VERSION ""

NS_ :

BS_:

BU_: External_Tool ADAS RDR05 RDR_Fusion_Partner RDR_Gateway

BO_ 267 RDR_FUSION_DET_045_048: 64 RDR_Fusion_Partner
 SG_ DET_RANGE_045_Rx : 24|15@1+ (0.015625,0) [0|500] "m"  RDR05
 SG_ DET_RANGE_ERR_045_Rx : 40|7@1+ (0.0075,0) [0|0.9525] "m"  RDR05
 SG_ DET_RANGE_VELOCITY_045_Rx : 48|15@1+ (0.0078125,-128) [-128|127.9921875] "m/s"  RDR05
 SG_ DET_RANGE_VELOCITY_ERR_045_Rx : 64|8@1+ (0.003,0) [0|0.765] "m/s"  RDR05
 SG_ DET_AZIMUTH_045_Rx : 88|13@1+ (0.0004,-1.5708) [-1.5708|1.5708] "rad"  RDR05
 SG_ DET_AZIMUTH_ERR_045_Rx : 105|7@1+ (0.00087267,0) [0|0.11082909] "rad"  RDR05
 SG_ DET_ELEVATION_045_Rx : 72|8@1+ (0.00275,-0.34925) [-0.34925|0.34925] "rad"  RDR05
 SG_ DET_ELEVATION_ERR_045_Rx : 80|6@1+ (0.00174533,0) [0|0.10995579] "rad"  RDR05
 SG_ DET_RCS_045_Rx : 128|8@1+ (0.5,-64) [-64|63.5] "dBsm"  RDR05
 SG_ DET_BI_STATIC_FLAG_045_Rx : 104|1@1+ (1,0) [0|1] ""  RDR05
 SG_ DET_SUPER_RES_TARGET_045_Rx : 87|1@1+ (1,0) [0|1] ""  RDR05
 SG_ DET_SNR_045_Rx : 120|8@1+ (0.35156,0) [0|89.6478] "dB"  RDR05
 SG_ DET_EXISTENCE_PROB_045_Rx : 112|6@1+ (1.588,0) [0|100] "%"  RDR05
 SG_ DET_HVC_FLAG_045_Rx : 86|1@1+ (1,0) [0|1] ""  RDR05
 SG_ DET_CONFD_AZIMUTH_045_Rx : 118|2@1+ (1,0) [0|3] ""  RDR05
 SG_ DET_CONFD_ELEVATION_045_Rx : 101|2@1+ (1,0) [0|3] ""  RDR05
 SG_ DET_PROB_1STAZHYPO_045_Rx : 103|1@1+ (1,0) [0|1] ""  RDR05
 SG_ DET_IDM_045_Rx : 63|1@1+ (1,0) [0|1] ""  RDR05
 SG_ DET_MTD_045_Rx : 47|1@1+ (1,0) [0|1] ""  RDR05
 SG_ DET_BELOW_RAIN_THOLD_045_Rx : 39|1@1+ (1,0) [0|1] ""  RDR05
 SG_ DET_RANGE_046_Rx : 136|15@1+ (0.015625,0) [0|500] "m"  RDR05
 SG_ DET_RANGE_ERR_046_Rx : 152|7@1+ (0.0075,0) [0|0.9525] "m"  RDR05
 SG_ DET_RANGE_VELOCITY_046_Rx : 160|15@1+ (0.0078125,-128) [-128|127.9921875] "m/s"  RDR05
 SG_ DET_RANGE_VELOCITY_ERR_046_Rx : 176|8@1+ (0.003,0) [0|0.765] "m/s"  RDR05
 SG_ DET_AZIMUTH_046_Rx : 200|13@1+ (0.0004,-1.5708) [-1.5708|1.5708] "rad"  RDR05
 SG_ DET_AZIMUTH_ERR_046_Rx : 217|7@1+ (0.00087267,0) [0|0.11082909] "rad"  RDR05
 SG_ DET_ELEVATION_046_Rx : 184|8@1+ (0.00275,-0.34925) [-0.34925|0.34925] "rad"  RDR05
 SG_ DET_ELEVATION_ERR_046_Rx : 192|6@1+ (0.00174533,0) [0|0.10995579] "rad"  RDR05
 SG_ DET_RCS_046_Rx : 240|8@1+ (0.5,-64) [-64|63.5] "dBsm"  RDR05
 SG_ DET_BI_STATIC_FLAG_046_Rx : 216|1@1+ (1,0) [0|1] ""  RDR05
 SG_ DET_SUPER_RES_TARGET_046_Rx : 199|1@1+ (1,0) [0|1] ""  RDR05
 SG_ DET_SNR_046_Rx : 232|8@1+ (0.35156,0) [0|89.6478] "dB"  RDR05
 SG_ DET_EXISTENCE_PROB_046_Rx : 224|6@1+ (1.588,0) [0|100] "%"  RDR05
 SG_ DET_HVC_FLAG_046_Rx : 198|1@1+ (1,0) [0|1] ""  RDR05
 SG_ DET_CONFD_AZIMUTH_046_Rx : 230|2@1+ (1,0) [0|3] ""  RDR05
 SG_ DET_CONFD_ELEVATION_046_Rx : 213|2@1+ (1,0) [0|3] ""  RDR05
 SG_ DET_PROB_1STAZHYPO_046_Rx : 215|1@1+ (1,0) [0|1] ""  RDR05
 SG_ DET_IDM_046_Rx : 175|1@1+ (1,0) [0|1] ""  RDR05
 SG_ DET_MTD_046_Rx : 159|1@1+ (1,0) [0|1] ""  RDR05
 SG_ DET_BELOW_RAIN_THOLD_046_Rx : 151|1@1+ (1,0) [0|1] ""  RDR05
 SG_ DET_RANGE_047_Rx : 248|15@1+ (0.015625,0) [0|500] "m"  RDR05
 SG_ DET_RANGE_ERR_047_Rx : 264|7@1+ (0.0075,0) [0|0.9525] "m"  RDR05
 SG_ DET_RANGE_VELOCITY_047_Rx : 272|15@1+ (0.0078125,-128) [-128|127.9921875] "m/s"  RDR05
 SG_ DET_RANGE_VELOCITY_ERR_047_Rx : 288|8@1+ (0.003,0) [0|0.765] "m/s"  RDR05
 SG_ DET_AZIMUTH_047_Rx : 312|13@1+ (0.0004,-1.5708) [-1.5708|1.5708] "rad"  RDR05
 SG_ DET_AZIMUTH_ERR_047_Rx : 329|7@1+ (0.00087267,0) [0|0.11082909] "rad"  RDR05
 SG_ DET_ELEVATION_047_Rx : 296|8@1+ (0.00275,-0.34925) [-0.34925|0.34925] "rad"  RDR05
 SG_ DET_ELEVATION_ERR_047_Rx : 304|6@1+ (0.00174533,0) [0|0.10995579] "rad"  RDR05
 SG_ DET_RCS_047_Rx : 352|8@1+ (0.5,-64) [-64|63.5] "dBsm"  RDR05
 SG_ DET_BI_STATIC_FLAG_047_Rx : 328|1@1+ (1,0) [0|1] ""  RDR05
 SG_ DET_SUPER_RES_TARGET_047_Rx : 311|1@1+ (1,0) [0|1] ""  RDR05
 SG_ DET_SNR_047_Rx : 344|8@1+ (0.35156,0) [0|89.6478] "dB"  RDR05
 SG_ DET_EXISTENCE_PROB_047_Rx : 336|6@1+ (1.588,0) [0|100] "%"  RDR05
 SG_ DET_HVC_FLAG_047_Rx : 310|1@1+ (1,0) [0|1] ""  RDR05
 SG_ DET_CONFD_AZIMUTH_047_Rx : 342|2@1+ (1,0) [0|3] ""  RDR05
 SG_ DET_CONFD_ELEVATION_047_Rx : 325|2@1+ (1,0) [0|3] ""  RDR05
 SG_ DET_PROB_1STAZHYPO_047_Rx : 327|1@1+ (1,0) [0|1] ""  RDR05
 SG_ DET_IDM_047_Rx : 287|1@1+ (1,0) [0|1] ""  RDR05
 SG_ DET_MTD_047_Rx : 271|1@1+ (1,0) [0|1] ""  RDR05
 SG_ DET_BELOW_RAIN_THOLD_047_Rx : 263|1@1+ (1,0) [0|1] ""  RDR05
 SG_ DET_RANGE_048_Rx : 360|15@1+ (0.015625,0) [0|500] "m"  RDR05
 SG_ DET_RANGE_ERR_048_Rx : 376|7@1+ (0.0075,0) [0|0.9525] "m"  RDR05
 SG_ DET_RANGE_VELOCITY_048_Rx : 384|15@1+ (0.0078125,-128) [-128|127.9921875] "m/s"  RDR05
 SG_ DET_RANGE_VELOCITY_ERR_048_Rx : 400|8@1+ (0.003,0) [0|0.765] "m/s"  RDR05
 SG_ DET_AZIMUTH_048_Rx : 424|13@1+ (0.0004,-1.5708) [-1.5708|1.5708] "rad"  RDR05
 SG_ DET_AZIMUTH_ERR_048_Rx : 441|7@1+ (0.00087267,0) [0|0.11082909] "rad"  RDR05
 SG_ DET_ELEVATION_048_Rx : 408|8@1+ (0.00275,-0.34925) [-0.34925|0.34925] "rad"  RDR05
 SG_ DET_ELEVATION_ERR_048_Rx : 416|6@1+ (0.00174533,0) [0|0.10995579] "rad"  RDR05
 SG_ DET_RCS_048_Rx : 464|8@1+ (0.5,-64) [-64|63.5] "dBsm"  RDR05
 SG_ DET_BI_STATIC_FLAG_048_Rx : 440|1@1+ (1,0) [0|1] ""  RDR05
 SG_ DET_SUPER_RES_TARGET_048_Rx : 423|1@1+ (1,0) [0|1] ""  RDR05
 SG_ DET_SNR_048_Rx : 456|8@1+ (0.35156,0) [0|89.6478] "dB"  RDR05
 SG_ DET_EXISTENCE_PROB_048_Rx : 448|6@1+ (1.588,0) [0|100] "%"  RDR05
 SG_ DET_HVC_FLAG_048_Rx : 422|1@1+ (1,0) [0|1] ""  RDR05
 SG_ DET_CONFD_AZIMUTH_048_Rx : 454|2@1+ (1,0) [0|3] ""  RDR05
 SG_ DET_CONFD_ELEVATION_048_Rx : 437|2@1+ (1,0) [0|3] ""  RDR05
 SG_ DET_MH_SCAN_INDEX_4LSB_045_048_R : 476|4@1+ (1,0) [0|15] ""  RDR05
 SG_ DET_MH_CYCLE_COUNTER_045_048_Rx : 16|8@1+ (1,0) [0|255] ""  RDR05
 SG_ DET_MH_CRC16_045_048_Rx : 0|16@1+ (1,0) [0|65535] ""  RDR05
 SG_ DET_PROB_1STAZHYPO_048_Rx : 439|1@1+ (1,0) [0|1] ""  RDR05
 SG_ DET_IDM_048_Rx : 399|1@1+ (1,0) [0|1] ""  RDR05
 SG_ DET_MTD_048_Rx : 383|1@1+ (1,0) [0|1] ""  RDR05
 SG_ DET_BELOW_RAIN_THOLD_048_Rx : 375|1@1+ (1,0) [0|1] ""  RDR05

BO_ 268 RDR_FUSION_DET_049_052: 64 RDR_Fusion_Partner
 SG_ DET_RANGE_049_Rx : 24|15@1+ (0.015625,0) [0|500] "m"  RDR05
 SG_ DET_RANGE_ERR_049_Rx : 40|7@1+ (0.0075,0) [0|0.9525] "m"  RDR05
 SG_ DET_RANGE_VELOCITY_049_Rx : 48|15@1+ (0.0078125,-128) [-128|127.9921875] "m/s"  RDR05
 SG_ DET_RANGE_VELOCITY_ERR_049_Rx : 64|8@1+ (0.003,0) [0|0.765] "m/s"  RDR05
 SG_ DET_AZIMUTH_049_Rx : 88|13@1+ (0.0004,-1.5708) [-1.5708|1.5708] "rad"  RDR05
 SG_ DET_AZIMUTH_ERR_049_Rx : 105|7@1+ (0.00087267,0) [0|0.11082909] "rad"  RDR05
 SG_ DET_ELEVATION_049_Rx : 72|8@1+ (0.00275,-0.34925) [-0.34925|0.34925] "rad"  RDR05
 SG_ DET_ELEVATION_ERR_049_Rx : 80|6@1+ (0.00174533,0) [0|0.10995579] "rad"  RDR05
 SG_ DET_RCS_049_Rx : 128|8@1+ (0.5,-64) [-64|63.5] "dBsm"  RDR05
 SG_ DET_BI_STATIC_FLAG_049_Rx : 104|1@1+ (1,0) [0|1] ""  RDR05
 SG_ DET_SUPER_RES_TARGET_049_Rx : 87|1@1+ (1,0) [0|1] ""  RDR05
 SG_ DET_SNR_049_Rx : 120|8@1+ (0.35156,0) [0|89.6478] "dB"  RDR05
 SG_ DET_EXISTENCE_PROB_049_Rx : 112|6@1+ (1.588,0) [0|100] "%"  RDR05
 SG_ DET_HVC_FLAG_049_Rx : 86|1@1+ (1,0) [0|1] ""  RDR05
 SG_ DET_CONFD_AZIMUTH_049_Rx : 118|2@1+ (1,0) [0|3] ""  RDR05
 SG_ DET_CONFD_ELEVATION_049_Rx : 101|2@1+ (1,0) [0|3] ""  RDR05
 SG_ DET_PROB_1STAZHYPO_049_Rx : 103|1@1+ (1,0) [0|1] ""  RDR05
 SG_ DET_IDM_049_Rx : 63|1@1+ (1,0) [0|1] ""  RDR05
 SG_ DET_MTD_049_Rx : 47|1@1+ (1,0) [0|1] ""  RDR05
 SG_ DET_BELOW_RAIN_THOLD_049_Rx : 39|1@1+ (1,0) [0|1] ""  RDR05
 SG_ DET_RANGE_050_Rx : 136|15@1+ (0.015625,0) [0|500] "m"  RDR05
 SG_ DET_RANGE_ERR_050_Rx : 152|7@1+ (0.0075,0) [0|0.9525] "m"  RDR05
 SG_ DET_RANGE_VELOCITY_050_Rx : 160|15@1+ (0.0078125,-128) [-128|127.9921875] "m/s"  RDR05
 SG_ DET_RANGE_VELOCITY_ERR_050_Rx : 176|8@1+ (0.003,0) [0|0.765] "m/s"  RDR05
 SG_ DET_AZIMUTH_050_Rx : 200|13@1+ (0.0004,-1.5708) [-1.5708|1.5708] "rad"  RDR05
 SG_ DET_AZIMUTH_ERR_050_Rx : 217|7@1+ (0.00087267,0) [0|0.11082909] "rad"  RDR05
 SG_ DET_ELEVATION_050_Rx : 184|8@1+ (0.00275,-0.34925) [-0.34925|0.34925] "rad"  RDR05
 SG_ DET_ELEVATION_ERR_050_Rx : 192|6@1+ (0.00174533,0) [0|0.10995579] "rad"  RDR05
 SG_ DET_RCS_050_Rx : 240|8@1+ (0.5,-64) [-64|63.5] "dBsm"  RDR05
 SG_ DET_BI_STATIC_FLAG_050_Rx : 216|1@1+ (1,0) [0|1] ""  RDR05
 SG_ DET_SUPER_RES_TARGET_050_Rx : 199|1@1+ (1,0) [0|1] ""  RDR05
 SG_ DET_SNR_050_Rx : 232|8@1+ (0.35156,0) [0|89.6478] "dB"  RDR05
 SG_ DET_EXISTENCE_PROB_050_Rx : 224|6@1+ (1.588,0) [0|100] "%"  RDR05
 SG_ DET_HVC_FLAG_050_Rx : 198|1@1+ (1,0) [0|1] ""  RDR05
 SG_ DET_CONFD_AZIMUTH_050_Rx : 230|2@1+ (1,0) [0|3] ""  RDR05
 SG_ DET_CONFD_ELEVATION_050_Rx : 213|2@1+ (1,0) [0|3] ""  RDR05
 SG_ DET_PROB_1STAZHYPO_050_Rx : 215|1@1+ (1,0) [0|1] ""  RDR05
 SG_ DET_IDM_050_Rx : 175|1@1+ (1,0) [0|1] ""  RDR05
 SG_ DET_MTD_050_Rx : 159|1@1+ (1,0) [0|1] ""  RDR05
 SG_ DET_BELOW_RAIN_THOLD_050_Rx : 151|1@1+ (1,0) [0|1] ""  RDR05
 SG_ DET_RANGE_051_Rx : 248|15@1+ (0.015625,0) [0|500] "m"  RDR05
 SG_ DET_RANGE_ERR_051_Rx : 264|7@1+ (0.0075,0) [0|0.9525] "m"  RDR05
 SG_ DET_RANGE_VELOCITY_051_Rx : 272|15@1+ (0.0078125,-128) [-128|127.9921875] "m/s"  RDR05
 SG_ DET_RANGE_VELOCITY_ERR_051_Rx : 288|8@1+ (0.003,0) [0|0.765] "m/s"  RDR05
 SG_ DET_AZIMUTH_051_Rx : 312|13@1+ (0.0004,-1.5708) [-1.5708|1.5708] "rad"  RDR05
 SG_ DET_AZIMUTH_ERR_051_Rx : 329|7@1+ (0.00087267,0) [0|0.11082909] "rad"  RDR05
 SG_ DET_ELEVATION_051_Rx : 296|8@1+ (0.00275,-0.34925) [-0.34925|0.34925] "rad"  RDR05
 SG_ DET_ELEVATION_ERR_051_Rx : 304|6@1+ (0.00174533,0) [0|0.10995579] "rad"  RDR05
 SG_ DET_RCS_051_Rx : 352|8@1+ (0.5,-64) [-64|63.5] "dBsm"  RDR05
 SG_ DET_BI_STATIC_FLAG_051_Rx : 328|1@1+ (1,0) [0|1] ""  RDR05
 SG_ DET_SUPER_RES_TARGET_051_Rx : 311|1@1+ (1,0) [0|1] ""  RDR05
 SG_ DET_SNR_051_Rx : 344|8@1+ (0.35156,0) [0|89.6478] "dB"  RDR05
 SG_ DET_EXISTENCE_PROB_051_Rx : 336|6@1+ (1.588,0) [0|100] "%"  RDR05
 SG_ DET_HVC_FLAG_051_Rx : 310|1@1+ (1,0) [0|1] ""  RDR05
 SG_ DET_CONFD_AZIMUTH_051_Rx : 342|2@1+ (1,0) [0|3] ""  RDR05
 SG_ DET_CONFD_ELEVATION_051_Rx : 325|2@1+ (1,0) [0|3] ""  RDR05
 SG_ DET_PROB_1STAZHYPO_051_Rx : 327|1@1+ (1,0) [0|1] ""  RDR05
 SG_ DET_IDM_051_Rx : 287|1@1+ (1,0) [0|1] ""  RDR05
 SG_ DET_MTD_051_Rx : 271|1@1+ (1,0) [0|1] ""  RDR05
 SG_ DET_BELOW_RAIN_THOLD_051_Rx : 263|1@1+ (1,0) [0|1] ""  RDR05
 SG_ DET_RANGE_052_Rx : 360|15@1+ (0.015625,0) [0|500] "m"  RDR05
 SG_ DET_RANGE_ERR_052_Rx : 376|7@1+ (0.0075,0) [0|0.9525] "m"  RDR05
 SG_ DET_RANGE_VELOCITY_052_Rx : 384|15@1+ (0.0078125,-128) [-128|127.9921875] "m/s"  RDR05
 SG_ DET_RANGE_VELOCITY_ERR_052_Rx : 400|8@1+ (0.003,0) [0|0.765] "m/s"  RDR05
 SG_ DET_AZIMUTH_052_Rx : 424|13@1+ (0.0004,-1.5708) [-1.5708|1.5708] "rad"  RDR05
 SG_ DET_AZIMUTH_ERR_052_Rx : 441|7@1+ (0.00087267,0) [0|0.11082909] "rad"  RDR05
 SG_ DET_ELEVATION_052_Rx : 408|8@1+ (0.00275,-0.34925) [-0.34925|0.34925] "rad"  RDR05
 SG_ DET_ELEVATION_ERR_052_Rx : 416|6@1+ (0.00174533,0) [0|0.10995579] "rad"  RDR05
 SG_ DET_RCS_052_Rx : 464|8@1+ (0.5,-64) [-64|63.5] "dBsm"  RDR05
 SG_ DET_BI_STATIC_FLAG_052_Rx : 440|1@1+ (1,0) [0|1] ""  RDR05
 SG_ DET_SUPER_RES_TARGET_052_Rx : 423|1@1+ (1,0) [0|1] ""  RDR05
 SG_ DET_SNR_052_Rx : 456|8@1+ (0.35156,0) [0|89.6478] "dB"  RDR05
 SG_ DET_EXISTENCE_PROB_052_Rx : 448|6@1+ (1.588,0) [0|100] "%"  RDR05
 SG_ DET_HVC_FLAG_052_Rx : 422|1@1+ (1,0) [0|1] ""  RDR05
 SG_ DET_CONFD_AZIMUTH_052_Rx : 454|2@1+ (1,0) [0|3] ""  RDR05
 SG_ DET_CONFD_ELEVATION_052_Rx : 437|2@1+ (1,0) [0|3] ""  RDR05
 SG_ DET_MH_SCAN_INDEX_4LSB_049_052_R : 476|4@1+ (1,0) [0|15] ""  RDR05
 SG_ DET_MH_CYCLE_COUNTER_049_052_Rx : 16|8@1+ (1,0) [0|255] ""  RDR05
 SG_ DET_MH_CRC16_049_052_Rx : 0|16@1+ (1,0) [0|65535] ""  RDR05
 SG_ DET_PROB_1STAZHYPO_052_Rx : 439|1@1+ (1,0) [0|1] ""  RDR05
 SG_ DET_IDM_052_Rx : 399|1@1+ (1,0) [0|1] ""  RDR05
 SG_ DET_MTD_052_Rx : 383|1@1+ (1,0) [0|1] ""  RDR05
 SG_ DET_BELOW_RAIN_THOLD_052_Rx : 375|1@1+ (1,0) [0|1] ""  RDR05

BO_ 269 RDR_FUSION_DET_053_056: 64 RDR_Fusion_Partner
 SG_ DET_RANGE_053_Rx : 24|15@1+ (0.015625,0) [0|500] "m"  RDR05
 SG_ DET_RANGE_ERR_053_Rx : 40|7@1+ (0.0075,0) [0|0.9525] "m"  RDR05
 SG_ DET_RANGE_VELOCITY_053_Rx : 48|15@1+ (0.0078125,-128) [-128|127.9921875] "m/s"  RDR05
 SG_ DET_RANGE_VELOCITY_ERR_053_Rx : 64|8@1+ (0.003,0) [0|0.765] "m/s"  RDR05
 SG_ DET_AZIMUTH_053_Rx : 88|13@1+ (0.0004,-1.5708) [-1.5708|1.5708] "rad"  RDR05
 SG_ DET_AZIMUTH_ERR_053_Rx : 105|7@1+ (0.00087267,0) [0|0.11082909] "rad"  RDR05
 SG_ DET_ELEVATION_053_Rx : 72|8@1+ (0.00275,-0.34925) [-0.34925|0.34925] "rad"  RDR05
 SG_ DET_ELEVATION_ERR_053_Rx : 80|6@1+ (0.00174533,0) [0|0.10995579] "rad"  RDR05
 SG_ DET_RCS_053_Rx : 128|8@1+ (0.5,-64) [-64|63.5] "dBsm"  RDR05
 SG_ DET_BI_STATIC_FLAG_053_Rx : 104|1@1+ (1,0) [0|1] ""  RDR05
 SG_ DET_SUPER_RES_TARGET_053_Rx : 87|1@1+ (1,0) [0|1] ""  RDR05
 SG_ DET_SNR_053_Rx : 120|8@1+ (0.35156,0) [0|89.6478] "dB"  RDR05
 SG_ DET_EXISTENCE_PROB_053_Rx : 112|6@1+ (1.588,0) [0|100] "%"  RDR05
 SG_ DET_HVC_FLAG_053_Rx : 86|1@1+ (1,0) [0|1] ""  RDR05
 SG_ DET_CONFD_AZIMUTH_053_Rx : 118|2@1+ (1,0) [0|3] ""  RDR05
 SG_ DET_CONFD_ELEVATION_053_Rx : 101|2@1+ (1,0) [0|3] ""  RDR05
 SG_ DET_PROB_1STAZHYPO_053_Rx : 103|1@1+ (1,0) [0|1] ""  RDR05
 SG_ DET_IDM_053_Rx : 63|1@1+ (1,0) [0|1] ""  RDR05
 SG_ DET_MTD_053_Rx : 47|1@1+ (1,0) [0|1] ""  RDR05
 SG_ DET_BELOW_RAIN_THOLD_053_Rx : 39|1@1+ (1,0) [0|1] ""  RDR05
 SG_ DET_RANGE_054_Rx : 136|15@1+ (0.015625,0) [0|500] "m"  RDR05
 SG_ DET_RANGE_ERR_054_Rx : 152|7@1+ (0.0075,0) [0|0.9525] "m"  RDR05
 SG_ DET_RANGE_VELOCITY_054_Rx : 160|15@1+ (0.0078125,-128) [-128|127.9921875] "m/s"  RDR05
 SG_ DET_RANGE_VELOCITY_ERR_054_Rx : 176|8@1+ (0.003,0) [0|0.765] "m/s"  RDR05
 SG_ DET_AZIMUTH_054_Rx : 200|13@1+ (0.0004,-1.5708) [-1.5708|1.5708] "rad"  RDR05
 SG_ DET_AZIMUTH_ERR_054_Rx : 217|7@1+ (0.00087267,0) [0|0.11082909] "rad"  RDR05
 SG_ DET_ELEVATION_054_Rx : 184|8@1+ (0.00275,-0.34925) [-0.34925|0.34925] "rad"  RDR05
 SG_ DET_ELEVATION_ERR_054_Rx : 192|6@1+ (0.00174533,0) [0|0.10995579] "rad"  RDR05
 SG_ DET_RCS_054_Rx : 240|8@1+ (0.5,-64) [-64|63.5] "dBsm"  RDR05
 SG_ DET_BI_STATIC_FLAG_054_Rx : 216|1@1+ (1,0) [0|1] ""  RDR05
 SG_ DET_SUPER_RES_TARGET_054_Rx : 199|1@1+ (1,0) [0|1] ""  RDR05
 SG_ DET_SNR_054_Rx : 232|8@1+ (0.35156,0) [0|89.6478] "dB"  RDR05
 SG_ DET_EXISTENCE_PROB_054_Rx : 224|6@1+ (1.588,0) [0|100] "%"  RDR05
 SG_ DET_HVC_FLAG_054_Rx : 198|1@1+ (1,0) [0|1] ""  RDR05
 SG_ DET_CONFD_AZIMUTH_054_Rx : 230|2@1+ (1,0) [0|3] ""  RDR05
 SG_ DET_CONFD_ELEVATION_054_Rx : 213|2@1+ (1,0) [0|3] ""  RDR05
 SG_ DET_PROB_1STAZHYPO_054_Rx : 215|1@1+ (1,0) [0|1] ""  RDR05
 SG_ DET_IDM_054_Rx : 175|1@1+ (1,0) [0|1] ""  RDR05
 SG_ DET_MTD_054_Rx : 159|1@1+ (1,0) [0|1] ""  RDR05
 SG_ DET_BELOW_RAIN_THOLD_054_Rx : 151|1@1+ (1,0) [0|1] ""  RDR05
 SG_ DET_RANGE_055_Rx : 248|15@1+ (0.015625,0) [0|500] "m"  RDR05
 SG_ DET_RANGE_ERR_055_Rx : 264|7@1+ (0.0075,0) [0|0.9525] "m"  RDR05
 SG_ DET_RANGE_VELOCITY_055_Rx : 272|15@1+ (0.0078125,-128) [-128|127.9921875] "m/s"  RDR05
 SG_ DET_RANGE_VELOCITY_ERR_055_Rx : 288|8@1+ (0.003,0) [0|0.765] "m/s"  RDR05
 SG_ DET_AZIMUTH_055_Rx : 312|13@1+ (0.0004,-1.5708) [-1.5708|1.5708] "rad"  RDR05
 SG_ DET_AZIMUTH_ERR_055_Rx : 329|7@1+ (0.00087267,0) [0|0.11082909] "rad"  RDR05
 SG_ DET_ELEVATION_055_Rx : 296|8@1+ (0.00275,-0.34925) [-0.34925|0.34925] "rad"  RDR05
 SG_ DET_ELEVATION_ERR_055_Rx : 304|6@1+ (0.00174533,0) [0|0.10995579] "rad"  RDR05
 SG_ DET_RCS_055_Rx : 352|8@1+ (0.5,-64) [-64|63.5] "dBsm"  RDR05
 SG_ DET_BI_STATIC_FLAG_055_Rx : 328|1@1+ (1,0) [0|1] ""  RDR05
 SG_ DET_SUPER_RES_TARGET_055_Rx : 311|1@1+ (1,0) [0|1] ""  RDR05
 SG_ DET_SNR_055_Rx : 344|8@1+ (0.35156,0) [0|89.6478] "dB"  RDR05
 SG_ DET_EXISTENCE_PROB_055_Rx : 336|6@1+ (1.588,0) [0|100] "%"  RDR05
 SG_ DET_HVC_FLAG_055_Rx : 310|1@1+ (1,0) [0|1] ""  RDR05
 SG_ DET_CONFD_AZIMUTH_055_Rx : 342|2@1+ (1,0) [0|3] ""  RDR05
 SG_ DET_CONFD_ELEVATION_055_Rx : 325|2@1+ (1,0) [0|3] ""  RDR05
 SG_ DET_PROB_1STAZHYPO_055_Rx : 327|1@1+ (1,0) [0|1] ""  RDR05
 SG_ DET_IDM_055_Rx : 287|1@1+ (1,0) [0|1] ""  RDR05
 SG_ DET_MTD_055_Rx : 271|1@1+ (1,0) [0|1] ""  RDR05
 SG_ DET_BELOW_RAIN_THOLD_055_Rx : 263|1@1+ (1,0) [0|1] ""  RDR05
 SG_ DET_RANGE_056_Rx : 360|15@1+ (0.015625,0) [0|500] "m"  RDR05
 SG_ DET_RANGE_ERR_056_Rx : 376|7@1+ (0.0075,0) [0|0.9525] "m"  RDR05
 SG_ DET_RANGE_VELOCITY_056_Rx : 384|15@1+ (0.0078125,-128) [-128|127.9921875] "m/s"  RDR05
 SG_ DET_RANGE_VELOCITY_ERR_056_Rx : 400|8@1+ (0.003,0) [0|0.765] "m/s"  RDR05
 SG_ DET_AZIMUTH_056_Rx : 424|13@1+ (0.0004,-1.5708) [-1.5708|1.5708] "rad"  RDR05
 SG_ DET_AZIMUTH_ERR_056_Rx : 441|7@1+ (0.00087267,0) [0|0.11082909] "rad"  RDR05
 SG_ DET_ELEVATION_056_Rx : 408|8@1+ (0.00275,-0.34925) [-0.34925|0.34925] "rad"  RDR05
 SG_ DET_ELEVATION_ERR_056_Rx : 416|6@1+ (0.00174533,0) [0|0.10995579] "rad"  RDR05
 SG_ DET_RCS_056_Rx : 464|8@1+ (0.5,-64) [-64|63.5] "dBsm"  RDR05
 SG_ DET_BI_STATIC_FLAG_056_Rx : 440|1@1+ (1,0) [0|1] ""  RDR05
 SG_ DET_SUPER_RES_TARGET_056_Rx : 423|1@1+ (1,0) [0|1] ""  RDR05
 SG_ DET_SNR_056_Rx : 456|8@1+ (0.35156,0) [0|89.6478] "dB"  RDR05
 SG_ DET_EXISTENCE_PROB_056_Rx : 448|6@1+ (1.588,0) [0|100] "%"  RDR05
 SG_ DET_HVC_FLAG_056_Rx : 422|1@1+ (1,0) [0|1] ""  RDR05
 SG_ DET_CONFD_AZIMUTH_056_Rx : 454|2@1+ (1,0) [0|3] ""  RDR05
 SG_ DET_CONFD_ELEVATION_056_Rx : 437|2@1+ (1,0) [0|3] ""  RDR05
 SG_ DET_MH_SCAN_INDEX_4LSB_053_056_R : 476|4@1+ (1,0) [0|15] ""  RDR05
 SG_ DET_MH_CYCLE_COUNTER_053_056_Rx : 16|8@1+ (1,0) [0|255] ""  RDR05
 SG_ DET_MH_CRC16_053_056_Rx : 0|16@1+ (1,0) [0|65535] ""  RDR05
 SG_ DET_PROB_1STAZHYPO_056_Rx : 439|1@1+ (1,0) [0|1] ""  RDR05
 SG_ DET_IDM_056_Rx : 399|1@1+ (1,0) [0|1] ""  RDR05
 SG_ DET_MTD_056_Rx : 383|1@1+ (1,0) [0|1] ""  RDR05
 SG_ DET_BELOW_RAIN_THOLD_056_Rx : 375|1@1+ (1,0) [0|1] ""  RDR05

BO_ 270 RDR_FUSION_DET_057_060: 64 RDR_Fusion_Partner
 SG_ DET_RANGE_057_Rx : 24|15@1+ (0.015625,0) [0|500] "m"  RDR05
 SG_ DET_RANGE_ERR_057_Rx : 40|7@1+ (0.0075,0) [0|0.9525] "m"  RDR05
 SG_ DET_RANGE_VELOCITY_057_Rx : 48|15@1+ (0.0078125,-128) [-128|127.9921875] "m/s"  RDR05
 SG_ DET_RANGE_VELOCITY_ERR_057_Rx : 64|8@1+ (0.003,0) [0|0.765] "m/s"  RDR05
 SG_ DET_AZIMUTH_057_Rx : 88|13@1+ (0.0004,-1.5708) [-1.5708|1.5708] "rad"  RDR05
 SG_ DET_AZIMUTH_ERR_057_Rx : 105|7@1+ (0.00087267,0) [0|0.11082909] "rad"  RDR05
 SG_ DET_ELEVATION_057_Rx : 72|8@1+ (0.00275,-0.34925) [-0.34925|0.34925] "rad"  RDR05
 SG_ DET_ELEVATION_ERR_057_Rx : 80|6@1+ (0.00174533,0) [0|0.10995579] "rad"  RDR05
 SG_ DET_RCS_057_Rx : 128|8@1+ (0.5,-64) [-64|63.5] "dBsm"  RDR05
 SG_ DET_BI_STATIC_FLAG_057_Rx : 104|1@1+ (1,0) [0|1] ""  RDR05
 SG_ DET_SUPER_RES_TARGET_057_Rx : 87|1@1+ (1,0) [0|1] ""  RDR05
 SG_ DET_SNR_057_Rx : 120|8@1+ (0.35156,0) [0|89.6478] "dB"  RDR05
 SG_ DET_EXISTENCE_PROB_057_Rx : 112|6@1+ (1.588,0) [0|100] "%"  RDR05
 SG_ DET_HVC_FLAG_057_Rx : 86|1@1+ (1,0) [0|1] ""  RDR05
 SG_ DET_CONFD_AZIMUTH_057_Rx : 118|2@1+ (1,0) [0|3] ""  RDR05
 SG_ DET_CONFD_ELEVATION_057_Rx : 101|2@1+ (1,0) [0|3] ""  RDR05
 SG_ DET_PROB_1STAZHYPO_057_Rx : 103|1@1+ (1,0) [0|1] ""  RDR05
 SG_ DET_IDM_057_Rx : 63|1@1+ (1,0) [0|1] ""  RDR05
 SG_ DET_MTD_057_Rx : 47|1@1+ (1,0) [0|1] ""  RDR05
 SG_ DET_BELOW_RAIN_THOLD_057_Rx : 39|1@1+ (1,0) [0|1] ""  RDR05
 SG_ DET_RANGE_058_Rx : 136|15@1+ (0.015625,0) [0|500] "m"  RDR05
 SG_ DET_RANGE_ERR_058_Rx : 152|7@1+ (0.0075,0) [0|0.9525] "m"  RDR05
 SG_ DET_RANGE_VELOCITY_058_Rx : 160|15@1+ (0.0078125,-128) [-128|127.9921875] "m/s"  RDR05
 SG_ DET_RANGE_VELOCITY_ERR_058_Rx : 176|8@1+ (0.003,0) [0|0.765] "m/s"  RDR05
 SG_ DET_AZIMUTH_058_Rx : 200|13@1+ (0.0004,-1.5708) [-1.5708|1.5708] "rad"  RDR05
 SG_ DET_AZIMUTH_ERR_058_Rx : 217|7@1+ (0.00087267,0) [0|0.11082909] "rad"  RDR05
 SG_ DET_ELEVATION_058_Rx : 184|8@1+ (0.00275,-0.34925) [-0.34925|0.34925] "rad"  RDR05
 SG_ DET_ELEVATION_ERR_058_Rx : 192|6@1+ (0.00174533,0) [0|0.10995579] "rad"  RDR05
 SG_ DET_RCS_058_Rx : 240|8@1+ (0.5,-64) [-64|63.5] "dBsm"  RDR05
 SG_ DET_BI_STATIC_FLAG_058_Rx : 216|1@1+ (1,0) [0|1] ""  RDR05
 SG_ DET_SUPER_RES_TARGET_058_Rx : 199|1@1+ (1,0) [0|1] ""  RDR05
 SG_ DET_SNR_058_Rx : 232|8@1+ (0.35156,0) [0|89.6478] "dB"  RDR05
 SG_ DET_EXISTENCE_PROB_058_Rx : 224|6@1+ (1.588,0) [0|100] "%"  RDR05
 SG_ DET_HVC_FLAG_058_Rx : 198|1@1+ (1,0) [0|1] ""  RDR05
 SG_ DET_CONFD_AZIMUTH_058_Rx : 230|2@1+ (1,0) [0|3] ""  RDR05
 SG_ DET_CONFD_ELEVATION_058_Rx : 213|2@1+ (1,0) [0|3] ""  RDR05
 SG_ DET_PROB_1STAZHYPO_058_Rx : 215|1@1+ (1,0) [0|1] ""  RDR05
 SG_ DET_IDM_058_Rx : 175|1@1+ (1,0) [0|1] ""  RDR05
 SG_ DET_MTD_058_Rx : 159|1@1+ (1,0) [0|1] ""  RDR05
 SG_ DET_BELOW_RAIN_THOLD_058_Rx : 151|1@1+ (1,0) [0|1] ""  RDR05
 SG_ DET_RANGE_059_Rx : 248|15@1+ (0.015625,0) [0|500] "m"  RDR05
 SG_ DET_RANGE_ERR_059_Rx : 264|7@1+ (0.0075,0) [0|0.9525] "m"  RDR05
 SG_ DET_RANGE_VELOCITY_059_Rx : 272|15@1+ (0.0078125,-128) [-128|127.9921875] "m/s"  RDR05
 SG_ DET_RANGE_VELOCITY_ERR_059_Rx : 288|8@1+ (0.003,0) [0|0.765] "m/s"  RDR05
 SG_ DET_AZIMUTH_059_Rx : 312|13@1+ (0.0004,-1.5708) [-1.5708|1.5708] "rad"  RDR05
 SG_ DET_AZIMUTH_ERR_059_Rx : 329|7@1+ (0.00087267,0) [0|0.11082909] "rad"  RDR05
 SG_ DET_ELEVATION_059_Rx : 296|8@1+ (0.00275,-0.34925) [-0.34925|0.34925] "rad"  RDR05
 SG_ DET_ELEVATION_ERR_059_Rx : 304|6@1+ (0.00174533,0) [0|0.10995579] "rad"  RDR05
 SG_ DET_RCS_059_Rx : 352|8@1+ (0.5,-64) [-64|63.5] "dBsm"  RDR05
 SG_ DET_BI_STATIC_FLAG_059_Rx : 328|1@1+ (1,0) [0|1] ""  RDR05
 SG_ DET_SUPER_RES_TARGET_059_Rx : 311|1@1+ (1,0) [0|1] ""  RDR05
 SG_ DET_SNR_059_Rx : 344|8@1+ (0.35156,0) [0|89.6478] "dB"  RDR05
 SG_ DET_EXISTENCE_PROB_059_Rx : 336|6@1+ (1.588,0) [0|100] "%"  RDR05
 SG_ DET_HVC_FLAG_059_Rx : 310|1@1+ (1,0) [0|1] ""  RDR05
 SG_ DET_CONFD_AZIMUTH_059_Rx : 342|2@1+ (1,0) [0|3] ""  RDR05
 SG_ DET_CONFD_ELEVATION_059_Rx : 325|2@1+ (1,0) [0|3] ""  RDR05
 SG_ DET_PROB_1STAZHYPO_059_Rx : 327|1@1+ (1,0) [0|1] ""  RDR05
 SG_ DET_IDM_059_Rx : 287|1@1+ (1,0) [0|1] ""  RDR05
 SG_ DET_MTD_059_Rx : 271|1@1+ (1,0) [0|1] ""  RDR05
 SG_ DET_BELOW_RAIN_THOLD_059_Rx : 263|1@1+ (1,0) [0|1] ""  RDR05
 SG_ DET_RANGE_060_Rx : 360|15@1+ (0.015625,0) [0|500] "m"  RDR05
 SG_ DET_RANGE_ERR_060_Rx : 376|7@1+ (0.0075,0) [0|0.9525] "m"  RDR05
 SG_ DET_RANGE_VELOCITY_060_Rx : 384|15@1+ (0.0078125,-128) [-128|127.9921875] "m/s"  RDR05
 SG_ DET_RANGE_VELOCITY_ERR_060_Rx : 400|8@1+ (0.003,0) [0|0.765] "m/s"  RDR05
 SG_ DET_AZIMUTH_060_Rx : 424|13@1+ (0.0004,-1.5708) [-1.5708|1.5708] "rad"  RDR05
 SG_ DET_AZIMUTH_ERR_060_Rx : 441|7@1+ (0.00087267,0) [0|0.11082909] "rad"  RDR05
 SG_ DET_ELEVATION_060_Rx : 408|8@1+ (0.00275,-0.34925) [-0.34925|0.34925] "rad"  RDR05
 SG_ DET_ELEVATION_ERR_060_Rx : 416|6@1+ (0.00174533,0) [0|0.10995579] "rad"  RDR05
 SG_ DET_RCS_060_Rx : 464|8@1+ (0.5,-64) [-64|63.5] "dBsm"  RDR05
 SG_ DET_BI_STATIC_FLAG_060_Rx : 440|1@1+ (1,0) [0|1] ""  RDR05
 SG_ DET_SUPER_RES_TARGET_060_Rx : 423|1@1+ (1,0) [0|1] ""  RDR05
 SG_ DET_SNR_060_Rx : 456|8@1+ (0.35156,0) [0|89.6478] "dB"  RDR05
 SG_ DET_EXISTENCE_PROB_060_Rx : 448|6@1+ (1.588,0) [0|100] "%"  RDR05
 SG_ DET_HVC_FLAG_060_Rx : 422|1@1+ (1,0) [0|1] ""  RDR05
 SG_ DET_CONFD_AZIMUTH_060_Rx : 454|2@1+ (1,0) [0|3] ""  RDR05
 SG_ DET_CONFD_ELEVATION_060_Rx : 437|2@1+ (1,0) [0|3] ""  RDR05
 SG_ DET_MH_SCAN_INDEX_4LSB_057_060_R : 476|4@1+ (1,0) [0|15] ""  RDR05
 SG_ DET_MH_CYCLE_COUNTER_057_060_Rx : 16|8@1+ (1,0) [0|255] ""  RDR05
 SG_ DET_MH_CRC16_057_060_Rx : 0|16@1+ (1,0) [0|65535] ""  RDR05
 SG_ DET_PROB_1STAZHYPO_060_Rx : 439|1@1+ (1,0) [0|1] ""  RDR05
 SG_ DET_IDM_060_Rx : 399|1@1+ (1,0) [0|1] ""  RDR05
 SG_ DET_MTD_060_Rx : 383|1@1+ (1,0) [0|1] ""  RDR05
 SG_ DET_BELOW_RAIN_THOLD_060_Rx : 375|1@1+ (1,0) [0|1] ""  RDR05

BO_ 271 RDR_FUSION_DET_061_064: 64 RDR_Fusion_Partner
 SG_ DET_RANGE_061_Rx : 24|15@1+ (0.015625,0) [0|500] "m"  RDR05
 SG_ DET_RANGE_ERR_061_Rx : 40|7@1+ (0.0075,0) [0|0.9525] "m"  RDR05
 SG_ DET_RANGE_VELOCITY_061_Rx : 48|15@1+ (0.0078125,-128) [-128|127.9921875] "m/s"  RDR05
 SG_ DET_RANGE_VELOCITY_ERR_061_Rx : 64|8@1+ (0.003,0) [0|0.765] "m/s"  RDR05
 SG_ DET_AZIMUTH_061_Rx : 88|13@1+ (0.0004,-1.5708) [-1.5708|1.5708] "rad"  RDR05
 SG_ DET_AZIMUTH_ERR_061_Rx : 105|7@1+ (0.00087267,0) [0|0.11082909] "rad"  RDR05
 SG_ DET_ELEVATION_061_Rx : 72|8@1+ (0.00275,-0.34925) [-0.34925|0.34925] "rad"  RDR05
 SG_ DET_ELEVATION_ERR_061_Rx : 80|6@1+ (0.00174533,0) [0|0.10995579] "rad"  RDR05
 SG_ DET_RCS_061_Rx : 128|8@1+ (0.5,-64) [-64|63.5] "dBsm"  RDR05
 SG_ DET_BI_STATIC_FLAG_061_Rx : 104|1@1+ (1,0) [0|1] ""  RDR05
 SG_ DET_SUPER_RES_TARGET_061_Rx : 87|1@1+ (1,0) [0|1] ""  RDR05
 SG_ DET_SNR_061_Rx : 120|8@1+ (0.35156,0) [0|89.6478] "dB"  RDR05
 SG_ DET_EXISTENCE_PROB_061_Rx : 112|6@1+ (1.588,0) [0|100] "%"  RDR05
 SG_ DET_HVC_FLAG_061_Rx : 86|1@1+ (1,0) [0|1] ""  RDR05
 SG_ DET_CONFD_AZIMUTH_061_Rx : 118|2@1+ (1,0) [0|3] ""  RDR05
 SG_ DET_CONFD_ELEVATION_061_Rx : 101|2@1+ (1,0) [0|3] ""  RDR05
 SG_ DET_PROB_1STAZHYPO_061_Rx : 103|1@1+ (1,0) [0|1] ""  RDR05
 SG_ DET_IDM_061_Rx : 63|1@1+ (1,0) [0|1] ""  RDR05
 SG_ DET_MTD_061_Rx : 47|1@1+ (1,0) [0|1] ""  RDR05
 SG_ DET_BELOW_RAIN_THOLD_061_Rx : 39|1@1+ (1,0) [0|1] ""  RDR05
 SG_ DET_RANGE_062_Rx : 136|15@1+ (0.015625,0) [0|500] "m"  RDR05
 SG_ DET_RANGE_ERR_062_Rx : 152|7@1+ (0.0075,0) [0|0.9525] "m"  RDR05
 SG_ DET_RANGE_VELOCITY_062_Rx : 160|15@1+ (0.0078125,-128) [-128|127.9921875] "m/s"  RDR05
 SG_ DET_RANGE_VELOCITY_ERR_062_Rx : 176|8@1+ (0.003,0) [0|0.765] "m/s"  RDR05
 SG_ DET_AZIMUTH_062_Rx : 200|13@1+ (0.0004,-1.5708) [-1.5708|1.5708] "rad"  RDR05
 SG_ DET_AZIMUTH_ERR_062_Rx : 217|7@1+ (0.00087267,0) [0|0.11082909] "rad"  RDR05
 SG_ DET_ELEVATION_062_Rx : 184|8@1+ (0.00275,-0.34925) [-0.34925|0.34925] "rad"  RDR05
 SG_ DET_ELEVATION_ERR_062_Rx : 192|6@1+ (0.00174533,0) [0|0.10995579] "rad"  RDR05
 SG_ DET_RCS_062_Rx : 240|8@1+ (0.5,-64) [-64|63.5] "dBsm"  RDR05
 SG_ DET_BI_STATIC_FLAG_062_Rx : 216|1@1+ (1,0) [0|1] ""  RDR05
 SG_ DET_SUPER_RES_TARGET_062_Rx : 199|1@1+ (1,0) [0|1] ""  RDR05
 SG_ DET_SNR_062_Rx : 232|8@1+ (0.35156,0) [0|89.6478] "dB"  RDR05
 SG_ DET_EXISTENCE_PROB_062_Rx : 224|6@1+ (1.588,0) [0|100] "%"  RDR05
 SG_ DET_HVC_FLAG_062_Rx : 198|1@1+ (1,0) [0|1] ""  RDR05
 SG_ DET_CONFD_AZIMUTH_062_Rx : 230|2@1+ (1,0) [0|3] ""  RDR05
 SG_ DET_CONFD_ELEVATION_062_Rx : 213|2@1+ (1,0) [0|3] ""  RDR05
 SG_ DET_PROB_1STAZHYPO_062_Rx : 215|1@1+ (1,0) [0|1] ""  RDR05
 SG_ DET_IDM_062_Rx : 175|1@1+ (1,0) [0|1] ""  RDR05
 SG_ DET_MTD_062_Rx : 159|1@1+ (1,0) [0|1] ""  RDR05
 SG_ DET_BELOW_RAIN_THOLD_062_Rx : 151|1@1+ (1,0) [0|1] ""  RDR05
 SG_ DET_RANGE_063_Rx : 248|15@1+ (0.015625,0) [0|500] "m"  RDR05
 SG_ DET_RANGE_ERR_063_Rx : 264|7@1+ (0.0075,0) [0|0.9525] "m"  RDR05
 SG_ DET_RANGE_VELOCITY_063_Rx : 272|15@1+ (0.0078125,-128) [-128|127.9921875] "m/s"  RDR05
 SG_ DET_RANGE_VELOCITY_ERR_063_Rx : 288|8@1+ (0.003,0) [0|0.765] "m/s"  RDR05
 SG_ DET_AZIMUTH_063_Rx : 312|13@1+ (0.0004,-1.5708) [-1.5708|1.5708] "rad"  RDR05
 SG_ DET_AZIMUTH_ERR_063_Rx : 329|7@1+ (0.00087267,0) [0|0.11082909] "rad"  RDR05
 SG_ DET_ELEVATION_063_Rx : 296|8@1+ (0.00275,-0.34925) [-0.34925|0.34925] "rad"  RDR05
 SG_ DET_ELEVATION_ERR_063_Rx : 304|6@1+ (0.00174533,0) [0|0.10995579] "rad"  RDR05
 SG_ DET_RCS_063_Rx : 352|8@1+ (0.5,-64) [-64|63.5] "dBsm"  RDR05
 SG_ DET_BI_STATIC_FLAG_063_Rx : 328|1@1+ (1,0) [0|1] ""  RDR05
 SG_ DET_SUPER_RES_TARGET_063_Rx : 311|1@1+ (1,0) [0|1] ""  RDR05
 SG_ DET_SNR_063_Rx : 344|8@1+ (0.35156,0) [0|89.6478] "dB"  RDR05
 SG_ DET_EXISTENCE_PROB_063_Rx : 336|6@1+ (1.588,0) [0|100] "%"  RDR05
 SG_ DET_HVC_FLAG_063_Rx : 310|1@1+ (1,0) [0|1] ""  RDR05
 SG_ DET_CONFD_AZIMUTH_063_Rx : 342|2@1+ (1,0) [0|3] ""  RDR05
 SG_ DET_CONFD_ELEVATION_063_Rx : 325|2@1+ (1,0) [0|3] ""  RDR05
 SG_ DET_PROB_1STAZHYPO_063_Rx : 327|1@1+ (1,0) [0|1] ""  RDR05
 SG_ DET_IDM_063_Rx : 287|1@1+ (1,0) [0|1] ""  RDR05
 SG_ DET_MTD_063_Rx : 271|1@1+ (1,0) [0|1] ""  RDR05
 SG_ DET_BELOW_RAIN_THOLD_063_Rx : 263|1@1+ (1,0) [0|1] ""  RDR05
 SG_ DET_RANGE_064_Rx : 360|15@1+ (0.015625,0) [0|500] "m"  RDR05
 SG_ DET_RANGE_ERR_064_Rx : 376|7@1+ (0.0075,0) [0|0.9525] "m"  RDR05
 SG_ DET_RANGE_VELOCITY_064_Rx : 384|15@1+ (0.0078125,-128) [-128|127.9921875] "m/s"  RDR05
 SG_ DET_RANGE_VELOCITY_ERR_064_Rx : 400|8@1+ (0.003,0) [0|0.765] "m/s"  RDR05
 SG_ DET_AZIMUTH_064_Rx : 424|13@1+ (0.0004,-1.5708) [-1.5708|1.5708] "rad"  RDR05
 SG_ DET_AZIMUTH_ERR_064_Rx : 441|7@1+ (0.00087267,0) [0|0.11082909] "rad"  RDR05
 SG_ DET_ELEVATION_064_Rx : 408|8@1+ (0.00275,-0.34925) [-0.34925|0.34925] "rad"  RDR05
 SG_ DET_ELEVATION_ERR_064_Rx : 416|6@1+ (0.00174533,0) [0|0.10995579] "rad"  RDR05
 SG_ DET_RCS_064_Rx : 464|8@1+ (0.5,-64) [-64|63.5] "dBsm"  RDR05
 SG_ DET_BI_STATIC_FLAG_064_Rx : 440|1@1+ (1,0) [0|1] ""  RDR05
 SG_ DET_SUPER_RES_TARGET_064_Rx : 423|1@1+ (1,0) [0|1] ""  RDR05
 SG_ DET_SNR_064_Rx : 456|8@1+ (0.35156,0) [0|89.6478] "dB"  RDR05
 SG_ DET_EXISTENCE_PROB_064_Rx : 448|6@1+ (1.588,0) [0|100] "%"  RDR05
 SG_ DET_HVC_FLAG_064_Rx : 422|1@1+ (1,0) [0|1] ""  RDR05
 SG_ DET_CONFD_AZIMUTH_064_Rx : 454|2@1+ (1,0) [0|3] ""  RDR05
 SG_ DET_CONFD_ELEVATION_064_Rx : 437|2@1+ (1,0) [0|3] ""  RDR05
 SG_ DET_MH_SCAN_INDEX_4LSB_061_064_R : 476|4@1+ (1,0) [0|15] ""  RDR05
 SG_ DET_MH_CYCLE_COUNTER_061_064_Rx : 16|8@1+ (1,0) [0|255] ""  RDR05
 SG_ DET_MH_CRC16_061_064_Rx : 0|16@1+ (1,0) [0|65535] ""  RDR05
 SG_ DET_PROB_1STAZHYPO_064_Rx : 439|1@1+ (1,0) [0|1] ""  RDR05
 SG_ DET_IDM_064_Rx : 399|1@1+ (1,0) [0|1] ""  RDR05
 SG_ DET_MTD_064_Rx : 383|1@1+ (1,0) [0|1] ""  RDR05
 SG_ DET_BELOW_RAIN_THOLD_064_Rx : 375|1@1+ (1,0) [0|1] ""  RDR05

BO_ 272 RDR_FUSION_DET_065_068: 64 RDR_Fusion_Partner
 SG_ DET_RANGE_065_Rx : 24|15@1+ (0.015625,0) [0|500] "m"  RDR05
 SG_ DET_RANGE_ERR_065_Rx : 40|7@1+ (0.0075,0) [0|0.9525] "m"  RDR05
 SG_ DET_RANGE_VELOCITY_065_Rx : 48|15@1+ (0.0078125,-128) [-128|127.9921875] "m/s"  RDR05
 SG_ DET_RANGE_VELOCITY_ERR_065_Rx : 64|8@1+ (0.003,0) [0|0.765] "m/s"  RDR05
 SG_ DET_AZIMUTH_065_Rx : 88|13@1+ (0.0004,-1.5708) [-1.5708|1.5708] "rad"  RDR05
 SG_ DET_AZIMUTH_ERR_065_Rx : 105|7@1+ (0.00087267,0) [0|0.11082909] "rad"  RDR05
 SG_ DET_ELEVATION_065_Rx : 72|8@1+ (0.00275,-0.34925) [-0.34925|0.34925] "rad"  RDR05
 SG_ DET_ELEVATION_ERR_065_Rx : 80|6@1+ (0.00174533,0) [0|0.10995579] "rad"  RDR05
 SG_ DET_RCS_065_Rx : 128|8@1+ (0.5,-64) [-64|63.5] "dBsm"  RDR05
 SG_ DET_BI_STATIC_FLAG_065_Rx : 104|1@1+ (1,0) [0|1] ""  RDR05
 SG_ DET_SUPER_RES_TARGET_065_Rx : 87|1@1+ (1,0) [0|1] ""  RDR05
 SG_ DET_SNR_065_Rx : 120|8@1+ (0.35156,0) [0|89.6478] "dB"  RDR05
 SG_ DET_EXISTENCE_PROB_065_Rx : 112|6@1+ (1.588,0) [0|100] "%"  RDR05
 SG_ DET_HVC_FLAG_065_Rx : 86|1@1+ (1,0) [0|1] ""  RDR05
 SG_ DET_CONFD_AZIMUTH_065_Rx : 118|2@1+ (1,0) [0|3] ""  RDR05
 SG_ DET_CONFD_ELEVATION_065_Rx : 101|2@1+ (1,0) [0|3] ""  RDR05
 SG_ DET_PROB_1STAZHYPO_065_Rx : 103|1@1+ (1,0) [0|1] ""  RDR05
 SG_ DET_IDM_065_Rx : 63|1@1+ (1,0) [0|1] ""  RDR05
 SG_ DET_MTD_065_Rx : 47|1@1+ (1,0) [0|1] ""  RDR05
 SG_ DET_BELOW_RAIN_THOLD_065_Rx : 39|1@1+ (1,0) [0|1] ""  RDR05
 SG_ DET_RANGE_066_Rx : 136|15@1+ (0.015625,0) [0|500] "m"  RDR05
 SG_ DET_RANGE_ERR_066_Rx : 152|7@1+ (0.0075,0) [0|0.9525] "m"  RDR05
 SG_ DET_RANGE_VELOCITY_066_Rx : 160|15@1+ (0.0078125,-128) [-128|127.9921875] "m/s"  RDR05
 SG_ DET_RANGE_VELOCITY_ERR_066_Rx : 176|8@1+ (0.003,0) [0|0.765] "m/s"  RDR05
 SG_ DET_AZIMUTH_066_Rx : 200|13@1+ (0.0004,-1.5708) [-1.5708|1.5708] "rad"  RDR05
 SG_ DET_AZIMUTH_ERR_066_Rx : 217|7@1+ (0.00087267,0) [0|0.11082909] "rad"  RDR05
 SG_ DET_ELEVATION_066_Rx : 184|8@1+ (0.00275,-0.34925) [-0.34925|0.34925] "rad"  RDR05
 SG_ DET_ELEVATION_ERR_066_Rx : 192|6@1+ (0.00174533,0) [0|0.10995579] "rad"  RDR05
 SG_ DET_RCS_066_Rx : 240|8@1+ (0.5,-64) [-64|63.5] "dBsm"  RDR05
 SG_ DET_BI_STATIC_FLAG_066_Rx : 216|1@1+ (1,0) [0|1] ""  RDR05
 SG_ DET_SUPER_RES_TARGET_066_Rx : 199|1@1+ (1,0) [0|1] ""  RDR05
 SG_ DET_SNR_066_Rx : 232|8@1+ (0.35156,0) [0|89.6478] "dB"  RDR05
 SG_ DET_EXISTENCE_PROB_066_Rx : 224|6@1+ (1.588,0) [0|100] "%"  RDR05
 SG_ DET_HVC_FLAG_066_Rx : 198|1@1+ (1,0) [0|1] ""  RDR05
 SG_ DET_CONFD_AZIMUTH_066_Rx : 230|2@1+ (1,0) [0|3] ""  RDR05
 SG_ DET_CONFD_ELEVATION_066_Rx : 213|2@1+ (1,0) [0|3] ""  RDR05
 SG_ DET_PROB_1STAZHYPO_066_Rx : 215|1@1+ (1,0) [0|1] ""  RDR05
 SG_ DET_IDM_066_Rx : 175|1@1+ (1,0) [0|1] ""  RDR05
 SG_ DET_MTD_066_Rx : 159|1@1+ (1,0) [0|1] ""  RDR05
 SG_ DET_BELOW_RAIN_THOLD_066_Rx : 151|1@1+ (1,0) [0|1] ""  RDR05
 SG_ DET_RANGE_067_Rx : 248|15@1+ (0.015625,0) [0|500] "m"  RDR05
 SG_ DET_RANGE_ERR_067_Rx : 264|7@1+ (0.0075,0) [0|0.9525] "m"  RDR05
 SG_ DET_RANGE_VELOCITY_067_Rx : 272|15@1+ (0.0078125,-128) [-128|127.9921875] "m/s"  RDR05
 SG_ DET_RANGE_VELOCITY_ERR_067_Rx : 288|8@1+ (0.003,0) [0|0.765] "m/s"  RDR05
 SG_ DET_AZIMUTH_067_Rx : 312|13@1+ (0.0004,-1.5708) [-1.5708|1.5708] "rad"  RDR05
 SG_ DET_AZIMUTH_ERR_067_Rx : 329|7@1+ (0.00087267,0) [0|0.11082909] "rad"  RDR05
 SG_ DET_ELEVATION_067_Rx : 296|8@1+ (0.00275,-0.34925) [-0.34925|0.34925] "rad"  RDR05
 SG_ DET_ELEVATION_ERR_067_Rx : 304|6@1+ (0.00174533,0) [0|0.10995579] "rad"  RDR05
 SG_ DET_RCS_067_Rx : 352|8@1+ (0.5,-64) [-64|63.5] "dBsm"  RDR05
 SG_ DET_BI_STATIC_FLAG_067_Rx : 328|1@1+ (1,0) [0|1] ""  RDR05
 SG_ DET_SUPER_RES_TARGET_067_Rx : 311|1@1+ (1,0) [0|1] ""  RDR05
 SG_ DET_SNR_067_Rx : 344|8@1+ (0.35156,0) [0|89.6478] "dB"  RDR05
 SG_ DET_EXISTENCE_PROB_067_Rx : 336|6@1+ (1.588,0) [0|100] "%"  RDR05
 SG_ DET_HVC_FLAG_067_Rx : 310|1@1+ (1,0) [0|1] ""  RDR05
 SG_ DET_CONFD_AZIMUTH_067_Rx : 342|2@1+ (1,0) [0|3] ""  RDR05
 SG_ DET_CONFD_ELEVATION_067_Rx : 325|2@1+ (1,0) [0|3] ""  RDR05
 SG_ DET_PROB_1STAZHYPO_067_Rx : 327|1@1+ (1,0) [0|1] ""  RDR05
 SG_ DET_IDM_067_Rx : 287|1@1+ (1,0) [0|1] ""  RDR05
 SG_ DET_MTD_067_Rx : 271|1@1+ (1,0) [0|1] ""  RDR05
 SG_ DET_BELOW_RAIN_THOLD_067_Rx : 263|1@1+ (1,0) [0|1] ""  RDR05
 SG_ DET_RANGE_068_Rx : 360|15@1+ (0.015625,0) [0|500] "m"  RDR05
 SG_ DET_RANGE_ERR_068_Rx : 376|7@1+ (0.0075,0) [0|0.9525] "m"  RDR05
 SG_ DET_RANGE_VELOCITY_068_Rx : 384|15@1+ (0.0078125,-128) [-128|127.9921875] "m/s"  RDR05
 SG_ DET_RANGE_VELOCITY_ERR_068_Rx : 400|8@1+ (0.003,0) [0|0.765] "m/s"  RDR05
 SG_ DET_AZIMUTH_068_Rx : 424|13@1+ (0.0004,-1.5708) [-1.5708|1.5708] "rad"  RDR05
 SG_ DET_AZIMUTH_ERR_068_Rx : 441|7@1+ (0.00087267,0) [0|0.11082909] "rad"  RDR05
 SG_ DET_ELEVATION_068_Rx : 408|8@1+ (0.00275,-0.34925) [-0.34925|0.34925] "rad"  RDR05
 SG_ DET_ELEVATION_ERR_068_Rx : 416|6@1+ (0.00174533,0) [0|0.10995579] "rad"  RDR05
 SG_ DET_RCS_068_Rx : 464|8@1+ (0.5,-64) [-64|63.5] "dBsm"  RDR05
 SG_ DET_BI_STATIC_FLAG_068_Rx : 440|1@1+ (1,0) [0|1] ""  RDR05
 SG_ DET_SUPER_RES_TARGET_068_Rx : 423|1@1+ (1,0) [0|1] ""  RDR05
 SG_ DET_SNR_068_Rx : 456|8@1+ (0.35156,0) [0|89.6478] "dB"  RDR05
 SG_ DET_EXISTENCE_PROB_068_Rx : 448|6@1+ (1.588,0) [0|100] "%"  RDR05
 SG_ DET_HVC_FLAG_068_Rx : 422|1@1+ (1,0) [0|1] ""  RDR05
 SG_ DET_CONFD_AZIMUTH_068_Rx : 454|2@1+ (1,0) [0|3] ""  RDR05
 SG_ DET_CONFD_ELEVATION_068_Rx : 437|2@1+ (1,0) [0|3] ""  RDR05
 SG_ DET_MH_SCAN_INDEX_4LSB_065_068_R : 476|4@1+ (1,0) [0|15] ""  RDR05
 SG_ DET_MH_CYCLE_COUNTER_065_068_Rx : 16|8@1+ (1,0) [0|255] ""  RDR05
 SG_ DET_MH_CRC16_065_068_Rx : 0|16@1+ (1,0) [0|65535] ""  RDR05
 SG_ DET_PROB_1STAZHYPO_068_Rx : 439|1@1+ (1,0) [0|1] ""  RDR05
 SG_ DET_IDM_068_Rx : 399|1@1+ (1,0) [0|1] ""  RDR05
 SG_ DET_MTD_068_Rx : 383|1@1+ (1,0) [0|1] ""  RDR05
 SG_ DET_BELOW_RAIN_THOLD_068_Rx : 375|1@1+ (1,0) [0|1] ""  RDR05

BO_ 273 RDR_FUSION_DET_069_072: 64 RDR_Fusion_Partner
 SG_ DET_RANGE_069_Rx : 24|15@1+ (0.015625,0) [0|500] "m"  RDR05
 SG_ DET_RANGE_ERR_069_Rx : 40|7@1+ (0.0075,0) [0|0.9525] "m"  RDR05
 SG_ DET_RANGE_VELOCITY_069_Rx : 48|15@1+ (0.0078125,-128) [-128|127.9921875] "m/s"  RDR05
 SG_ DET_RANGE_VELOCITY_ERR_069_Rx : 64|8@1+ (0.003,0) [0|0.765] "m/s"  RDR05
 SG_ DET_AZIMUTH_069_Rx : 88|13@1+ (0.0004,-1.5708) [-1.5708|1.5708] "rad"  RDR05
 SG_ DET_AZIMUTH_ERR_069_Rx : 105|7@1+ (0.00087267,0) [0|0.11082909] "rad"  RDR05
 SG_ DET_ELEVATION_069_Rx : 72|8@1+ (0.00275,-0.34925) [-0.34925|0.34925] "rad"  RDR05
 SG_ DET_ELEVATION_ERR_069_Rx : 80|6@1+ (0.00174533,0) [0|0.10995579] "rad"  RDR05
 SG_ DET_RCS_069_Rx : 128|8@1+ (0.5,-64) [-64|63.5] "dBsm"  RDR05
 SG_ DET_BI_STATIC_FLAG_069_Rx : 104|1@1+ (1,0) [0|1] ""  RDR05
 SG_ DET_SUPER_RES_TARGET_069_Rx : 87|1@1+ (1,0) [0|1] ""  RDR05
 SG_ DET_SNR_069_Rx : 120|8@1+ (0.35156,0) [0|89.6478] "dB"  RDR05
 SG_ DET_EXISTENCE_PROB_069_Rx : 112|6@1+ (1.588,0) [0|100] "%"  RDR05
 SG_ DET_HVC_FLAG_069_Rx : 86|1@1+ (1,0) [0|1] ""  RDR05
 SG_ DET_CONFD_AZIMUTH_069_Rx : 118|2@1+ (1,0) [0|3] ""  RDR05
 SG_ DET_CONFD_ELEVATION_069_Rx : 101|2@1+ (1,0) [0|3] ""  RDR05
 SG_ DET_PROB_1STAZHYPO_069_Rx : 103|1@1+ (1,0) [0|1] ""  RDR05
 SG_ DET_IDM_069_Rx : 63|1@1+ (1,0) [0|1] ""  RDR05
 SG_ DET_MTD_069_Rx : 47|1@1+ (1,0) [0|1] ""  RDR05
 SG_ DET_BELOW_RAIN_THOLD_069_Rx : 39|1@1+ (1,0) [0|1] ""  RDR05
 SG_ DET_RANGE_070_Rx : 136|15@1+ (0.015625,0) [0|500] "m"  RDR05
 SG_ DET_RANGE_ERR_070_Rx : 152|7@1+ (0.0075,0) [0|0.9525] "m"  RDR05
 SG_ DET_RANGE_VELOCITY_070_Rx : 160|15@1+ (0.0078125,-128) [-128|127.9921875] "m/s"  RDR05
 SG_ DET_RANGE_VELOCITY_ERR_070_Rx : 176|8@1+ (0.003,0) [0|0.765] "m/s"  RDR05
 SG_ DET_AZIMUTH_070_Rx : 200|13@1+ (0.0004,-1.5708) [-1.5708|1.5708] "rad"  RDR05
 SG_ DET_AZIMUTH_ERR_070_Rx : 217|7@1+ (0.00087267,0) [0|0.11082909] "rad"  RDR05
 SG_ DET_ELEVATION_070_Rx : 184|8@1+ (0.00275,-0.34925) [-0.34925|0.34925] "rad"  RDR05
 SG_ DET_ELEVATION_ERR_070_Rx : 192|6@1+ (0.00174533,0) [0|0.10995579] "rad"  RDR05
 SG_ DET_RCS_070_Rx : 240|8@1+ (0.5,-64) [-64|63.5] "dBsm"  RDR05
 SG_ DET_BI_STATIC_FLAG_070_Rx : 216|1@1+ (1,0) [0|1] ""  RDR05
 SG_ DET_SUPER_RES_TARGET_070_Rx : 199|1@1+ (1,0) [0|1] ""  RDR05
 SG_ DET_SNR_070_Rx : 232|8@1+ (0.35156,0) [0|89.6478] "dB"  RDR05
 SG_ DET_EXISTENCE_PROB_070_Rx : 224|6@1+ (1.588,0) [0|100] "%"  RDR05
 SG_ DET_HVC_FLAG_070_Rx : 198|1@1+ (1,0) [0|1] ""  RDR05
 SG_ DET_CONFD_AZIMUTH_070_Rx : 230|2@1+ (1,0) [0|3] ""  RDR05
 SG_ DET_CONFD_ELEVATION_070_Rx : 213|2@1+ (1,0) [0|3] ""  RDR05
 SG_ DET_PROB_1STAZHYPO_070_Rx : 215|1@1+ (1,0) [0|1] ""  RDR05
 SG_ DET_IDM_070_Rx : 175|1@1+ (1,0) [0|1] ""  RDR05
 SG_ DET_MTD_070_Rx : 159|1@1+ (1,0) [0|1] ""  RDR05
 SG_ DET_BELOW_RAIN_THOLD_070_Rx : 151|1@1+ (1,0) [0|1] ""  RDR05
 SG_ DET_RANGE_071_Rx : 248|15@1+ (0.015625,0) [0|500] "m"  RDR05
 SG_ DET_RANGE_ERR_071_Rx : 264|7@1+ (0.0075,0) [0|0.9525] "m"  RDR05
 SG_ DET_RANGE_VELOCITY_071_Rx : 272|15@1+ (0.0078125,-128) [-128|127.9921875] "m/s"  RDR05
 SG_ DET_RANGE_VELOCITY_ERR_071_Rx : 288|8@1+ (0.003,0) [0|0.765] "m/s"  RDR05
 SG_ DET_AZIMUTH_071_Rx : 312|13@1+ (0.0004,-1.5708) [-1.5708|1.5708] "rad"  RDR05
 SG_ DET_AZIMUTH_ERR_071_Rx : 329|7@1+ (0.00087267,0) [0|0.11082909] "rad"  RDR05
 SG_ DET_ELEVATION_071_Rx : 296|8@1+ (0.00275,-0.34925) [-0.34925|0.34925] "rad"  RDR05
 SG_ DET_ELEVATION_ERR_071_Rx : 304|6@1+ (0.00174533,0) [0|0.10995579] "rad"  RDR05
 SG_ DET_RCS_071_Rx : 352|8@1+ (0.5,-64) [-64|63.5] "dBsm"  RDR05
 SG_ DET_BI_STATIC_FLAG_071_Rx : 328|1@1+ (1,0) [0|1] ""  RDR05
 SG_ DET_SUPER_RES_TARGET_071_Rx : 311|1@1+ (1,0) [0|1] ""  RDR05
 SG_ DET_SNR_071_Rx : 344|8@1+ (0.35156,0) [0|89.6478] "dB"  RDR05
 SG_ DET_EXISTENCE_PROB_071_Rx : 336|6@1+ (1.588,0) [0|100] "%"  RDR05
 SG_ DET_HVC_FLAG_071_Rx : 310|1@1+ (1,0) [0|1] ""  RDR05
 SG_ DET_CONFD_AZIMUTH_071_Rx : 342|2@1+ (1,0) [0|3] ""  RDR05
 SG_ DET_CONFD_ELEVATION_071_Rx : 325|2@1+ (1,0) [0|3] ""  RDR05
 SG_ DET_PROB_1STAZHYPO_071_Rx : 327|1@1+ (1,0) [0|1] ""  RDR05
 SG_ DET_IDM_071_Rx : 287|1@1+ (1,0) [0|1] ""  RDR05
 SG_ DET_MTD_071_Rx : 271|1@1+ (1,0) [0|1] ""  RDR05
 SG_ DET_BELOW_RAIN_THOLD_071_Rx : 263|1@1+ (1,0) [0|1] ""  RDR05
 SG_ DET_RANGE_072_Rx : 360|15@1+ (0.015625,0) [0|500] "m"  RDR05
 SG_ DET_RANGE_ERR_072_Rx : 376|7@1+ (0.0075,0) [0|0.9525] "m"  RDR05
 SG_ DET_RANGE_VELOCITY_072_Rx : 384|15@1+ (0.0078125,-128) [-128|127.9921875] "m/s"  RDR05
 SG_ DET_RANGE_VELOCITY_ERR_072_Rx : 400|8@1+ (0.003,0) [0|0.765] "m/s"  RDR05
 SG_ DET_AZIMUTH_072_Rx : 424|13@1+ (0.0004,-1.5708) [-1.5708|1.5708] "rad"  RDR05
 SG_ DET_AZIMUTH_ERR_072_Rx : 441|7@1+ (0.00087267,0) [0|0.11082909] "rad"  RDR05
 SG_ DET_ELEVATION_072_Rx : 408|8@1+ (0.00275,-0.34925) [-0.34925|0.34925] "rad"  RDR05
 SG_ DET_ELEVATION_ERR_072_Rx : 416|6@1+ (0.00174533,0) [0|0.10995579] "rad"  RDR05
 SG_ DET_RCS_072_Rx : 464|8@1+ (0.5,-64) [-64|63.5] "dBsm"  RDR05
 SG_ DET_BI_STATIC_FLAG_072_Rx : 440|1@1+ (1,0) [0|1] ""  RDR05
 SG_ DET_SUPER_RES_TARGET_072_Rx : 423|1@1+ (1,0) [0|1] ""  RDR05
 SG_ DET_SNR_072_Rx : 456|8@1+ (0.35156,0) [0|89.6478] "dB"  RDR05
 SG_ DET_EXISTENCE_PROB_072_Rx : 448|6@1+ (1.588,0) [0|100] "%"  RDR05
 SG_ DET_HVC_FLAG_072_Rx : 422|1@1+ (1,0) [0|1] ""  RDR05
 SG_ DET_CONFD_AZIMUTH_072_Rx : 454|2@1+ (1,0) [0|3] ""  RDR05
 SG_ DET_CONFD_ELEVATION_072_Rx : 437|2@1+ (1,0) [0|3] ""  RDR05
 SG_ DET_MH_SCAN_INDEX_4LSB_069_072_R : 476|4@1+ (1,0) [0|15] ""  RDR05
 SG_ DET_MH_CYCLE_COUNTER_069_072_Rx : 16|8@1+ (1,0) [0|255] ""  RDR05
 SG_ DET_MH_CRC16_069_072_Rx : 0|16@1+ (1,0) [0|65535] ""  RDR05
 SG_ DET_PROB_1STAZHYPO_072_Rx : 439|1@1+ (1,0) [0|1] ""  RDR05
 SG_ DET_IDM_072_Rx : 399|1@1+ (1,0) [0|1] ""  RDR05
 SG_ DET_MTD_072_Rx : 383|1@1+ (1,0) [0|1] ""  RDR05
 SG_ DET_BELOW_RAIN_THOLD_072_Rx : 375|1@1+ (1,0) [0|1] ""  RDR05

BO_ 274 RDR_FUSION_DET_073_076: 64 RDR_Fusion_Partner
 SG_ DET_RANGE_073_Rx : 24|15@1+ (0.015625,0) [0|500] "m"  RDR05
 SG_ DET_RANGE_ERR_073_Rx : 40|7@1+ (0.0075,0) [0|0.9525] "m"  RDR05
 SG_ DET_RANGE_VELOCITY_073_Rx : 48|15@1+ (0.0078125,-128) [-128|127.9921875] "m/s"  RDR05
 SG_ DET_RANGE_VELOCITY_ERR_073_Rx : 64|8@1+ (0.003,0) [0|0.765] "m/s"  RDR05
 SG_ DET_AZIMUTH_073_Rx : 88|13@1+ (0.0004,-1.5708) [-1.5708|1.5708] "rad"  RDR05
 SG_ DET_AZIMUTH_ERR_073_Rx : 105|7@1+ (0.00087267,0) [0|0.11082909] "rad"  RDR05
 SG_ DET_ELEVATION_073_Rx : 72|8@1+ (0.00275,-0.34925) [-0.34925|0.34925] "rad"  RDR05
 SG_ DET_ELEVATION_ERR_073_Rx : 80|6@1+ (0.00174533,0) [0|0.10995579] "rad"  RDR05
 SG_ DET_RCS_073_Rx : 128|8@1+ (0.5,-64) [-64|63.5] "dBsm"  RDR05
 SG_ DET_BI_STATIC_FLAG_073_Rx : 104|1@1+ (1,0) [0|1] ""  RDR05
 SG_ DET_SUPER_RES_TARGET_073_Rx : 87|1@1+ (1,0) [0|1] ""  RDR05
 SG_ DET_SNR_073_Rx : 120|8@1+ (0.35156,0) [0|89.6478] "dB"  RDR05
 SG_ DET_EXISTENCE_PROB_073_Rx : 112|6@1+ (1.588,0) [0|100] "%"  RDR05
 SG_ DET_HVC_FLAG_073_Rx : 86|1@1+ (1,0) [0|1] ""  RDR05
 SG_ DET_CONFD_AZIMUTH_073_Rx : 118|2@1+ (1,0) [0|3] ""  RDR05
 SG_ DET_CONFD_ELEVATION_073_Rx : 101|2@1+ (1,0) [0|3] ""  RDR05
 SG_ DET_PROB_1STAZHYPO_073_Rx : 103|1@1+ (1,0) [0|1] ""  RDR05
 SG_ DET_IDM_073_Rx : 63|1@1+ (1,0) [0|1] ""  RDR05
 SG_ DET_MTD_073_Rx : 47|1@1+ (1,0) [0|1] ""  RDR05
 SG_ DET_BELOW_RAIN_THOLD_073_Rx : 39|1@1+ (1,0) [0|1] ""  RDR05
 SG_ DET_RANGE_074_Rx : 136|15@1+ (0.015625,0) [0|500] "m"  RDR05
 SG_ DET_RANGE_ERR_074_Rx : 152|7@1+ (0.0075,0) [0|0.9525] "m"  RDR05
 SG_ DET_RANGE_VELOCITY_074_Rx : 160|15@1+ (0.0078125,-128) [-128|127.9921875] "m/s"  RDR05
 SG_ DET_RANGE_VELOCITY_ERR_074_Rx : 176|8@1+ (0.003,0) [0|0.765] "m/s"  RDR05
 SG_ DET_AZIMUTH_074_Rx : 200|13@1+ (0.0004,-1.5708) [-1.5708|1.5708] "rad"  RDR05
 SG_ DET_AZIMUTH_ERR_074_Rx : 217|7@1+ (0.00087267,0) [0|0.11082909] "rad"  RDR05
 SG_ DET_ELEVATION_074_Rx : 184|8@1+ (0.00275,-0.34925) [-0.34925|0.34925] "rad"  RDR05
 SG_ DET_ELEVATION_ERR_074_Rx : 192|6@1+ (0.00174533,0) [0|0.10995579] "rad"  RDR05
 SG_ DET_RCS_074_Rx : 240|8@1+ (0.5,-64) [-64|63.5] "dBsm"  RDR05
 SG_ DET_BI_STATIC_FLAG_074_Rx : 216|1@1+ (1,0) [0|1] ""  RDR05
 SG_ DET_SUPER_RES_TARGET_074_Rx : 199|1@1+ (1,0) [0|1] ""  RDR05
 SG_ DET_SNR_074_Rx : 232|8@1+ (0.35156,0) [0|89.6478] "dB"  RDR05
 SG_ DET_EXISTENCE_PROB_074_Rx : 224|6@1+ (1.588,0) [0|100] "%"  RDR05
 SG_ DET_HVC_FLAG_074_Rx : 198|1@1+ (1,0) [0|1] ""  RDR05
 SG_ DET_CONFD_AZIMUTH_074_Rx : 230|2@1+ (1,0) [0|3] ""  RDR05
 SG_ DET_CONFD_ELEVATION_074_Rx : 213|2@1+ (1,0) [0|3] ""  RDR05
 SG_ DET_PROB_1STAZHYPO_074_Rx : 215|1@1+ (1,0) [0|1] ""  RDR05
 SG_ DET_IDM_074_Rx : 175|1@1+ (1,0) [0|1] ""  RDR05
 SG_ DET_MTD_074_Rx : 159|1@1+ (1,0) [0|1] ""  RDR05
 SG_ DET_BELOW_RAIN_THOLD_074_Rx : 151|1@1+ (1,0) [0|1] ""  RDR05
 SG_ DET_RANGE_075_Rx : 248|15@1+ (0.015625,0) [0|500] "m"  RDR05
 SG_ DET_RANGE_ERR_075_Rx : 264|7@1+ (0.0075,0) [0|0.9525] "m"  RDR05
 SG_ DET_RANGE_VELOCITY_075_Rx : 272|15@1+ (0.0078125,-128) [-128|127.9921875] "m/s"  RDR05
 SG_ DET_RANGE_VELOCITY_ERR_075_Rx : 288|8@1+ (0.003,0) [0|0.765] "m/s"  RDR05
 SG_ DET_AZIMUTH_075_Rx : 312|13@1+ (0.0004,-1.5708) [-1.5708|1.5708] "rad"  RDR05
 SG_ DET_AZIMUTH_ERR_075_Rx : 329|7@1+ (0.00087267,0) [0|0.11082909] "rad"  RDR05
 SG_ DET_ELEVATION_075_Rx : 296|8@1+ (0.00275,-0.34925) [-0.34925|0.34925] "rad"  RDR05
 SG_ DET_ELEVATION_ERR_075_Rx : 304|6@1+ (0.00174533,0) [0|0.10995579] "rad"  RDR05
 SG_ DET_RCS_075_Rx : 352|8@1+ (0.5,-64) [-64|63.5] "dBsm"  RDR05
 SG_ DET_BI_STATIC_FLAG_075_Rx : 328|1@1+ (1,0) [0|1] ""  RDR05
 SG_ DET_SUPER_RES_TARGET_075_Rx : 311|1@1+ (1,0) [0|1] ""  RDR05
 SG_ DET_SNR_075_Rx : 344|8@1+ (0.35156,0) [0|89.6478] "dB"  RDR05
 SG_ DET_EXISTENCE_PROB_075_Rx : 336|6@1+ (1.588,0) [0|100] "%"  RDR05
 SG_ DET_HVC_FLAG_075_Rx : 310|1@1+ (1,0) [0|1] ""  RDR05
 SG_ DET_CONFD_AZIMUTH_075_Rx : 342|2@1+ (1,0) [0|3] ""  RDR05
 SG_ DET_CONFD_ELEVATION_075_Rx : 325|2@1+ (1,0) [0|3] ""  RDR05
 SG_ DET_PROB_1STAZHYPO_075_Rx : 327|1@1+ (1,0) [0|1] ""  RDR05
 SG_ DET_IDM_075_Rx : 287|1@1+ (1,0) [0|1] ""  RDR05
 SG_ DET_MTD_075_Rx : 271|1@1+ (1,0) [0|1] ""  RDR05
 SG_ DET_BELOW_RAIN_THOLD_075_Rx : 263|1@1+ (1,0) [0|1] ""  RDR05
 SG_ DET_RANGE_076_Rx : 360|15@1+ (0.015625,0) [0|500] "m"  RDR05
 SG_ DET_RANGE_ERR_076_Rx : 376|7@1+ (0.0075,0) [0|0.9525] "m"  RDR05
 SG_ DET_RANGE_VELOCITY_076_Rx : 384|15@1+ (0.0078125,-128) [-128|127.9921875] "m/s"  RDR05
 SG_ DET_RANGE_VELOCITY_ERR_076_Rx : 400|8@1+ (0.003,0) [0|0.765] "m/s"  RDR05
 SG_ DET_AZIMUTH_076_Rx : 424|13@1+ (0.0004,-1.5708) [-1.5708|1.5708] "rad"  RDR05
 SG_ DET_AZIMUTH_ERR_076_Rx : 441|7@1+ (0.00087267,0) [0|0.11082909] "rad"  RDR05
 SG_ DET_ELEVATION_076_Rx : 408|8@1+ (0.00275,-0.34925) [-0.34925|0.34925] "rad"  RDR05
 SG_ DET_ELEVATION_ERR_076_Rx : 416|6@1+ (0.00174533,0) [0|0.10995579] "rad"  RDR05
 SG_ DET_RCS_076_Rx : 464|8@1+ (0.5,-64) [-64|63.5] "dBsm"  RDR05
 SG_ DET_BI_STATIC_FLAG_076_Rx : 440|1@1+ (1,0) [0|1] ""  RDR05
 SG_ DET_SUPER_RES_TARGET_076_Rx : 423|1@1+ (1,0) [0|1] ""  RDR05
 SG_ DET_SNR_076_Rx : 456|8@1+ (0.35156,0) [0|89.6478] "dB"  RDR05
 SG_ DET_EXISTENCE_PROB_076_Rx : 448|6@1+ (1.588,0) [0|100] "%"  RDR05
 SG_ DET_HVC_FLAG_076_Rx : 422|1@1+ (1,0) [0|1] ""  RDR05
 SG_ DET_CONFD_AZIMUTH_076_Rx : 454|2@1+ (1,0) [0|3] ""  RDR05
 SG_ DET_CONFD_ELEVATION_076_Rx : 437|2@1+ (1,0) [0|3] ""  RDR05
 SG_ DET_MH_SCAN_INDEX_4LSB_073_076_R : 476|4@1+ (1,0) [0|15] ""  RDR05
 SG_ DET_MH_CYCLE_COUNTER_073_076_Rx : 16|8@1+ (1,0) [0|255] ""  RDR05
 SG_ DET_MH_CRC16_073_076_Rx : 0|16@1+ (1,0) [0|65535] ""  RDR05
 SG_ DET_PROB_1STAZHYPO_076_Rx : 439|1@1+ (1,0) [0|1] ""  RDR05
 SG_ DET_IDM_076_Rx : 399|1@1+ (1,0) [0|1] ""  RDR05
 SG_ DET_MTD_076_Rx : 383|1@1+ (1,0) [0|1] ""  RDR05
 SG_ DET_BELOW_RAIN_THOLD_076_Rx : 375|1@1+ (1,0) [0|1] ""  RDR05

BO_ 275 RDR_FUSION_DET_077_080: 64 RDR_Fusion_Partner
 SG_ DET_RANGE_077_Rx : 24|15@1+ (0.015625,0) [0|500] "m"  RDR05
 SG_ DET_RANGE_ERR_077_Rx : 40|7@1+ (0.0075,0) [0|0.9525] "m"  RDR05
 SG_ DET_RANGE_VELOCITY_077_Rx : 48|15@1+ (0.0078125,-128) [-128|127.9921875] "m/s"  RDR05
 SG_ DET_RANGE_VELOCITY_ERR_077_Rx : 64|8@1+ (0.003,0) [0|0.765] "m/s"  RDR05
 SG_ DET_AZIMUTH_077_Rx : 88|13@1+ (0.0004,-1.5708) [-1.5708|1.5708] "rad"  RDR05
 SG_ DET_AZIMUTH_ERR_077_Rx : 105|7@1+ (0.00087267,0) [0|0.11082909] "rad"  RDR05
 SG_ DET_ELEVATION_077_Rx : 72|8@1+ (0.00275,-0.34925) [-0.34925|0.34925] "rad"  RDR05
 SG_ DET_ELEVATION_ERR_077_Rx : 80|6@1+ (0.00174533,0) [0|0.10995579] "rad"  RDR05
 SG_ DET_RCS_077_Rx : 128|8@1+ (0.5,-64) [-64|63.5] "dBsm"  RDR05
 SG_ DET_BI_STATIC_FLAG_077_Rx : 104|1@1+ (1,0) [0|1] ""  RDR05
 SG_ DET_SUPER_RES_TARGET_077_Rx : 87|1@1+ (1,0) [0|1] ""  RDR05
 SG_ DET_SNR_077_Rx : 120|8@1+ (0.35156,0) [0|89.6478] "dB"  RDR05
 SG_ DET_EXISTENCE_PROB_077_Rx : 112|6@1+ (1.588,0) [0|100] "%"  RDR05
 SG_ DET_HVC_FLAG_077_Rx : 86|1@1+ (1,0) [0|1] ""  RDR05
 SG_ DET_CONFD_AZIMUTH_077_Rx : 118|2@1+ (1,0) [0|3] ""  RDR05
 SG_ DET_CONFD_ELEVATION_077_Rx : 101|2@1+ (1,0) [0|3] ""  RDR05
 SG_ DET_PROB_1STAZHYPO_077_Rx : 103|1@1+ (1,0) [0|1] ""  RDR05
 SG_ DET_IDM_077_Rx : 63|1@1+ (1,0) [0|1] ""  RDR05
 SG_ DET_MTD_077_Rx : 47|1@1+ (1,0) [0|1] ""  RDR05
 SG_ DET_BELOW_RAIN_THOLD_077_Rx : 39|1@1+ (1,0) [0|1] ""  RDR05
 SG_ DET_RANGE_078_Rx : 136|15@1+ (0.015625,0) [0|500] "m"  RDR05
 SG_ DET_RANGE_ERR_078_Rx : 152|7@1+ (0.0075,0) [0|0.9525] "m"  RDR05
 SG_ DET_RANGE_VELOCITY_078_Rx : 160|15@1+ (0.0078125,-128) [-128|127.9921875] "m/s"  RDR05
 SG_ DET_RANGE_VELOCITY_ERR_078_Rx : 176|8@1+ (0.003,0) [0|0.765] "m/s"  RDR05
 SG_ DET_AZIMUTH_078_Rx : 200|13@1+ (0.0004,-1.5708) [-1.5708|1.5708] "rad"  RDR05
 SG_ DET_AZIMUTH_ERR_078_Rx : 217|7@1+ (0.00087267,0) [0|0.11082909] "rad"  RDR05
 SG_ DET_ELEVATION_078_Rx : 184|8@1+ (0.00275,-0.34925) [-0.34925|0.34925] "rad"  RDR05
 SG_ DET_ELEVATION_ERR_078_Rx : 192|6@1+ (0.00174533,0) [0|0.10995579] "rad"  RDR05
 SG_ DET_RCS_078_Rx : 240|8@1+ (0.5,-64) [-64|63.5] "dBsm"  RDR05
 SG_ DET_BI_STATIC_FLAG_078_Rx : 216|1@1+ (1,0) [0|1] ""  RDR05
 SG_ DET_SUPER_RES_TARGET_078_Rx : 199|1@1+ (1,0) [0|1] ""  RDR05
 SG_ DET_SNR_078_Rx : 232|8@1+ (0.35156,0) [0|89.6478] "dB"  RDR05
 SG_ DET_EXISTENCE_PROB_078_Rx : 224|6@1+ (1.588,0) [0|100] "%"  RDR05
 SG_ DET_HVC_FLAG_078_Rx : 198|1@1+ (1,0) [0|1] ""  RDR05
 SG_ DET_CONFD_AZIMUTH_078_Rx : 230|2@1+ (1,0) [0|3] ""  RDR05
 SG_ DET_CONFD_ELEVATION_078_Rx : 213|2@1+ (1,0) [0|3] ""  RDR05
 SG_ DET_PROB_1STAZHYPO_078_Rx : 215|1@1+ (1,0) [0|1] ""  RDR05
 SG_ DET_IDM_078_Rx : 175|1@1+ (1,0) [0|1] ""  RDR05
 SG_ DET_MTD_078_Rx : 159|1@1+ (1,0) [0|1] ""  RDR05
 SG_ DET_BELOW_RAIN_THOLD_078_Rx : 151|1@1+ (1,0) [0|1] ""  RDR05
 SG_ DET_RANGE_079_Rx : 248|15@1+ (0.015625,0) [0|500] "m"  RDR05
 SG_ DET_RANGE_ERR_079_Rx : 264|7@1+ (0.0075,0) [0|0.9525] "m"  RDR05
 SG_ DET_RANGE_VELOCITY_079_Rx : 272|15@1+ (0.0078125,-128) [-128|127.9921875] "m/s"  RDR05
 SG_ DET_RANGE_VELOCITY_ERR_079_Rx : 288|8@1+ (0.003,0) [0|0.765] "m/s"  RDR05
 SG_ DET_AZIMUTH_079_Rx : 312|13@1+ (0.0004,-1.5708) [-1.5708|1.5708] "rad"  RDR05
 SG_ DET_AZIMUTH_ERR_079_Rx : 329|7@1+ (0.00087267,0) [0|0.11082909] "rad"  RDR05
 SG_ DET_ELEVATION_079_Rx : 296|8@1+ (0.00275,-0.34925) [-0.34925|0.34925] "rad"  RDR05
 SG_ DET_ELEVATION_ERR_079_Rx : 304|6@1+ (0.00174533,0) [0|0.10995579] "rad"  RDR05
 SG_ DET_RCS_079_Rx : 352|8@1+ (0.5,-64) [-64|63.5] "dBsm"  RDR05
 SG_ DET_BI_STATIC_FLAG_079_Rx : 328|1@1+ (1,0) [0|1] ""  RDR05
 SG_ DET_SUPER_RES_TARGET_079_Rx : 311|1@1+ (1,0) [0|1] ""  RDR05
 SG_ DET_SNR_079_Rx : 344|8@1+ (0.35156,0) [0|89.6478] "dB"  RDR05
 SG_ DET_EXISTENCE_PROB_079_Rx : 336|6@1+ (1.588,0) [0|100] "%"  RDR05
 SG_ DET_HVC_FLAG_079_Rx : 310|1@1+ (1,0) [0|1] ""  RDR05
 SG_ DET_CONFD_AZIMUTH_079_Rx : 342|2@1+ (1,0) [0|3] ""  RDR05
 SG_ DET_CONFD_ELEVATION_079_Rx : 325|2@1+ (1,0) [0|3] ""  RDR05
 SG_ DET_PROB_1STAZHYPO_079_Rx : 327|1@1+ (1,0) [0|1] ""  RDR05
 SG_ DET_IDM_079_Rx : 287|1@1+ (1,0) [0|1] ""  RDR05
 SG_ DET_MTD_079_Rx : 271|1@1+ (1,0) [0|1] ""  RDR05
 SG_ DET_BELOW_RAIN_THOLD_079_Rx : 263|1@1+ (1,0) [0|1] ""  RDR05
 SG_ DET_RANGE_080_Rx : 360|15@1+ (0.015625,0) [0|500] "m"  RDR05
 SG_ DET_RANGE_ERR_080_Rx : 376|7@1+ (0.0075,0) [0|0.9525] "m"  RDR05
 SG_ DET_RANGE_VELOCITY_080_Rx : 384|15@1+ (0.0078125,-128) [-128|127.9921875] "m/s"  RDR05
 SG_ DET_RANGE_VELOCITY_ERR_080_Rx : 400|8@1+ (0.003,0) [0|0.765] "m/s"  RDR05
 SG_ DET_AZIMUTH_080_Rx : 424|13@1+ (0.0004,-1.5708) [-1.5708|1.5708] "rad"  RDR05
 SG_ DET_AZIMUTH_ERR_080_Rx : 441|7@1+ (0.00087267,0) [0|0.11082909] "rad"  RDR05
 SG_ DET_ELEVATION_080_Rx : 408|8@1+ (0.00275,-0.34925) [-0.34925|0.34925] "rad"  RDR05
 SG_ DET_ELEVATION_ERR_080_Rx : 416|6@1+ (0.00174533,0) [0|0.10995579] "rad"  RDR05
 SG_ DET_RCS_080_Rx : 464|8@1+ (0.5,-64) [-64|63.5] "dBsm"  RDR05
 SG_ DET_BI_STATIC_FLAG_080_Rx : 440|1@1+ (1,0) [0|1] ""  RDR05
 SG_ DET_SUPER_RES_TARGET_080_Rx : 423|1@1+ (1,0) [0|1] ""  RDR05
 SG_ DET_SNR_080_Rx : 456|8@1+ (0.35156,0) [0|89.6478] "dB"  RDR05
 SG_ DET_EXISTENCE_PROB_080_Rx : 448|6@1+ (1.588,0) [0|100] "%"  RDR05
 SG_ DET_HVC_FLAG_080_Rx : 422|1@1+ (1,0) [0|1] ""  RDR05
 SG_ DET_CONFD_AZIMUTH_080_Rx : 454|2@1+ (1,0) [0|3] ""  RDR05
 SG_ DET_CONFD_ELEVATION_080_Rx : 437|2@1+ (1,0) [0|3] ""  RDR05
 SG_ DET_MH_SCAN_INDEX_4LSB_077_080_R : 476|4@1+ (1,0) [0|15] ""  RDR05
 SG_ DET_MH_CYCLE_COUNTER_077_080_Rx : 16|8@1+ (1,0) [0|255] ""  RDR05
 SG_ DET_MH_CRC16_077_080_Rx : 0|16@1+ (1,0) [0|65535] ""  RDR05
 SG_ DET_PROB_1STAZHYPO_080_Rx : 439|1@1+ (1,0) [0|1] ""  RDR05
 SG_ DET_IDM_080_Rx : 399|1@1+ (1,0) [0|1] ""  RDR05
 SG_ DET_MTD_080_Rx : 383|1@1+ (1,0) [0|1] ""  RDR05
 SG_ DET_BELOW_RAIN_THOLD_080_Rx : 375|1@1+ (1,0) [0|1] ""  RDR05

BO_ 276 RDR_FUSION_DET_081_084: 64 RDR_Fusion_Partner
 SG_ DET_RANGE_081_Rx : 24|15@1+ (0.015625,0) [0|500] "m"  RDR05
 SG_ DET_RANGE_ERR_081_Rx : 40|7@1+ (0.0075,0) [0|0.9525] "m"  RDR05
 SG_ DET_RANGE_VELOCITY_081_Rx : 48|15@1+ (0.0078125,-128) [-128|127.9921875] "m/s"  RDR05
 SG_ DET_RANGE_VELOCITY_ERR_081_Rx : 64|8@1+ (0.003,0) [0|0.765] "m/s"  RDR05
 SG_ DET_AZIMUTH_081_Rx : 88|13@1+ (0.0004,-1.5708) [-1.5708|1.5708] "rad"  RDR05
 SG_ DET_AZIMUTH_ERR_081_Rx : 105|7@1+ (0.00087267,0) [0|0.11082909] "rad"  RDR05
 SG_ DET_ELEVATION_081_Rx : 72|8@1+ (0.00275,-0.34925) [-0.34925|0.34925] "rad"  RDR05
 SG_ DET_ELEVATION_ERR_081_Rx : 80|6@1+ (0.00174533,0) [0|0.10995579] "rad"  RDR05
 SG_ DET_RCS_081_Rx : 128|8@1+ (0.5,-64) [-64|63.5] "dBsm"  RDR05
 SG_ DET_BI_STATIC_FLAG_081_Rx : 104|1@1+ (1,0) [0|1] ""  RDR05
 SG_ DET_SUPER_RES_TARGET_081_Rx : 87|1@1+ (1,0) [0|1] ""  RDR05
 SG_ DET_SNR_081_Rx : 120|8@1+ (0.35156,0) [0|89.6478] "dB"  RDR05
 SG_ DET_EXISTENCE_PROB_081_Rx : 112|6@1+ (1.588,0) [0|100] "%"  RDR05
 SG_ DET_HVC_FLAG_081_Rx : 86|1@1+ (1,0) [0|1] ""  RDR05
 SG_ DET_CONFD_AZIMUTH_081_Rx : 118|2@1+ (1,0) [0|3] ""  RDR05
 SG_ DET_CONFD_ELEVATION_081_Rx : 101|2@1+ (1,0) [0|3] ""  RDR05
 SG_ DET_PROB_1STAZHYPO_081_Rx : 103|1@1+ (1,0) [0|1] ""  RDR05
 SG_ DET_IDM_081_Rx : 63|1@1+ (1,0) [0|1] ""  RDR05
 SG_ DET_MTD_081_Rx : 47|1@1+ (1,0) [0|1] ""  RDR05
 SG_ DET_BELOW_RAIN_THOLD_081_Rx : 39|1@1+ (1,0) [0|1] ""  RDR05
 SG_ DET_RANGE_082_Rx : 136|15@1+ (0.015625,0) [0|500] "m"  RDR05
 SG_ DET_RANGE_ERR_082_Rx : 152|7@1+ (0.0075,0) [0|0.9525] "m"  RDR05
 SG_ DET_RANGE_VELOCITY_082_Rx : 160|15@1+ (0.0078125,-128) [-128|127.9921875] "m/s"  RDR05
 SG_ DET_RANGE_VELOCITY_ERR_082_Rx : 176|8@1+ (0.003,0) [0|0.765] "m/s"  RDR05
 SG_ DET_AZIMUTH_082_Rx : 200|13@1+ (0.0004,-1.5708) [-1.5708|1.5708] "rad"  RDR05
 SG_ DET_AZIMUTH_ERR_082_Rx : 217|7@1+ (0.00087267,0) [0|0.11082909] "rad"  RDR05
 SG_ DET_ELEVATION_082_Rx : 184|8@1+ (0.00275,-0.34925) [-0.34925|0.34925] "rad"  RDR05
 SG_ DET_ELEVATION_ERR_082_Rx : 192|6@1+ (0.00174533,0) [0|0.10995579] "rad"  RDR05
 SG_ DET_RCS_082_Rx : 240|8@1+ (0.5,-64) [-64|63.5] "dBsm"  RDR05
 SG_ DET_BI_STATIC_FLAG_082_Rx : 216|1@1+ (1,0) [0|1] ""  RDR05
 SG_ DET_SUPER_RES_TARGET_082_Rx : 199|1@1+ (1,0) [0|1] ""  RDR05
 SG_ DET_SNR_082_Rx : 232|8@1+ (0.35156,0) [0|89.6478] "dB"  RDR05
 SG_ DET_EXISTENCE_PROB_082_Rx : 224|6@1+ (1.588,0) [0|100] "%"  RDR05
 SG_ DET_HVC_FLAG_082_Rx : 198|1@1+ (1,0) [0|1] ""  RDR05
 SG_ DET_CONFD_AZIMUTH_082_Rx : 230|2@1+ (1,0) [0|3] ""  RDR05
 SG_ DET_CONFD_ELEVATION_082_Rx : 213|2@1+ (1,0) [0|3] ""  RDR05
 SG_ DET_PROB_1STAZHYPO_082_Rx : 215|1@1+ (1,0) [0|1] ""  RDR05
 SG_ DET_IDM_082_Rx : 175|1@1+ (1,0) [0|1] ""  RDR05
 SG_ DET_MTD_082_Rx : 159|1@1+ (1,0) [0|1] ""  RDR05
 SG_ DET_BELOW_RAIN_THOLD_082_Rx : 151|1@1+ (1,0) [0|1] ""  RDR05
 SG_ DET_RANGE_083_Rx : 248|15@1+ (0.015625,0) [0|500] "m"  RDR05
 SG_ DET_RANGE_ERR_083_Rx : 264|7@1+ (0.0075,0) [0|0.9525] "m"  RDR05
 SG_ DET_RANGE_VELOCITY_083_Rx : 272|15@1+ (0.0078125,-128) [-128|127.9921875] "m/s"  RDR05
 SG_ DET_RANGE_VELOCITY_ERR_083_Rx : 288|8@1+ (0.003,0) [0|0.765] "m/s"  RDR05
 SG_ DET_AZIMUTH_083_Rx : 312|13@1+ (0.0004,-1.5708) [-1.5708|1.5708] "rad"  RDR05
 SG_ DET_AZIMUTH_ERR_083_Rx : 329|7@1+ (0.00087267,0) [0|0.11082909] "rad"  RDR05
 SG_ DET_ELEVATION_083_Rx : 296|8@1+ (0.00275,-0.34925) [-0.34925|0.34925] "rad"  RDR05
 SG_ DET_ELEVATION_ERR_083_Rx : 304|6@1+ (0.00174533,0) [0|0.10995579] "rad"  RDR05
 SG_ DET_RCS_083_Rx : 352|8@1+ (0.5,-64) [-64|63.5] "dBsm"  RDR05
 SG_ DET_BI_STATIC_FLAG_083_Rx : 328|1@1+ (1,0) [0|1] ""  RDR05
 SG_ DET_SUPER_RES_TARGET_083_Rx : 311|1@1+ (1,0) [0|1] ""  RDR05
 SG_ DET_SNR_083_Rx : 344|8@1+ (0.35156,0) [0|89.6478] "dB"  RDR05
 SG_ DET_EXISTENCE_PROB_083_Rx : 336|6@1+ (1.588,0) [0|100] "%"  RDR05
 SG_ DET_HVC_FLAG_083_Rx : 310|1@1+ (1,0) [0|1] ""  RDR05
 SG_ DET_CONFD_AZIMUTH_083_Rx : 342|2@1+ (1,0) [0|3] ""  RDR05
 SG_ DET_CONFD_ELEVATION_083_Rx : 325|2@1+ (1,0) [0|3] ""  RDR05
 SG_ DET_PROB_1STAZHYPO_083_Rx : 327|1@1+ (1,0) [0|1] ""  RDR05
 SG_ DET_IDM_083_Rx : 287|1@1+ (1,0) [0|1] ""  RDR05
 SG_ DET_MTD_083_Rx : 271|1@1+ (1,0) [0|1] ""  RDR05
 SG_ DET_BELOW_RAIN_THOLD_083_Rx : 263|1@1+ (1,0) [0|1] ""  RDR05
 SG_ DET_RANGE_084_Rx : 360|15@1+ (0.015625,0) [0|500] "m"  RDR05
 SG_ DET_RANGE_ERR_084_Rx : 376|7@1+ (0.0075,0) [0|0.9525] "m"  RDR05
 SG_ DET_RANGE_VELOCITY_084_Rx : 384|15@1+ (0.0078125,-128) [-128|127.9921875] "m/s"  RDR05
 SG_ DET_RANGE_VELOCITY_ERR_084_Rx : 400|8@1+ (0.003,0) [0|0.765] "m/s"  RDR05
 SG_ DET_AZIMUTH_084_Rx : 424|13@1+ (0.0004,-1.5708) [-1.5708|1.5708] "rad"  RDR05
 SG_ DET_AZIMUTH_ERR_084_Rx : 441|7@1+ (0.00087267,0) [0|0.11082909] "rad"  RDR05
 SG_ DET_ELEVATION_084_Rx : 408|8@1+ (0.00275,-0.34925) [-0.34925|0.34925] "rad"  RDR05
 SG_ DET_ELEVATION_ERR_084_Rx : 416|6@1+ (0.00174533,0) [0|0.10995579] "rad"  RDR05
 SG_ DET_RCS_084_Rx : 464|8@1+ (0.5,-64) [-64|63.5] "dBsm"  RDR05
 SG_ DET_BI_STATIC_FLAG_084_Rx : 440|1@1+ (1,0) [0|1] ""  RDR05
 SG_ DET_SUPER_RES_TARGET_084_Rx : 423|1@1+ (1,0) [0|1] ""  RDR05
 SG_ DET_SNR_084_Rx : 456|8@1+ (0.35156,0) [0|89.6478] "dB"  RDR05
 SG_ DET_EXISTENCE_PROB_084_Rx : 448|6@1+ (1.588,0) [0|100] "%"  RDR05
 SG_ DET_HVC_FLAG_084_Rx : 422|1@1+ (1,0) [0|1] ""  RDR05
 SG_ DET_CONFD_AZIMUTH_084_Rx : 454|2@1+ (1,0) [0|3] ""  RDR05
 SG_ DET_CONFD_ELEVATION_084_Rx : 437|2@1+ (1,0) [0|3] ""  RDR05
 SG_ DET_MH_SCAN_INDEX_4LSB_081_084_R : 476|4@1+ (1,0) [0|15] ""  RDR05
 SG_ DET_MH_CYCLE_COUNTER_081_084_Rx : 16|8@1+ (1,0) [0|255] ""  RDR05
 SG_ DET_MH_CRC16_081_084_Rx : 0|16@1+ (1,0) [0|65535] ""  RDR05
 SG_ DET_PROB_1STAZHYPO_084_Rx : 439|1@1+ (1,0) [0|1] ""  RDR05
 SG_ DET_IDM_084_Rx : 399|1@1+ (1,0) [0|1] ""  RDR05
 SG_ DET_MTD_084_Rx : 383|1@1+ (1,0) [0|1] ""  RDR05
 SG_ DET_BELOW_RAIN_THOLD_084_Rx : 375|1@1+ (1,0) [0|1] ""  RDR05

BO_ 277 RDR_FUSION_DET_085_088: 64 RDR_Fusion_Partner
 SG_ DET_RANGE_085_Rx : 24|15@1+ (0.015625,0) [0|500] "m"  RDR05
 SG_ DET_RANGE_ERR_085_Rx : 40|7@1+ (0.0075,0) [0|0.9525] "m"  RDR05
 SG_ DET_RANGE_VELOCITY_085_Rx : 48|15@1+ (0.0078125,-128) [-128|127.9921875] "m/s"  RDR05
 SG_ DET_RANGE_VELOCITY_ERR_085_Rx : 64|8@1+ (0.003,0) [0|0.765] "m/s"  RDR05
 SG_ DET_AZIMUTH_085_Rx : 88|13@1+ (0.0004,-1.5708) [-1.5708|1.5708] "rad"  RDR05
 SG_ DET_AZIMUTH_ERR_085_Rx : 105|7@1+ (0.00087267,0) [0|0.11082909] "rad"  RDR05
 SG_ DET_ELEVATION_085_Rx : 72|8@1+ (0.00275,-0.34925) [-0.34925|0.34925] "rad"  RDR05
 SG_ DET_ELEVATION_ERR_085_Rx : 80|6@1+ (0.00174533,0) [0|0.10995579] "rad"  RDR05
 SG_ DET_RCS_085_Rx : 128|8@1+ (0.5,-64) [-64|63.5] "dBsm"  RDR05
 SG_ DET_BI_STATIC_FLAG_085_Rx : 104|1@1+ (1,0) [0|1] ""  RDR05
 SG_ DET_SUPER_RES_TARGET_085_Rx : 87|1@1+ (1,0) [0|1] ""  RDR05
 SG_ DET_SNR_085_Rx : 120|8@1+ (0.35156,0) [0|89.6478] "dB"  RDR05
 SG_ DET_EXISTENCE_PROB_085_Rx : 112|6@1+ (1.588,0) [0|100] "%"  RDR05
 SG_ DET_HVC_FLAG_085_Rx : 86|1@1+ (1,0) [0|1] ""  RDR05
 SG_ DET_CONFD_AZIMUTH_085_Rx : 118|2@1+ (1,0) [0|3] ""  RDR05
 SG_ DET_CONFD_ELEVATION_085_Rx : 101|2@1+ (1,0) [0|3] ""  RDR05
 SG_ DET_PROB_1STAZHYPO_085_Rx : 103|1@1+ (1,0) [0|1] ""  RDR05
 SG_ DET_IDM_085_Rx : 63|1@1+ (1,0) [0|1] ""  RDR05
 SG_ DET_MTD_085_Rx : 47|1@1+ (1,0) [0|1] ""  RDR05
 SG_ DET_BELOW_RAIN_THOLD_085_Rx : 39|1@1+ (1,0) [0|1] ""  RDR05
 SG_ DET_RANGE_086_Rx : 136|15@1+ (0.015625,0) [0|500] "m"  RDR05
 SG_ DET_RANGE_ERR_086_Rx : 152|7@1+ (0.0075,0) [0|0.9525] "m"  RDR05
 SG_ DET_RANGE_VELOCITY_086_Rx : 160|15@1+ (0.0078125,-128) [-128|127.9921875] "m/s"  RDR05
 SG_ DET_RANGE_VELOCITY_ERR_086_Rx : 176|8@1+ (0.003,0) [0|0.765] "m/s"  RDR05
 SG_ DET_AZIMUTH_086_Rx : 200|13@1+ (0.0004,-1.5708) [-1.5708|1.5708] "rad"  RDR05
 SG_ DET_AZIMUTH_ERR_086_Rx : 217|7@1+ (0.00087267,0) [0|0.11082909] "rad"  RDR05
 SG_ DET_ELEVATION_086_Rx : 184|8@1+ (0.00275,-0.34925) [-0.34925|0.34925] "rad"  RDR05
 SG_ DET_ELEVATION_ERR_086_Rx : 192|6@1+ (0.00174533,0) [0|0.10995579] "rad"  RDR05
 SG_ DET_RCS_086_Rx : 240|8@1+ (0.5,-64) [-64|63.5] "dBsm"  RDR05
 SG_ DET_BI_STATIC_FLAG_086_Rx : 216|1@1+ (1,0) [0|1] ""  RDR05
 SG_ DET_SUPER_RES_TARGET_086_Rx : 199|1@1+ (1,0) [0|1] ""  RDR05
 SG_ DET_SNR_086_Rx : 232|8@1+ (0.35156,0) [0|89.6478] "dB"  RDR05
 SG_ DET_EXISTENCE_PROB_086_Rx : 224|6@1+ (1.588,0) [0|100] "%"  RDR05
 SG_ DET_HVC_FLAG_086_Rx : 198|1@1+ (1,0) [0|1] ""  RDR05
 SG_ DET_CONFD_AZIMUTH_086_Rx : 230|2@1+ (1,0) [0|3] ""  RDR05
 SG_ DET_CONFD_ELEVATION_086_Rx : 213|2@1+ (1,0) [0|3] ""  RDR05
 SG_ DET_PROB_1STAZHYPO_086_Rx : 215|1@1+ (1,0) [0|1] ""  RDR05
 SG_ DET_IDM_086_Rx : 175|1@1+ (1,0) [0|1] ""  RDR05
 SG_ DET_MTD_086_Rx : 159|1@1+ (1,0) [0|1] ""  RDR05
 SG_ DET_BELOW_RAIN_THOLD_086_Rx : 151|1@1+ (1,0) [0|1] ""  RDR05
 SG_ DET_RANGE_087_Rx : 248|15@1+ (0.015625,0) [0|500] "m"  RDR05
 SG_ DET_RANGE_ERR_087_Rx : 264|7@1+ (0.0075,0) [0|0.9525] "m"  RDR05
 SG_ DET_RANGE_VELOCITY_087_Rx : 272|15@1+ (0.0078125,-128) [-128|127.9921875] "m/s"  RDR05
 SG_ DET_RANGE_VELOCITY_ERR_087_Rx : 288|8@1+ (0.003,0) [0|0.765] "m/s"  RDR05
 SG_ DET_AZIMUTH_087_Rx : 312|13@1+ (0.0004,-1.5708) [-1.5708|1.5708] "rad"  RDR05
 SG_ DET_AZIMUTH_ERR_087_Rx : 329|7@1+ (0.00087267,0) [0|0.11082909] "rad"  RDR05
 SG_ DET_ELEVATION_087_Rx : 296|8@1+ (0.00275,-0.34925) [-0.34925|0.34925] "rad"  RDR05
 SG_ DET_ELEVATION_ERR_087_Rx : 304|6@1+ (0.00174533,0) [0|0.10995579] "rad"  RDR05
 SG_ DET_RCS_087_Rx : 352|8@1+ (0.5,-64) [-64|63.5] "dBsm"  RDR05
 SG_ DET_BI_STATIC_FLAG_087_Rx : 328|1@1+ (1,0) [0|1] ""  RDR05
 SG_ DET_SUPER_RES_TARGET_087_Rx : 311|1@1+ (1,0) [0|1] ""  RDR05
 SG_ DET_SNR_087_Rx : 344|8@1+ (0.35156,0) [0|89.6478] "dB"  RDR05
 SG_ DET_EXISTENCE_PROB_087_Rx : 336|6@1+ (1.588,0) [0|100] "%"  RDR05
 SG_ DET_HVC_FLAG_087_Rx : 310|1@1+ (1,0) [0|1] ""  RDR05
 SG_ DET_CONFD_AZIMUTH_087_Rx : 342|2@1+ (1,0) [0|3] ""  RDR05
 SG_ DET_CONFD_ELEVATION_087_Rx : 325|2@1+ (1,0) [0|3] ""  RDR05
 SG_ DET_PROB_1STAZHYPO_087_Rx : 327|1@1+ (1,0) [0|1] ""  RDR05
 SG_ DET_IDM_087_Rx : 287|1@1+ (1,0) [0|1] ""  RDR05
 SG_ DET_MTD_087_Rx : 271|1@1+ (1,0) [0|1] ""  RDR05
 SG_ DET_BELOW_RAIN_THOLD_087_Rx : 263|1@1+ (1,0) [0|1] ""  RDR05
 SG_ DET_RANGE_088_Rx : 360|15@1+ (0.015625,0) [0|500] "m"  RDR05
 SG_ DET_RANGE_ERR_088_Rx : 376|7@1+ (0.0075,0) [0|0.9525] "m"  RDR05
 SG_ DET_RANGE_VELOCITY_088_Rx : 384|15@1+ (0.0078125,-128) [-128|127.9921875] "m/s"  RDR05
 SG_ DET_RANGE_VELOCITY_ERR_088_Rx : 400|8@1+ (0.003,0) [0|0.765] "m/s"  RDR05
 SG_ DET_AZIMUTH_088_Rx : 424|13@1+ (0.0004,-1.5708) [-1.5708|1.5708] "rad"  RDR05
 SG_ DET_AZIMUTH_ERR_088_Rx : 441|7@1+ (0.00087267,0) [0|0.11082909] "rad"  RDR05
 SG_ DET_ELEVATION_088_Rx : 408|8@1+ (0.00275,-0.34925) [-0.34925|0.34925] "rad"  RDR05
 SG_ DET_ELEVATION_ERR_088_Rx : 416|6@1+ (0.00174533,0) [0|0.10995579] "rad"  RDR05
 SG_ DET_RCS_088_Rx : 464|8@1+ (0.5,-64) [-64|63.5] "dBsm"  RDR05
 SG_ DET_BI_STATIC_FLAG_088_Rx : 440|1@1+ (1,0) [0|1] ""  RDR05
 SG_ DET_SUPER_RES_TARGET_088_Rx : 423|1@1+ (1,0) [0|1] ""  RDR05
 SG_ DET_SNR_088_Rx : 456|8@1+ (0.35156,0) [0|89.6478] "dB"  RDR05
 SG_ DET_EXISTENCE_PROB_088_Rx : 448|6@1+ (1.588,0) [0|100] "%"  RDR05
 SG_ DET_HVC_FLAG_088_Rx : 422|1@1+ (1,0) [0|1] ""  RDR05
 SG_ DET_CONFD_AZIMUTH_088_Rx : 454|2@1+ (1,0) [0|3] ""  RDR05
 SG_ DET_CONFD_ELEVATION_088_Rx : 437|2@1+ (1,0) [0|3] ""  RDR05
 SG_ DET_MH_SCAN_INDEX_4LSB_085_088_R : 476|4@1+ (1,0) [0|15] ""  RDR05
 SG_ DET_MH_CYCLE_COUNTER_085_088_Rx : 16|8@1+ (1,0) [0|255] ""  RDR05
 SG_ DET_MH_CRC16_085_088_Rx : 0|16@1+ (1,0) [0|65535] ""  RDR05
 SG_ DET_PROB_1STAZHYPO_088_Rx : 439|1@1+ (1,0) [0|1] ""  RDR05
 SG_ DET_IDM_088_Rx : 399|1@1+ (1,0) [0|1] ""  RDR05
 SG_ DET_MTD_088_Rx : 383|1@1+ (1,0) [0|1] ""  RDR05
 SG_ DET_BELOW_RAIN_THOLD_088_Rx : 375|1@1+ (1,0) [0|1] ""  RDR05

BO_ 278 RDR_FUSION_DET_089_092: 64 RDR_Fusion_Partner
 SG_ DET_RANGE_089_Rx : 24|15@1+ (0.015625,0) [0|500] "m"  RDR05
 SG_ DET_RANGE_ERR_089_Rx : 40|7@1+ (0.0075,0) [0|0.9525] "m"  RDR05
 SG_ DET_RANGE_VELOCITY_089_Rx : 48|15@1+ (0.0078125,-128) [-128|127.9921875] "m/s"  RDR05
 SG_ DET_RANGE_VELOCITY_ERR_089_Rx : 64|8@1+ (0.003,0) [0|0.765] "m/s"  RDR05
 SG_ DET_AZIMUTH_089_Rx : 88|13@1+ (0.0004,-1.5708) [-1.5708|1.5708] "rad"  RDR05
 SG_ DET_AZIMUTH_ERR_089_Rx : 105|7@1+ (0.00087267,0) [0|0.11082909] "rad"  RDR05
 SG_ DET_ELEVATION_089_Rx : 72|8@1+ (0.00275,-0.34925) [-0.34925|0.34925] "rad"  RDR05
 SG_ DET_ELEVATION_ERR_089_Rx : 80|6@1+ (0.00174533,0) [0|0.10995579] "rad"  RDR05
 SG_ DET_RCS_089_Rx : 128|8@1+ (0.5,-64) [-64|63.5] "dBsm"  RDR05
 SG_ DET_BI_STATIC_FLAG_089_Rx : 104|1@1+ (1,0) [0|1] ""  RDR05
 SG_ DET_SUPER_RES_TARGET_089_Rx : 87|1@1+ (1,0) [0|1] ""  RDR05
 SG_ DET_SNR_089_Rx : 120|8@1+ (0.35156,0) [0|89.6478] "dB"  RDR05
 SG_ DET_EXISTENCE_PROB_089_Rx : 112|6@1+ (1.588,0) [0|100] "%"  RDR05
 SG_ DET_HVC_FLAG_089_Rx : 86|1@1+ (1,0) [0|1] ""  RDR05
 SG_ DET_CONFD_AZIMUTH_089_Rx : 118|2@1+ (1,0) [0|3] ""  RDR05
 SG_ DET_CONFD_ELEVATION_089_Rx : 101|2@1+ (1,0) [0|3] ""  RDR05
 SG_ DET_PROB_1STAZHYPO_089_Rx : 103|1@1+ (1,0) [0|1] ""  RDR05
 SG_ DET_IDM_089_Rx : 63|1@1+ (1,0) [0|1] ""  RDR05
 SG_ DET_MTD_089_Rx : 47|1@1+ (1,0) [0|1] ""  RDR05
 SG_ DET_BELOW_RAIN_THOLD_089_Rx : 39|1@1+ (1,0) [0|1] ""  RDR05
 SG_ DET_RANGE_090_Rx : 136|15@1+ (0.015625,0) [0|500] "m"  RDR05
 SG_ DET_RANGE_ERR_090_Rx : 152|7@1+ (0.0075,0) [0|0.9525] "m"  RDR05
 SG_ DET_RANGE_VELOCITY_090_Rx : 160|15@1+ (0.0078125,-128) [-128|127.9921875] "m/s"  RDR05
 SG_ DET_RANGE_VELOCITY_ERR_090_Rx : 176|8@1+ (0.003,0) [0|0.765] "m/s"  RDR05
 SG_ DET_AZIMUTH_090_Rx : 200|13@1+ (0.0004,-1.5708) [-1.5708|1.5708] "rad"  RDR05
 SG_ DET_AZIMUTH_ERR_090_Rx : 217|7@1+ (0.00087267,0) [0|0.11082909] "rad"  RDR05
 SG_ DET_ELEVATION_090_Rx : 184|8@1+ (0.00275,-0.34925) [-0.34925|0.34925] "rad"  RDR05
 SG_ DET_ELEVATION_ERR_090_Rx : 192|6@1+ (0.00174533,0) [0|0.10995579] "rad"  RDR05
 SG_ DET_RCS_090_Rx : 240|8@1+ (0.5,-64) [-64|63.5] "dBsm"  RDR05
 SG_ DET_BI_STATIC_FLAG_090_Rx : 216|1@1+ (1,0) [0|1] ""  RDR05
 SG_ DET_SUPER_RES_TARGET_090_Rx : 199|1@1+ (1,0) [0|1] ""  RDR05
 SG_ DET_SNR_090_Rx : 232|8@1+ (0.35156,0) [0|89.6478] "dB"  RDR05
 SG_ DET_EXISTENCE_PROB_090_Rx : 224|6@1+ (1.588,0) [0|100] "%"  RDR05
 SG_ DET_HVC_FLAG_090_Rx : 198|1@1+ (1,0) [0|1] ""  RDR05
 SG_ DET_CONFD_AZIMUTH_090_Rx : 230|2@1+ (1,0) [0|3] ""  RDR05
 SG_ DET_CONFD_ELEVATION_090_Rx : 213|2@1+ (1,0) [0|3] ""  RDR05
 SG_ DET_PROB_1STAZHYPO_090_Rx : 215|1@1+ (1,0) [0|1] ""  RDR05
 SG_ DET_IDM_090_Rx : 175|1@1+ (1,0) [0|1] ""  RDR05
 SG_ DET_MTD_090_Rx : 159|1@1+ (1,0) [0|1] ""  RDR05
 SG_ DET_BELOW_RAIN_THOLD_090_Rx : 151|1@1+ (1,0) [0|1] ""  RDR05
 SG_ DET_RANGE_091_Rx : 248|15@1+ (0.015625,0) [0|500] "m"  RDR05
 SG_ DET_RANGE_ERR_091_Rx : 264|7@1+ (0.0075,0) [0|0.9525] "m"  RDR05
 SG_ DET_RANGE_VELOCITY_091_Rx : 272|15@1+ (0.0078125,-128) [-128|127.9921875] "m/s"  RDR05
 SG_ DET_RANGE_VELOCITY_ERR_091_Rx : 288|8@1+ (0.003,0) [0|0.765] "m/s"  RDR05
 SG_ DET_AZIMUTH_091_Rx : 312|13@1+ (0.0004,-1.5708) [-1.5708|1.5708] "rad"  RDR05
 SG_ DET_AZIMUTH_ERR_091_Rx : 329|7@1+ (0.00087267,0) [0|0.11082909] "rad"  RDR05
 SG_ DET_ELEVATION_091_Rx : 296|8@1+ (0.00275,-0.34925) [-0.34925|0.34925] "rad"  RDR05
 SG_ DET_ELEVATION_ERR_091_Rx : 304|6@1+ (0.00174533,0) [0|0.10995579] "rad"  RDR05
 SG_ DET_RCS_091_Rx : 352|8@1+ (0.5,-64) [-64|63.5] "dBsm"  RDR05
 SG_ DET_BI_STATIC_FLAG_091_Rx : 328|1@1+ (1,0) [0|1] ""  RDR05
 SG_ DET_SUPER_RES_TARGET_091_Rx : 311|1@1+ (1,0) [0|1] ""  RDR05
 SG_ DET_SNR_091_Rx : 344|8@1+ (0.35156,0) [0|89.6478] "dB"  RDR05
 SG_ DET_EXISTENCE_PROB_091_Rx : 336|6@1+ (1.588,0) [0|100] "%"  RDR05
 SG_ DET_HVC_FLAG_091_Rx : 310|1@1+ (1,0) [0|1] ""  RDR05
 SG_ DET_CONFD_AZIMUTH_091_Rx : 342|2@1+ (1,0) [0|3] ""  RDR05
 SG_ DET_CONFD_ELEVATION_091_Rx : 325|2@1+ (1,0) [0|3] ""  RDR05
 SG_ DET_PROB_1STAZHYPO_091_Rx : 327|1@1+ (1,0) [0|1] ""  RDR05
 SG_ DET_IDM_091_Rx : 287|1@1+ (1,0) [0|1] ""  RDR05
 SG_ DET_MTD_091_Rx : 271|1@1+ (1,0) [0|1] ""  RDR05
 SG_ DET_BELOW_RAIN_THOLD_091_Rx : 263|1@1+ (1,0) [0|1] ""  RDR05
 SG_ DET_RANGE_092_Rx : 360|15@1+ (0.015625,0) [0|500] "m"  RDR05
 SG_ DET_RANGE_ERR_092_Rx : 376|7@1+ (0.0075,0) [0|0.9525] "m"  RDR05
 SG_ DET_RANGE_VELOCITY_092_Rx : 384|15@1+ (0.0078125,-128) [-128|127.9921875] "m/s"  RDR05
 SG_ DET_RANGE_VELOCITY_ERR_092_Rx : 400|8@1+ (0.003,0) [0|0.765] "m/s"  RDR05
 SG_ DET_AZIMUTH_092_Rx : 424|13@1+ (0.0004,-1.5708) [-1.5708|1.5708] "rad"  RDR05
 SG_ DET_AZIMUTH_ERR_092_Rx : 441|7@1+ (0.00087267,0) [0|0.11082909] "rad"  RDR05
 SG_ DET_ELEVATION_092_Rx : 408|8@1+ (0.00275,-0.34925) [-0.34925|0.34925] "rad"  RDR05
 SG_ DET_ELEVATION_ERR_092_Rx : 416|6@1+ (0.00174533,0) [0|0.10995579] "rad"  RDR05
 SG_ DET_RCS_092_Rx : 464|8@1+ (0.5,-64) [-64|63.5] "dBsm"  RDR05
 SG_ DET_BI_STATIC_FLAG_092_Rx : 440|1@1+ (1,0) [0|1] ""  RDR05
 SG_ DET_SUPER_RES_TARGET_092_Rx : 423|1@1+ (1,0) [0|1] ""  RDR05
 SG_ DET_SNR_092_Rx : 456|8@1+ (0.35156,0) [0|89.6478] "dB"  RDR05
 SG_ DET_EXISTENCE_PROB_092_Rx : 448|6@1+ (1.588,0) [0|100] "%"  RDR05
 SG_ DET_HVC_FLAG_092_Rx : 422|1@1+ (1,0) [0|1] ""  RDR05
 SG_ DET_CONFD_AZIMUTH_092_Rx : 454|2@1+ (1,0) [0|3] ""  RDR05
 SG_ DET_CONFD_ELEVATION_092_Rx : 437|2@1+ (1,0) [0|3] ""  RDR05
 SG_ DET_MH_SCAN_INDEX_4LSB_089_092_R : 476|4@1+ (1,0) [0|15] ""  RDR05
 SG_ DET_MH_CYCLE_COUNTER_089_092_Rx : 16|8@1+ (1,0) [0|255] ""  RDR05
 SG_ DET_MH_CRC16_089_092_Rx : 0|16@1+ (1,0) [0|65535] ""  RDR05
 SG_ DET_PROB_1STAZHYPO_092_Rx : 439|1@1+ (1,0) [0|1] ""  RDR05
 SG_ DET_IDM_092_Rx : 399|1@1+ (1,0) [0|1] ""  RDR05
 SG_ DET_MTD_092_Rx : 383|1@1+ (1,0) [0|1] ""  RDR05
 SG_ DET_BELOW_RAIN_THOLD_092_Rx : 375|1@1+ (1,0) [0|1] ""  RDR05

BO_ 279 RDR_FUSION_DET_093_096: 64 RDR_Fusion_Partner
 SG_ DET_RANGE_093_Rx : 24|15@1+ (0.015625,0) [0|500] "m"  RDR05
 SG_ DET_RANGE_ERR_093_Rx : 40|7@1+ (0.0075,0) [0|0.9525] "m"  RDR05
 SG_ DET_RANGE_VELOCITY_093_Rx : 48|15@1+ (0.0078125,-128) [-128|127.9921875] "m/s"  RDR05
 SG_ DET_RANGE_VELOCITY_ERR_093_Rx : 64|8@1+ (0.003,0) [0|0.765] "m/s"  RDR05
 SG_ DET_AZIMUTH_093_Rx : 88|13@1+ (0.0004,-1.5708) [-1.5708|1.5708] "rad"  RDR05
 SG_ DET_AZIMUTH_ERR_093_Rx : 105|7@1+ (0.00087267,0) [0|0.11082909] "rad"  RDR05
 SG_ DET_ELEVATION_093_Rx : 72|8@1+ (0.00275,-0.34925) [-0.34925|0.34925] "rad"  RDR05
 SG_ DET_ELEVATION_ERR_093_Rx : 80|6@1+ (0.00174533,0) [0|0.10995579] "rad"  RDR05
 SG_ DET_RCS_093_Rx : 128|8@1+ (0.5,-64) [-64|63.5] "dBsm"  RDR05
 SG_ DET_BI_STATIC_FLAG_093_Rx : 104|1@1+ (1,0) [0|1] ""  RDR05
 SG_ DET_SUPER_RES_TARGET_093_Rx : 87|1@1+ (1,0) [0|1] ""  RDR05
 SG_ DET_SNR_093_Rx : 120|8@1+ (0.35156,0) [0|89.6478] "dB"  RDR05
 SG_ DET_EXISTENCE_PROB_093_Rx : 112|6@1+ (1.588,0) [0|100] "%"  RDR05
 SG_ DET_HVC_FLAG_093_Rx : 86|1@1+ (1,0) [0|1] ""  RDR05
 SG_ DET_CONFD_AZIMUTH_093_Rx : 118|2@1+ (1,0) [0|3] ""  RDR05
 SG_ DET_CONFD_ELEVATION_093_Rx : 101|2@1+ (1,0) [0|3] ""  RDR05
 SG_ DET_PROB_1STAZHYPO_093_Rx : 103|1@1+ (1,0) [0|1] ""  RDR05
 SG_ DET_IDM_093_Rx : 63|1@1+ (1,0) [0|1] ""  RDR05
 SG_ DET_MTD_093_Rx : 47|1@1+ (1,0) [0|1] ""  RDR05
 SG_ DET_BELOW_RAIN_THOLD_093_Rx : 39|1@1+ (1,0) [0|1] ""  RDR05
 SG_ DET_RANGE_094_Rx : 136|15@1+ (0.015625,0) [0|500] "m"  RDR05
 SG_ DET_RANGE_ERR_094_Rx : 152|7@1+ (0.0075,0) [0|0.9525] "m"  RDR05
 SG_ DET_RANGE_VELOCITY_094_Rx : 160|15@1+ (0.0078125,-128) [-128|127.9921875] "m/s"  RDR05
 SG_ DET_RANGE_VELOCITY_ERR_094_Rx : 176|8@1+ (0.003,0) [0|0.765] "m/s"  RDR05
 SG_ DET_AZIMUTH_094_Rx : 200|13@1+ (0.0004,-1.5708) [-1.5708|1.5708] "rad"  RDR05
 SG_ DET_AZIMUTH_ERR_094_Rx : 217|7@1+ (0.00087267,0) [0|0.11082909] "rad"  RDR05
 SG_ DET_ELEVATION_094_Rx : 184|8@1+ (0.00275,-0.34925) [-0.34925|0.34925] "rad"  RDR05
 SG_ DET_ELEVATION_ERR_094_Rx : 192|6@1+ (0.00174533,0) [0|0.10995579] "rad"  RDR05
 SG_ DET_RCS_094_Rx : 240|8@1+ (0.5,-64) [-64|63.5] "dBsm"  RDR05
 SG_ DET_BI_STATIC_FLAG_094_Rx : 216|1@1+ (1,0) [0|1] ""  RDR05
 SG_ DET_SUPER_RES_TARGET_094_Rx : 199|1@1+ (1,0) [0|1] ""  RDR05
 SG_ DET_SNR_094_Rx : 232|8@1+ (0.35156,0) [0|89.6478] "dB"  RDR05
 SG_ DET_EXISTENCE_PROB_094_Rx : 224|6@1+ (1.588,0) [0|100] "%"  RDR05
 SG_ DET_HVC_FLAG_094_Rx : 198|1@1+ (1,0) [0|1] ""  RDR05
 SG_ DET_CONFD_AZIMUTH_094_Rx : 230|2@1+ (1,0) [0|3] ""  RDR05
 SG_ DET_CONFD_ELEVATION_094_Rx : 213|2@1+ (1,0) [0|3] ""  RDR05
 SG_ DET_PROB_1STAZHYPO_094_Rx : 215|1@1+ (1,0) [0|1] ""  RDR05
 SG_ DET_IDM_094_Rx : 175|1@1+ (1,0) [0|1] ""  RDR05
 SG_ DET_MTD_094_Rx : 159|1@1+ (1,0) [0|1] ""  RDR05
 SG_ DET_BELOW_RAIN_THOLD_094_Rx : 151|1@1+ (1,0) [0|1] ""  RDR05
 SG_ DET_RANGE_095_Rx : 248|15@1+ (0.015625,0) [0|500] "m"  RDR05
 SG_ DET_RANGE_ERR_095_Rx : 264|7@1+ (0.0075,0) [0|0.9525] "m"  RDR05
 SG_ DET_RANGE_VELOCITY_095_Rx : 272|15@1+ (0.0078125,-128) [-128|127.9921875] "m/s"  RDR05
 SG_ DET_RANGE_VELOCITY_ERR_095_Rx : 288|8@1+ (0.003,0) [0|0.765] "m/s"  RDR05
 SG_ DET_AZIMUTH_095_Rx : 312|13@1+ (0.0004,-1.5708) [-1.5708|1.5708] "rad"  RDR05
 SG_ DET_AZIMUTH_ERR_095_Rx : 329|7@1+ (0.00087267,0) [0|0.11082909] "rad"  RDR05
 SG_ DET_ELEVATION_095_Rx : 296|8@1+ (0.00275,-0.34925) [-0.34925|0.34925] "rad"  RDR05
 SG_ DET_ELEVATION_ERR_095_Rx : 304|6@1+ (0.00174533,0) [0|0.10995579] "rad"  RDR05
 SG_ DET_RCS_095_Rx : 352|8@1+ (0.5,-64) [-64|63.5] "dBsm"  RDR05
 SG_ DET_BI_STATIC_FLAG_095_Rx : 328|1@1+ (1,0) [0|1] ""  RDR05
 SG_ DET_SUPER_RES_TARGET_095_Rx : 311|1@1+ (1,0) [0|1] ""  RDR05
 SG_ DET_SNR_095_Rx : 344|8@1+ (0.35156,0) [0|89.6478] "dB"  RDR05
 SG_ DET_EXISTENCE_PROB_095_Rx : 336|6@1+ (1.588,0) [0|100] "%"  RDR05
 SG_ DET_HVC_FLAG_095_Rx : 310|1@1+ (1,0) [0|1] ""  RDR05
 SG_ DET_CONFD_AZIMUTH_095_Rx : 342|2@1+ (1,0) [0|3] ""  RDR05
 SG_ DET_CONFD_ELEVATION_095_Rx : 325|2@1+ (1,0) [0|3] ""  RDR05
 SG_ DET_PROB_1STAZHYPO_095_Rx : 327|1@1+ (1,0) [0|1] ""  RDR05
 SG_ DET_IDM_095_Rx : 287|1@1+ (1,0) [0|1] ""  RDR05
 SG_ DET_MTD_095_Rx : 271|1@1+ (1,0) [0|1] ""  RDR05
 SG_ DET_BELOW_RAIN_THOLD_095_Rx : 263|1@1+ (1,0) [0|1] ""  RDR05
 SG_ DET_RANGE_096_Rx : 360|15@1+ (0.015625,0) [0|500] "m"  RDR05
 SG_ DET_RANGE_ERR_096_Rx : 376|7@1+ (0.0075,0) [0|0.9525] "m"  RDR05
 SG_ DET_RANGE_VELOCITY_096_Rx : 384|15@1+ (0.0078125,-128) [-128|127.9921875] "m/s"  RDR05
 SG_ DET_RANGE_VELOCITY_ERR_096_Rx : 400|8@1+ (0.003,0) [0|0.765] "m/s"  RDR05
 SG_ DET_AZIMUTH_096_Rx : 424|13@1+ (0.0004,-1.5708) [-1.5708|1.5708] "rad"  RDR05
 SG_ DET_AZIMUTH_ERR_096_Rx : 441|7@1+ (0.00087267,0) [0|0.11082909] "rad"  RDR05
 SG_ DET_ELEVATION_096_Rx : 408|8@1+ (0.00275,-0.34925) [-0.34925|0.34925] "rad"  RDR05
 SG_ DET_ELEVATION_ERR_096_Rx : 416|6@1+ (0.00174533,0) [0|0.10995579] "rad"  RDR05
 SG_ DET_RCS_096_Rx : 464|8@1+ (0.5,-64) [-64|63.5] "dBsm"  RDR05
 SG_ DET_BI_STATIC_FLAG_096_Rx : 440|1@1+ (1,0) [0|1] ""  RDR05
 SG_ DET_SUPER_RES_TARGET_096_Rx : 423|1@1+ (1,0) [0|1] ""  RDR05
 SG_ DET_SNR_096_Rx : 456|8@1+ (0.35156,0) [0|89.6478] "dB"  RDR05
 SG_ DET_EXISTENCE_PROB_096_Rx : 448|6@1+ (1.588,0) [0|100] "%"  RDR05
 SG_ DET_HVC_FLAG_096_Rx : 422|1@1+ (1,0) [0|1] ""  RDR05
 SG_ DET_CONFD_AZIMUTH_096_Rx : 454|2@1+ (1,0) [0|3] ""  RDR05
 SG_ DET_CONFD_ELEVATION_096_Rx : 437|2@1+ (1,0) [0|3] ""  RDR05
 SG_ DET_MH_SCAN_INDEX_4LSB_093_096_R : 476|4@1+ (1,0) [0|15] ""  RDR05
 SG_ DET_MH_CYCLE_COUNTER_093_096_Rx : 16|8@1+ (1,0) [0|255] ""  RDR05
 SG_ DET_MH_CRC16_093_096_Rx : 0|16@1+ (1,0) [0|65535] ""  RDR05
 SG_ DET_PROB_1STAZHYPO_096_Rx : 439|1@1+ (1,0) [0|1] ""  RDR05
 SG_ DET_IDM_096_Rx : 399|1@1+ (1,0) [0|1] ""  RDR05
 SG_ DET_MTD_096_Rx : 383|1@1+ (1,0) [0|1] ""  RDR05
 SG_ DET_BELOW_RAIN_THOLD_096_Rx : 375|1@1+ (1,0) [0|1] ""  RDR05

BO_ 280 RDR_FUSION_DET_097_100: 64 RDR_Fusion_Partner
 SG_ DET_RANGE_097_Rx : 24|15@1+ (0.015625,0) [0|500] "m"  RDR05
 SG_ DET_RANGE_ERR_097_Rx : 40|7@1+ (0.0075,0) [0|0.9525] "m"  RDR05
 SG_ DET_RANGE_VELOCITY_097_Rx : 48|15@1+ (0.0078125,-128) [-128|127.9921875] "m/s"  RDR05
 SG_ DET_RANGE_VELOCITY_ERR_097_Rx : 64|8@1+ (0.003,0) [0|0.765] "m/s"  RDR05
 SG_ DET_AZIMUTH_097_Rx : 88|13@1+ (0.0004,-1.5708) [-1.5708|1.5708] "rad"  RDR05
 SG_ DET_AZIMUTH_ERR_097_Rx : 105|7@1+ (0.00087267,0) [0|0.11082909] "rad"  RDR05
 SG_ DET_ELEVATION_097_Rx : 72|8@1+ (0.00275,-0.34925) [-0.34925|0.34925] "rad"  RDR05
 SG_ DET_ELEVATION_ERR_097_Rx : 80|6@1+ (0.00174533,0) [0|0.10995579] "rad"  RDR05
 SG_ DET_RCS_097_Rx : 128|8@1+ (0.5,-64) [-64|63.5] "dBsm"  RDR05
 SG_ DET_BI_STATIC_FLAG_097_Rx : 104|1@1+ (1,0) [0|1] ""  RDR05
 SG_ DET_SUPER_RES_TARGET_097_Rx : 87|1@1+ (1,0) [0|1] ""  RDR05
 SG_ DET_SNR_097_Rx : 120|8@1+ (0.35156,0) [0|89.6478] "dB"  RDR05
 SG_ DET_EXISTENCE_PROB_097_Rx : 112|6@1+ (1.588,0) [0|100] "%"  RDR05
 SG_ DET_HVC_FLAG_097_Rx : 86|1@1+ (1,0) [0|1] ""  RDR05
 SG_ DET_CONFD_AZIMUTH_097_Rx : 118|2@1+ (1,0) [0|3] ""  RDR05
 SG_ DET_CONFD_ELEVATION_097_Rx : 101|2@1+ (1,0) [0|3] ""  RDR05
 SG_ DET_PROB_1STAZHYPO_097_Rx : 103|1@1+ (1,0) [0|1] ""  RDR05
 SG_ DET_IDM_097_Rx : 63|1@1+ (1,0) [0|1] ""  RDR05
 SG_ DET_MTD_097_Rx : 47|1@1+ (1,0) [0|1] ""  RDR05
 SG_ DET_BELOW_RAIN_THOLD_097_Rx : 39|1@1+ (1,0) [0|1] ""  RDR05
 SG_ DET_RANGE_098_Rx : 136|15@1+ (0.015625,0) [0|500] "m"  RDR05
 SG_ DET_RANGE_ERR_098_Rx : 152|7@1+ (0.0075,0) [0|0.9525] "m"  RDR05
 SG_ DET_RANGE_VELOCITY_098_Rx : 160|15@1+ (0.0078125,-128) [-128|127.9921875] "m/s"  RDR05
 SG_ DET_RANGE_VELOCITY_ERR_098_Rx : 176|8@1+ (0.003,0) [0|0.765] "m/s"  RDR05
 SG_ DET_AZIMUTH_098_Rx : 200|13@1+ (0.0004,-1.5708) [-1.5708|1.5708] "rad"  RDR05
 SG_ DET_AZIMUTH_ERR_098_Rx : 217|7@1+ (0.00087267,0) [0|0.11082909] "rad"  RDR05
 SG_ DET_ELEVATION_098_Rx : 184|8@1+ (0.00275,-0.34925) [-0.34925|0.34925] "rad"  RDR05
 SG_ DET_ELEVATION_ERR_098_Rx : 192|6@1+ (0.00174533,0) [0|0.10995579] "rad"  RDR05
 SG_ DET_RCS_098_Rx : 240|8@1+ (0.5,-64) [-64|63.5] "dBsm"  RDR05
 SG_ DET_BI_STATIC_FLAG_098_Rx : 216|1@1+ (1,0) [0|1] ""  RDR05
 SG_ DET_SUPER_RES_TARGET_098_Rx : 199|1@1+ (1,0) [0|1] ""  RDR05
 SG_ DET_SNR_098_Rx : 232|8@1+ (0.35156,0) [0|89.6478] "dB"  RDR05
 SG_ DET_EXISTENCE_PROB_098_Rx : 224|6@1+ (1.588,0) [0|100] "%"  RDR05
 SG_ DET_HVC_FLAG_098_Rx : 198|1@1+ (1,0) [0|1] ""  RDR05
 SG_ DET_CONFD_AZIMUTH_098_Rx : 230|2@1+ (1,0) [0|3] ""  RDR05
 SG_ DET_CONFD_ELEVATION_098_Rx : 213|2@1+ (1,0) [0|3] ""  RDR05
 SG_ DET_PROB_1STAZHYPO_098_Rx : 215|1@1+ (1,0) [0|1] ""  RDR05
 SG_ DET_IDM_098_Rx : 175|1@1+ (1,0) [0|1] ""  RDR05
 SG_ DET_MTD_098_Rx : 159|1@1+ (1,0) [0|1] ""  RDR05
 SG_ DET_BELOW_RAIN_THOLD_098_Rx : 151|1@1+ (1,0) [0|1] ""  RDR05
 SG_ DET_RANGE_099_Rx : 248|15@1+ (0.015625,0) [0|500] "m"  RDR05
 SG_ DET_RANGE_ERR_099_Rx : 264|7@1+ (0.0075,0) [0|0.9525] "m"  RDR05
 SG_ DET_RANGE_VELOCITY_099_Rx : 272|15@1+ (0.0078125,-128) [-128|127.9921875] "m/s"  RDR05
 SG_ DET_RANGE_VELOCITY_ERR_099_Rx : 288|8@1+ (0.003,0) [0|0.765] "m/s"  RDR05
 SG_ DET_AZIMUTH_099_Rx : 312|13@1+ (0.0004,-1.5708) [-1.5708|1.5708] "rad"  RDR05
 SG_ DET_AZIMUTH_ERR_099_Rx : 329|7@1+ (0.00087267,0) [0|0.11082909] "rad"  RDR05
 SG_ DET_ELEVATION_099_Rx : 296|8@1+ (0.00275,-0.34925) [-0.34925|0.34925] "rad"  RDR05
 SG_ DET_ELEVATION_ERR_099_Rx : 304|6@1+ (0.00174533,0) [0|0.10995579] "rad"  RDR05
 SG_ DET_RCS_099_Rx : 352|8@1+ (0.5,-64) [-64|63.5] "dBsm"  RDR05
 SG_ DET_BI_STATIC_FLAG_099_Rx : 328|1@1+ (1,0) [0|1] ""  RDR05
 SG_ DET_SUPER_RES_TARGET_099_Rx : 311|1@1+ (1,0) [0|1] ""  RDR05
 SG_ DET_SNR_099_Rx : 344|8@1+ (0.35156,0) [0|89.6478] "dB"  RDR05
 SG_ DET_EXISTENCE_PROB_099_Rx : 336|6@1+ (1.588,0) [0|100] "%"  RDR05
 SG_ DET_HVC_FLAG_099_Rx : 310|1@1+ (1,0) [0|1] ""  RDR05
 SG_ DET_CONFD_AZIMUTH_099_Rx : 342|2@1+ (1,0) [0|3] ""  RDR05
 SG_ DET_CONFD_ELEVATION_099_Rx : 325|2@1+ (1,0) [0|3] ""  RDR05
 SG_ DET_PROB_1STAZHYPO_099_Rx : 327|1@1+ (1,0) [0|1] ""  RDR05
 SG_ DET_IDM_099_Rx : 287|1@1+ (1,0) [0|1] ""  RDR05
 SG_ DET_MTD_099_Rx : 271|1@1+ (1,0) [0|1] ""  RDR05
 SG_ DET_BELOW_RAIN_THOLD_099_Rx : 263|1@1+ (1,0) [0|1] ""  RDR05
 SG_ DET_RANGE_100_Rx : 360|15@1+ (0.015625,0) [0|500] "m"  RDR05
 SG_ DET_RANGE_ERR_100_Rx : 376|7@1+ (0.0075,0) [0|0.9525] "m"  RDR05
 SG_ DET_RANGE_VELOCITY_100_Rx : 384|15@1+ (0.0078125,-128) [-128|127.9921875] "m/s"  RDR05
 SG_ DET_RANGE_VELOCITY_ERR_100_Rx : 400|8@1+ (0.003,0) [0|0.765] "m/s"  RDR05
 SG_ DET_AZIMUTH_100_Rx : 424|13@1+ (0.0004,-1.5708) [-1.5708|1.5708] "rad"  RDR05
 SG_ DET_AZIMUTH_ERR_100_Rx : 441|7@1+ (0.00087267,0) [0|0.11082909] "rad"  RDR05
 SG_ DET_ELEVATION_100_Rx : 408|8@1+ (0.00275,-0.34925) [-0.34925|0.34925] "rad"  RDR05
 SG_ DET_ELEVATION_ERR_100_Rx : 416|6@1+ (0.00174533,0) [0|0.10995579] "rad"  RDR05
 SG_ DET_RCS_100_Rx : 464|8@1+ (0.5,-64) [-64|63.5] "dBsm"  RDR05
 SG_ DET_BI_STATIC_FLAG_100_Rx : 440|1@1+ (1,0) [0|1] ""  RDR05
 SG_ DET_SUPER_RES_TARGET_100_Rx : 423|1@1+ (1,0) [0|1] ""  RDR05
 SG_ DET_SNR_100_Rx : 456|8@1+ (0.35156,0) [0|89.6478] "dB"  RDR05
 SG_ DET_EXISTENCE_PROB_100_Rx : 448|6@1+ (1.588,0) [0|100] "%"  RDR05
 SG_ DET_HVC_FLAG_100_Rx : 422|1@1+ (1,0) [0|1] ""  RDR05
 SG_ DET_CONFD_AZIMUTH_100_Rx : 454|2@1+ (1,0) [0|3] ""  RDR05
 SG_ DET_CONFD_ELEVATION_100_Rx : 437|2@1+ (1,0) [0|3] ""  RDR05
 SG_ DET_MH_SCAN_INDEX_4LSB_097_100_R : 476|4@1+ (1,0) [0|15] ""  RDR05
 SG_ DET_MH_CYCLE_COUNTER_097_100_Rx : 16|8@1+ (1,0) [0|255] ""  RDR05
 SG_ DET_MH_CRC16_097_100_Rx : 0|16@1+ (1,0) [0|65535] ""  RDR05
 SG_ DET_PROB_1STAZHYPO_100_Rx : 439|1@1+ (1,0) [0|1] ""  RDR05
 SG_ DET_IDM_100_Rx : 399|1@1+ (1,0) [0|1] ""  RDR05
 SG_ DET_MTD_100_Rx : 383|1@1+ (1,0) [0|1] ""  RDR05
 SG_ DET_BELOW_RAIN_THOLD_100_Rx : 375|1@1+ (1,0) [0|1] ""  RDR05

BO_ 281 RDR_FUSION_DET_101_104: 64 RDR_Fusion_Partner
 SG_ DET_RANGE_101_Rx : 24|15@1+ (0.015625,0) [0|500] "m"  RDR05
 SG_ DET_RANGE_ERR_101_Rx : 40|7@1+ (0.0075,0) [0|0.9525] "m"  RDR05
 SG_ DET_RANGE_VELOCITY_101_Rx : 48|15@1+ (0.0078125,-128) [-128|127.9921875] "m/s"  RDR05
 SG_ DET_RANGE_VELOCITY_ERR_101_Rx : 64|8@1+ (0.003,0) [0|0.765] "m/s"  RDR05
 SG_ DET_AZIMUTH_101_Rx : 88|13@1+ (0.0004,-1.5708) [-1.5708|1.5708] "rad"  RDR05
 SG_ DET_AZIMUTH_ERR_101_Rx : 105|7@1+ (0.00087267,0) [0|0.11082909] "rad"  RDR05
 SG_ DET_ELEVATION_101_Rx : 72|8@1+ (0.00275,-0.34925) [-0.34925|0.34925] "rad"  RDR05
 SG_ DET_ELEVATION_ERR_101_Rx : 80|6@1+ (0.00174533,0) [0|0.10995579] "rad"  RDR05
 SG_ DET_RCS_101_Rx : 128|8@1+ (0.5,-64) [-64|63.5] "dBsm"  RDR05
 SG_ DET_BI_STATIC_FLAG_101_Rx : 104|1@1+ (1,0) [0|1] ""  RDR05
 SG_ DET_SUPER_RES_TARGET_101_Rx : 87|1@1+ (1,0) [0|1] ""  RDR05
 SG_ DET_SNR_101_Rx : 120|8@1+ (0.35156,0) [0|89.6478] "dB"  RDR05
 SG_ DET_EXISTENCE_PROB_101_Rx : 112|6@1+ (1.588,0) [0|100] "%"  RDR05
 SG_ DET_HVC_FLAG_101_Rx : 86|1@1+ (1,0) [0|1] ""  RDR05
 SG_ DET_CONFD_AZIMUTH_101_Rx : 118|2@1+ (1,0) [0|3] ""  RDR05
 SG_ DET_CONFD_ELEVATION_101_Rx : 101|2@1+ (1,0) [0|3] ""  RDR05
 SG_ DET_PROB_1STAZHYPO_101_Rx : 103|1@1+ (1,0) [0|1] ""  RDR05
 SG_ DET_IDM_101_Rx : 63|1@1+ (1,0) [0|1] ""  RDR05
 SG_ DET_MTD_101_Rx : 47|1@1+ (1,0) [0|1] ""  RDR05
 SG_ DET_BELOW_RAIN_THOLD_101_Rx : 39|1@1+ (1,0) [0|1] ""  RDR05
 SG_ DET_RANGE_102_Rx : 136|15@1+ (0.015625,0) [0|500] "m"  RDR05
 SG_ DET_RANGE_ERR_102_Rx : 152|7@1+ (0.0075,0) [0|0.9525] "m"  RDR05
 SG_ DET_RANGE_VELOCITY_102_Rx : 160|15@1+ (0.0078125,-128) [-128|127.9921875] "m/s"  RDR05
 SG_ DET_RANGE_VELOCITY_ERR_102_Rx : 176|8@1+ (0.003,0) [0|0.765] "m/s"  RDR05
 SG_ DET_AZIMUTH_102_Rx : 200|13@1+ (0.0004,-1.5708) [-1.5708|1.5708] "rad"  RDR05
 SG_ DET_AZIMUTH_ERR_102_Rx : 217|7@1+ (0.00087267,0) [0|0.11082909] "rad"  RDR05
 SG_ DET_ELEVATION_102_Rx : 184|8@1+ (0.00275,-0.34925) [-0.34925|0.34925] "rad"  RDR05
 SG_ DET_ELEVATION_ERR_102_Rx : 192|6@1+ (0.00174533,0) [0|0.10995579] "rad"  RDR05
 SG_ DET_RCS_102_Rx : 240|8@1+ (0.5,-64) [-64|63.5] "dBsm"  RDR05
 SG_ DET_BI_STATIC_FLAG_102_Rx : 216|1@1+ (1,0) [0|1] ""  RDR05
 SG_ DET_SUPER_RES_TARGET_102_Rx : 199|1@1+ (1,0) [0|1] ""  RDR05
 SG_ DET_SNR_102_Rx : 232|8@1+ (0.35156,0) [0|89.6478] "dB"  RDR05
 SG_ DET_EXISTENCE_PROB_102_Rx : 224|6@1+ (1.588,0) [0|100] "%"  RDR05
 SG_ DET_HVC_FLAG_102_Rx : 198|1@1+ (1,0) [0|1] ""  RDR05
 SG_ DET_CONFD_AZIMUTH_102_Rx : 230|2@1+ (1,0) [0|3] ""  RDR05
 SG_ DET_CONFD_ELEVATION_102_Rx : 213|2@1+ (1,0) [0|3] ""  RDR05
 SG_ DET_PROB_1STAZHYPO_102_Rx : 215|1@1+ (1,0) [0|1] ""  RDR05
 SG_ DET_IDM_102_Rx : 175|1@1+ (1,0) [0|1] ""  RDR05
 SG_ DET_MTD_102_Rx : 159|1@1+ (1,0) [0|1] ""  RDR05
 SG_ DET_BELOW_RAIN_THOLD_102_Rx : 151|1@1+ (1,0) [0|1] ""  RDR05
 SG_ DET_RANGE_103_Rx : 248|15@1+ (0.015625,0) [0|500] "m"  RDR05
 SG_ DET_RANGE_ERR_103_Rx : 264|7@1+ (0.0075,0) [0|0.9525] "m"  RDR05
 SG_ DET_RANGE_VELOCITY_103_Rx : 272|15@1+ (0.0078125,-128) [-128|127.9921875] "m/s"  RDR05
 SG_ DET_RANGE_VELOCITY_ERR_103_Rx : 288|8@1+ (0.003,0) [0|0.765] "m/s"  RDR05
 SG_ DET_AZIMUTH_103_Rx : 312|13@1+ (0.0004,-1.5708) [-1.5708|1.5708] "rad"  RDR05
 SG_ DET_AZIMUTH_ERR_103_Rx : 329|7@1+ (0.00087267,0) [0|0.11082909] "rad"  RDR05
 SG_ DET_ELEVATION_103_Rx : 296|8@1+ (0.00275,-0.34925) [-0.34925|0.34925] "rad"  RDR05
 SG_ DET_ELEVATION_ERR_103_Rx : 304|6@1+ (0.00174533,0) [0|0.10995579] "rad"  RDR05
 SG_ DET_RCS_103_Rx : 352|8@1+ (0.5,-64) [-64|63.5] "dBsm"  RDR05
 SG_ DET_BI_STATIC_FLAG_103_Rx : 328|1@1+ (1,0) [0|1] ""  RDR05
 SG_ DET_SUPER_RES_TARGET_103_Rx : 311|1@1+ (1,0) [0|1] ""  RDR05
 SG_ DET_SNR_103_Rx : 344|8@1+ (0.35156,0) [0|89.6478] "dB"  RDR05
 SG_ DET_EXISTENCE_PROB_103_Rx : 336|6@1+ (1.588,0) [0|100] "%"  RDR05
 SG_ DET_HVC_FLAG_103_Rx : 310|1@1+ (1,0) [0|1] ""  RDR05
 SG_ DET_CONFD_AZIMUTH_103_Rx : 342|2@1+ (1,0) [0|3] ""  RDR05
 SG_ DET_CONFD_ELEVATION_103_Rx : 325|2@1+ (1,0) [0|3] ""  RDR05
 SG_ DET_PROB_1STAZHYPO_103_Rx : 327|1@1+ (1,0) [0|1] ""  RDR05
 SG_ DET_IDM_103_Rx : 287|1@1+ (1,0) [0|1] ""  RDR05
 SG_ DET_MTD_103_Rx : 271|1@1+ (1,0) [0|1] ""  RDR05
 SG_ DET_BELOW_RAIN_THOLD_103_Rx : 263|1@1+ (1,0) [0|1] ""  RDR05
 SG_ DET_RANGE_104_Rx : 360|15@1+ (0.015625,0) [0|500] "m"  RDR05
 SG_ DET_RANGE_ERR_104_Rx : 376|7@1+ (0.0075,0) [0|0.9525] "m"  RDR05
 SG_ DET_RANGE_VELOCITY_104_Rx : 384|15@1+ (0.0078125,-128) [-128|127.9921875] "m/s"  RDR05
 SG_ DET_RANGE_VELOCITY_ERR_104_Rx : 400|8@1+ (0.003,0) [0|0.765] "m/s"  RDR05
 SG_ DET_AZIMUTH_104_Rx : 424|13@1+ (0.0004,-1.5708) [-1.5708|1.5708] "rad"  RDR05
 SG_ DET_AZIMUTH_ERR_104_Rx : 441|7@1+ (0.00087267,0) [0|0.11082909] "rad"  RDR05
 SG_ DET_ELEVATION_104_Rx : 408|8@1+ (0.00275,-0.34925) [-0.34925|0.34925] "rad"  RDR05
 SG_ DET_ELEVATION_ERR_104_Rx : 416|6@1+ (0.00174533,0) [0|0.10995579] "rad"  RDR05
 SG_ DET_RCS_104_Rx : 464|8@1+ (0.5,-64) [-64|63.5] "dBsm"  RDR05
 SG_ DET_BI_STATIC_FLAG_104_Rx : 440|1@1+ (1,0) [0|1] ""  RDR05
 SG_ DET_SUPER_RES_TARGET_104_Rx : 423|1@1+ (1,0) [0|1] ""  RDR05
 SG_ DET_SNR_104_Rx : 456|8@1+ (0.35156,0) [0|89.6478] "dB"  RDR05
 SG_ DET_EXISTENCE_PROB_104_Rx : 448|6@1+ (1.588,0) [0|100] "%"  RDR05
 SG_ DET_HVC_FLAG_104_Rx : 422|1@1+ (1,0) [0|1] ""  RDR05
 SG_ DET_CONFD_AZIMUTH_104_Rx : 454|2@1+ (1,0) [0|3] ""  RDR05
 SG_ DET_CONFD_ELEVATION_104_Rx : 437|2@1+ (1,0) [0|3] ""  RDR05
 SG_ DET_MH_SCAN_INDEX_4LSB_101_104_R : 476|4@1+ (1,0) [0|15] ""  RDR05
 SG_ DET_MH_CYCLE_COUNTER_101_104_Rx : 16|8@1+ (1,0) [0|255] ""  RDR05
 SG_ DET_MH_CRC16_101_104_Rx : 0|16@1+ (1,0) [0|65535] ""  RDR05
 SG_ DET_PROB_1STAZHYPO_104_Rx : 439|1@1+ (1,0) [0|1] ""  RDR05
 SG_ DET_IDM_104_Rx : 399|1@1+ (1,0) [0|1] ""  RDR05
 SG_ DET_MTD_104_Rx : 383|1@1+ (1,0) [0|1] ""  RDR05
 SG_ DET_BELOW_RAIN_THOLD_104_Rx : 375|1@1+ (1,0) [0|1] ""  RDR05

BO_ 282 RDR_FUSION_DET_105_108: 64 RDR_Fusion_Partner
 SG_ DET_RANGE_105_Rx : 24|15@1+ (0.015625,0) [0|500] "m"  RDR05
 SG_ DET_RANGE_ERR_105_Rx : 40|7@1+ (0.0075,0) [0|0.9525] "m"  RDR05
 SG_ DET_RANGE_VELOCITY_105_Rx : 48|15@1+ (0.0078125,-128) [-128|127.9921875] "m/s"  RDR05
 SG_ DET_RANGE_VELOCITY_ERR_105_Rx : 64|8@1+ (0.003,0) [0|0.765] "m/s"  RDR05
 SG_ DET_AZIMUTH_105_Rx : 88|13@1+ (0.0004,-1.5708) [-1.5708|1.5708] "rad"  RDR05
 SG_ DET_AZIMUTH_ERR_105_Rx : 105|7@1+ (0.00087267,0) [0|0.11082909] "rad"  RDR05
 SG_ DET_ELEVATION_105_Rx : 72|8@1+ (0.00275,-0.34925) [-0.34925|0.34925] "rad"  RDR05
 SG_ DET_ELEVATION_ERR_105_Rx : 80|6@1+ (0.00174533,0) [0|0.10995579] "rad"  RDR05
 SG_ DET_RCS_105_Rx : 128|8@1+ (0.5,-64) [-64|63.5] "dBsm"  RDR05
 SG_ DET_BI_STATIC_FLAG_105_Rx : 104|1@1+ (1,0) [0|1] ""  RDR05
 SG_ DET_SUPER_RES_TARGET_105_Rx : 87|1@1+ (1,0) [0|1] ""  RDR05
 SG_ DET_SNR_105_Rx : 120|8@1+ (0.35156,0) [0|89.6478] "dB"  RDR05
 SG_ DET_EXISTENCE_PROB_105_Rx : 112|6@1+ (1.588,0) [0|100] "%"  RDR05
 SG_ DET_HVC_FLAG_105_Rx : 86|1@1+ (1,0) [0|1] ""  RDR05
 SG_ DET_CONFD_AZIMUTH_105_Rx : 118|2@1+ (1,0) [0|3] ""  RDR05
 SG_ DET_CONFD_ELEVATION_105_Rx : 101|2@1+ (1,0) [0|3] ""  RDR05
 SG_ DET_PROB_1STAZHYPO_105_Rx : 103|1@1+ (1,0) [0|1] ""  RDR05
 SG_ DET_IDM_105_Rx : 63|1@1+ (1,0) [0|1] ""  RDR05
 SG_ DET_MTD_105_Rx : 47|1@1+ (1,0) [0|1] ""  RDR05
 SG_ DET_BELOW_RAIN_THOLD_105_Rx : 39|1@1+ (1,0) [0|1] ""  RDR05
 SG_ DET_RANGE_106_Rx : 136|15@1+ (0.015625,0) [0|500] "m"  RDR05
 SG_ DET_RANGE_ERR_106_Rx : 152|7@1+ (0.0075,0) [0|0.9525] "m"  RDR05
 SG_ DET_RANGE_VELOCITY_106_Rx : 160|15@1+ (0.0078125,-128) [-128|127.9921875] "m/s"  RDR05
 SG_ DET_RANGE_VELOCITY_ERR_106_Rx : 176|8@1+ (0.003,0) [0|0.765] "m/s"  RDR05
 SG_ DET_AZIMUTH_106_Rx : 200|13@1+ (0.0004,-1.5708) [-1.5708|1.5708] "rad"  RDR05
 SG_ DET_AZIMUTH_ERR_106_Rx : 217|7@1+ (0.00087267,0) [0|0.11082909] "rad"  RDR05
 SG_ DET_ELEVATION_106_Rx : 184|8@1+ (0.00275,-0.34925) [-0.34925|0.34925] "rad"  RDR05
 SG_ DET_ELEVATION_ERR_106_Rx : 192|6@1+ (0.00174533,0) [0|0.10995579] "rad"  RDR05
 SG_ DET_RCS_106_Rx : 240|8@1+ (0.5,-64) [-64|63.5] "dBsm"  RDR05
 SG_ DET_BI_STATIC_FLAG_106_Rx : 216|1@1+ (1,0) [0|1] ""  RDR05
 SG_ DET_SUPER_RES_TARGET_106_Rx : 199|1@1+ (1,0) [0|1] ""  RDR05
 SG_ DET_SNR_106_Rx : 232|8@1+ (0.35156,0) [0|89.6478] "dB"  RDR05
 SG_ DET_EXISTENCE_PROB_106_Rx : 224|6@1+ (1.588,0) [0|100] "%"  RDR05
 SG_ DET_HVC_FLAG_106_Rx : 198|1@1+ (1,0) [0|1] ""  RDR05
 SG_ DET_CONFD_AZIMUTH_106_Rx : 230|2@1+ (1,0) [0|3] ""  RDR05
 SG_ DET_CONFD_ELEVATION_106_Rx : 213|2@1+ (1,0) [0|3] ""  RDR05
 SG_ DET_PROB_1STAZHYPO_106_Rx : 215|1@1+ (1,0) [0|1] ""  RDR05
 SG_ DET_IDM_106_Rx : 175|1@1+ (1,0) [0|1] ""  RDR05
 SG_ DET_MTD_106_Rx : 159|1@1+ (1,0) [0|1] ""  RDR05
 SG_ DET_BELOW_RAIN_THOLD_106_Rx : 151|1@1+ (1,0) [0|1] ""  RDR05
 SG_ DET_RANGE_107_Rx : 248|15@1+ (0.015625,0) [0|500] "m"  RDR05
 SG_ DET_RANGE_ERR_107_Rx : 264|7@1+ (0.0075,0) [0|0.9525] "m"  RDR05
 SG_ DET_RANGE_VELOCITY_107_Rx : 272|15@1+ (0.0078125,-128) [-128|127.9921875] "m/s"  RDR05
 SG_ DET_RANGE_VELOCITY_ERR_107_Rx : 288|8@1+ (0.003,0) [0|0.765] "m/s"  RDR05
 SG_ DET_AZIMUTH_107_Rx : 312|13@1+ (0.0004,-1.5708) [-1.5708|1.5708] "rad"  RDR05
 SG_ DET_AZIMUTH_ERR_107_Rx : 329|7@1+ (0.00087267,0) [0|0.11082909] "rad"  RDR05
 SG_ DET_ELEVATION_107_Rx : 296|8@1+ (0.00275,-0.34925) [-0.34925|0.34925] "rad"  RDR05
 SG_ DET_ELEVATION_ERR_107_Rx : 304|6@1+ (0.00174533,0) [0|0.10995579] "rad"  RDR05
 SG_ DET_RCS_107_Rx : 352|8@1+ (0.5,-64) [-64|63.5] "dBsm"  RDR05
 SG_ DET_BI_STATIC_FLAG_107_Rx : 328|1@1+ (1,0) [0|1] ""  RDR05
 SG_ DET_SUPER_RES_TARGET_107_Rx : 311|1@1+ (1,0) [0|1] ""  RDR05
 SG_ DET_SNR_107_Rx : 344|8@1+ (0.35156,0) [0|89.6478] "dB"  RDR05
 SG_ DET_EXISTENCE_PROB_107_Rx : 336|6@1+ (1.588,0) [0|100] "%"  RDR05
 SG_ DET_HVC_FLAG_107_Rx : 310|1@1+ (1,0) [0|1] ""  RDR05
 SG_ DET_CONFD_AZIMUTH_107_Rx : 342|2@1+ (1,0) [0|3] ""  RDR05
 SG_ DET_CONFD_ELEVATION_107_Rx : 325|2@1+ (1,0) [0|3] ""  RDR05
 SG_ DET_PROB_1STAZHYPO_107_Rx : 327|1@1+ (1,0) [0|1] ""  RDR05
 SG_ DET_IDM_107_Rx : 287|1@1+ (1,0) [0|1] ""  RDR05
 SG_ DET_MTD_107_Rx : 271|1@1+ (1,0) [0|1] ""  RDR05
 SG_ DET_BELOW_RAIN_THOLD_107_Rx : 263|1@1+ (1,0) [0|1] ""  RDR05
 SG_ DET_RANGE_108_Rx : 360|15@1+ (0.015625,0) [0|500] "m"  RDR05
 SG_ DET_RANGE_ERR_108_Rx : 376|7@1+ (0.0075,0) [0|0.9525] "m"  RDR05
 SG_ DET_RANGE_VELOCITY_108_Rx : 384|15@1+ (0.0078125,-128) [-128|127.9921875] "m/s"  RDR05
 SG_ DET_RANGE_VELOCITY_ERR_108_Rx : 400|8@1+ (0.003,0) [0|0.765] "m/s"  RDR05
 SG_ DET_AZIMUTH_108_Rx : 424|13@1+ (0.0004,-1.5708) [-1.5708|1.5708] "rad"  RDR05
 SG_ DET_AZIMUTH_ERR_108_Rx : 441|7@1+ (0.00087267,0) [0|0.11082909] "rad"  RDR05
 SG_ DET_ELEVATION_108_Rx : 408|8@1+ (0.00275,-0.34925) [-0.34925|0.34925] "rad"  RDR05
 SG_ DET_ELEVATION_ERR_108_Rx : 416|6@1+ (0.00174533,0) [0|0.10995579] "rad"  RDR05
 SG_ DET_RCS_108_Rx : 464|8@1+ (0.5,-64) [-64|63.5] "dBsm"  RDR05
 SG_ DET_BI_STATIC_FLAG_108_Rx : 440|1@1+ (1,0) [0|1] ""  RDR05
 SG_ DET_SUPER_RES_TARGET_108_Rx : 423|1@1+ (1,0) [0|1] ""  RDR05
 SG_ DET_SNR_108_Rx : 456|8@1+ (0.35156,0) [0|89.6478] "dB"  RDR05
 SG_ DET_EXISTENCE_PROB_108_Rx : 448|6@1+ (1.588,0) [0|100] "%"  RDR05
 SG_ DET_HVC_FLAG_108_Rx : 422|1@1+ (1,0) [0|1] ""  RDR05
 SG_ DET_CONFD_AZIMUTH_108_Rx : 454|2@1+ (1,0) [0|3] ""  RDR05
 SG_ DET_CONFD_ELEVATION_108_Rx : 437|2@1+ (1,0) [0|3] ""  RDR05
 SG_ DET_MH_SCAN_INDEX_4LSB_105_108_R : 476|4@1+ (1,0) [0|15] ""  RDR05
 SG_ DET_MH_CYCLE_COUNTER_105_108_Rx : 16|8@1+ (1,0) [0|255] ""  RDR05
 SG_ DET_MH_CRC16_105_108_Rx : 0|16@1+ (1,0) [0|65535] ""  RDR05
 SG_ DET_PROB_1STAZHYPO_108_Rx : 439|1@1+ (1,0) [0|1] ""  RDR05
 SG_ DET_IDM_108_Rx : 399|1@1+ (1,0) [0|1] ""  RDR05
 SG_ DET_MTD_108_Rx : 383|1@1+ (1,0) [0|1] ""  RDR05
 SG_ DET_BELOW_RAIN_THOLD_108_Rx : 375|1@1+ (1,0) [0|1] ""  RDR05

BO_ 283 RDR_FUSION_DET_109_112: 64 RDR_Fusion_Partner
 SG_ DET_RANGE_109_Rx : 24|15@1+ (0.015625,0) [0|500] "m"  RDR05
 SG_ DET_RANGE_ERR_109_Rx : 40|7@1+ (0.0075,0) [0|0.9525] "m"  RDR05
 SG_ DET_RANGE_VELOCITY_109_Rx : 48|15@1+ (0.0078125,-128) [-128|127.9921875] "m/s"  RDR05
 SG_ DET_RANGE_VELOCITY_ERR_109_Rx : 64|8@1+ (0.003,0) [0|0.765] "m/s"  RDR05
 SG_ DET_AZIMUTH_109_Rx : 88|13@1+ (0.0004,-1.5708) [-1.5708|1.5708] "rad"  RDR05
 SG_ DET_AZIMUTH_ERR_109_Rx : 105|7@1+ (0.00087267,0) [0|0.11082909] "rad"  RDR05
 SG_ DET_ELEVATION_109_Rx : 72|8@1+ (0.00275,-0.34925) [-0.34925|0.34925] "rad"  RDR05
 SG_ DET_ELEVATION_ERR_109_Rx : 80|6@1+ (0.00174533,0) [0|0.10995579] "rad"  RDR05
 SG_ DET_RCS_109_Rx : 128|8@1+ (0.5,-64) [-64|63.5] "dBsm"  RDR05
 SG_ DET_BI_STATIC_FLAG_109_Rx : 104|1@1+ (1,0) [0|1] ""  RDR05
 SG_ DET_SUPER_RES_TARGET_109_Rx : 87|1@1+ (1,0) [0|1] ""  RDR05
 SG_ DET_SNR_109_Rx : 120|8@1+ (0.35156,0) [0|89.6478] "dB"  RDR05
 SG_ DET_EXISTENCE_PROB_109_Rx : 112|6@1+ (1.588,0) [0|100] "%"  RDR05
 SG_ DET_HVC_FLAG_109_Rx : 86|1@1+ (1,0) [0|1] ""  RDR05
 SG_ DET_CONFD_AZIMUTH_109_Rx : 118|2@1+ (1,0) [0|3] ""  RDR05
 SG_ DET_CONFD_ELEVATION_109_Rx : 101|2@1+ (1,0) [0|3] ""  RDR05
 SG_ DET_PROB_1STAZHYPO_109_Rx : 103|1@1+ (1,0) [0|1] ""  RDR05
 SG_ DET_IDM_109_Rx : 63|1@1+ (1,0) [0|1] ""  RDR05
 SG_ DET_MTD_109_Rx : 47|1@1+ (1,0) [0|1] ""  RDR05
 SG_ DET_BELOW_RAIN_THOLD_109_Rx : 39|1@1+ (1,0) [0|1] ""  RDR05
 SG_ DET_RANGE_110_Rx : 136|15@1+ (0.015625,0) [0|500] "m"  RDR05
 SG_ DET_RANGE_ERR_110_Rx : 152|7@1+ (0.0075,0) [0|0.9525] "m"  RDR05
 SG_ DET_RANGE_VELOCITY_110_Rx : 160|15@1+ (0.0078125,-128) [-128|127.9921875] "m/s"  RDR05
 SG_ DET_RANGE_VELOCITY_ERR_110_Rx : 176|8@1+ (0.003,0) [0|0.765] "m/s"  RDR05
 SG_ DET_AZIMUTH_110_Rx : 200|13@1+ (0.0004,-1.5708) [-1.5708|1.5708] "rad"  RDR05
 SG_ DET_AZIMUTH_ERR_110_Rx : 217|7@1+ (0.00087267,0) [0|0.11082909] "rad"  RDR05
 SG_ DET_ELEVATION_110_Rx : 184|8@1+ (0.00275,-0.34925) [-0.34925|0.34925] "rad"  RDR05
 SG_ DET_ELEVATION_ERR_110_Rx : 192|6@1+ (0.00174533,0) [0|0.10995579] "rad"  RDR05
 SG_ DET_RCS_110_Rx : 240|8@1+ (0.5,-64) [-64|63.5] "dBsm"  RDR05
 SG_ DET_BI_STATIC_FLAG_110_Rx : 216|1@1+ (1,0) [0|1] ""  RDR05
 SG_ DET_SUPER_RES_TARGET_110_Rx : 199|1@1+ (1,0) [0|1] ""  RDR05
 SG_ DET_SNR_110_Rx : 232|8@1+ (0.35156,0) [0|89.6478] "dB"  RDR05
 SG_ DET_EXISTENCE_PROB_110_Rx : 224|6@1+ (1.588,0) [0|100] "%"  RDR05
 SG_ DET_HVC_FLAG_110_Rx : 198|1@1+ (1,0) [0|1] ""  RDR05
 SG_ DET_CONFD_AZIMUTH_110_Rx : 230|2@1+ (1,0) [0|3] ""  RDR05
 SG_ DET_CONFD_ELEVATION_110_Rx : 213|2@1+ (1,0) [0|3] ""  RDR05
 SG_ DET_PROB_1STAZHYPO_110_Rx : 215|1@1+ (1,0) [0|1] ""  RDR05
 SG_ DET_IDM_110_Rx : 175|1@1+ (1,0) [0|1] ""  RDR05
 SG_ DET_MTD_110_Rx : 159|1@1+ (1,0) [0|1] ""  RDR05
 SG_ DET_BELOW_RAIN_THOLD_110_Rx : 151|1@1+ (1,0) [0|1] ""  RDR05
 SG_ DET_RANGE_111_Rx : 248|15@1+ (0.015625,0) [0|500] "m"  RDR05
 SG_ DET_RANGE_ERR_111_Rx : 264|7@1+ (0.0075,0) [0|0.9525] "m"  RDR05
 SG_ DET_RANGE_VELOCITY_111_Rx : 272|15@1+ (0.0078125,-128) [-128|127.9921875] "m/s"  RDR05
 SG_ DET_RANGE_VELOCITY_ERR_111_Rx : 288|8@1+ (0.003,0) [0|0.765] "m/s"  RDR05
 SG_ DET_AZIMUTH_111_Rx : 312|13@1+ (0.0004,-1.5708) [-1.5708|1.5708] "rad"  RDR05
 SG_ DET_AZIMUTH_ERR_111_Rx : 329|7@1+ (0.00087267,0) [0|0.11082909] "rad"  RDR05
 SG_ DET_ELEVATION_111_Rx : 296|8@1+ (0.00275,-0.34925) [-0.34925|0.34925] "rad"  RDR05
 SG_ DET_ELEVATION_ERR_111_Rx : 304|6@1+ (0.00174533,0) [0|0.10995579] "rad"  RDR05
 SG_ DET_RCS_111_Rx : 352|8@1+ (0.5,-64) [-64|63.5] "dBsm"  RDR05
 SG_ DET_BI_STATIC_FLAG_111_Rx : 328|1@1+ (1,0) [0|1] ""  RDR05
 SG_ DET_SUPER_RES_TARGET_111_Rx : 311|1@1+ (1,0) [0|1] ""  RDR05
 SG_ DET_SNR_111_Rx : 344|8@1+ (0.35156,0) [0|89.6478] "dB"  RDR05
 SG_ DET_EXISTENCE_PROB_111_Rx : 336|6@1+ (1.588,0) [0|100] "%"  RDR05
 SG_ DET_HVC_FLAG_111_Rx : 310|1@1+ (1,0) [0|1] ""  RDR05
 SG_ DET_CONFD_AZIMUTH_111_Rx : 342|2@1+ (1,0) [0|3] ""  RDR05
 SG_ DET_CONFD_ELEVATION_111_Rx : 325|2@1+ (1,0) [0|3] ""  RDR05
 SG_ DET_PROB_1STAZHYPO_111_Rx : 327|1@1+ (1,0) [0|1] ""  RDR05
 SG_ DET_IDM_111_Rx : 287|1@1+ (1,0) [0|1] ""  RDR05
 SG_ DET_MTD_111_Rx : 271|1@1+ (1,0) [0|1] ""  RDR05
 SG_ DET_BELOW_RAIN_THOLD_111_Rx : 263|1@1+ (1,0) [0|1] ""  RDR05
 SG_ DET_RANGE_112_Rx : 360|15@1+ (0.015625,0) [0|500] "m"  RDR05
 SG_ DET_RANGE_ERR_112_Rx : 376|7@1+ (0.0075,0) [0|0.9525] "m"  RDR05
 SG_ DET_RANGE_VELOCITY_112_Rx : 384|15@1+ (0.0078125,-128) [-128|127.9921875] "m/s"  RDR05
 SG_ DET_RANGE_VELOCITY_ERR_112_Rx : 400|8@1+ (0.003,0) [0|0.765] "m/s"  RDR05
 SG_ DET_AZIMUTH_112_Rx : 424|13@1+ (0.0004,-1.5708) [-1.5708|1.5708] "rad"  RDR05
 SG_ DET_AZIMUTH_ERR_112_Rx : 441|7@1+ (0.00087267,0) [0|0.11082909] "rad"  RDR05
 SG_ DET_ELEVATION_112_Rx : 408|8@1+ (0.00275,-0.34925) [-0.34925|0.34925] "rad"  RDR05
 SG_ DET_ELEVATION_ERR_112_Rx : 416|6@1+ (0.00174533,0) [0|0.10995579] "rad"  RDR05
 SG_ DET_RCS_112_Rx : 464|8@1+ (0.5,-64) [-64|63.5] "dBsm"  RDR05
 SG_ DET_BI_STATIC_FLAG_112_Rx : 440|1@1+ (1,0) [0|1] ""  RDR05
 SG_ DET_SUPER_RES_TARGET_112_Rx : 423|1@1+ (1,0) [0|1] ""  RDR05
 SG_ DET_SNR_112_Rx : 456|8@1+ (0.35156,0) [0|89.6478] "dB"  RDR05
 SG_ DET_EXISTENCE_PROB_112_Rx : 448|6@1+ (1.588,0) [0|100] "%"  RDR05
 SG_ DET_HVC_FLAG_112_Rx : 422|1@1+ (1,0) [0|1] ""  RDR05
 SG_ DET_CONFD_AZIMUTH_112_Rx : 454|2@1+ (1,0) [0|3] ""  RDR05
 SG_ DET_CONFD_ELEVATION_112_Rx : 437|2@1+ (1,0) [0|3] ""  RDR05
 SG_ DET_MH_SCAN_INDEX_4LSB_109_112_R : 476|4@1+ (1,0) [0|15] ""  RDR05
 SG_ DET_MH_CYCLE_COUNTER_109_112_Rx : 16|8@1+ (1,0) [0|255] ""  RDR05
 SG_ DET_MH_CRC16_109_112_Rx : 0|16@1+ (1,0) [0|65535] ""  RDR05
 SG_ DET_PROB_1STAZHYPO_112_Rx : 439|1@1+ (1,0) [0|1] ""  RDR05
 SG_ DET_IDM_112_Rx : 399|1@1+ (1,0) [0|1] ""  RDR05
 SG_ DET_MTD_112_Rx : 383|1@1+ (1,0) [0|1] ""  RDR05
 SG_ DET_BELOW_RAIN_THOLD_112_Rx : 375|1@1+ (1,0) [0|1] ""  RDR05

BO_ 284 RDR_FUSION_DET_113_116: 64 RDR_Fusion_Partner
 SG_ DET_RANGE_113_Rx : 24|15@1+ (0.015625,0) [0|500] "m"  RDR05
 SG_ DET_RANGE_ERR_113_Rx : 40|7@1+ (0.0075,0) [0|0.9525] "m"  RDR05
 SG_ DET_RANGE_VELOCITY_113_Rx : 48|15@1+ (0.0078125,-128) [-128|127.9921875] "m/s"  RDR05
 SG_ DET_RANGE_VELOCITY_ERR_113_Rx : 64|8@1+ (0.003,0) [0|0.765] "m/s"  RDR05
 SG_ DET_AZIMUTH_113_Rx : 88|13@1+ (0.0004,-1.5708) [-1.5708|1.5708] "rad"  RDR05
 SG_ DET_AZIMUTH_ERR_113_Rx : 105|7@1+ (0.00087267,0) [0|0.11082909] "rad"  RDR05
 SG_ DET_ELEVATION_113_Rx : 72|8@1+ (0.00275,-0.34925) [-0.34925|0.34925] "rad"  RDR05
 SG_ DET_ELEVATION_ERR_113_Rx : 80|6@1+ (0.00174533,0) [0|0.10995579] "rad"  RDR05
 SG_ DET_RCS_113_Rx : 128|8@1+ (0.5,-64) [-64|63.5] "dBsm"  RDR05
 SG_ DET_BI_STATIC_FLAG_113_Rx : 104|1@1+ (1,0) [0|1] ""  RDR05
 SG_ DET_SUPER_RES_TARGET_113_Rx : 87|1@1+ (1,0) [0|1] ""  RDR05
 SG_ DET_SNR_113_Rx : 120|8@1+ (0.35156,0) [0|89.6478] "dB"  RDR05
 SG_ DET_EXISTENCE_PROB_113_Rx : 112|6@1+ (1.588,0) [0|100] "%"  RDR05
 SG_ DET_HVC_FLAG_113_Rx : 86|1@1+ (1,0) [0|1] ""  RDR05
 SG_ DET_CONFD_AZIMUTH_113_Rx : 118|2@1+ (1,0) [0|3] ""  RDR05
 SG_ DET_CONFD_ELEVATION_113_Rx : 101|2@1+ (1,0) [0|3] ""  RDR05
 SG_ DET_PROB_1STAZHYPO_113_Rx : 103|1@1+ (1,0) [0|1] ""  RDR05
 SG_ DET_IDM_113_Rx : 63|1@1+ (1,0) [0|1] ""  RDR05
 SG_ DET_MTD_113_Rx : 47|1@1+ (1,0) [0|1] ""  RDR05
 SG_ DET_BELOW_RAIN_THOLD_113_Rx : 39|1@1+ (1,0) [0|1] ""  RDR05
 SG_ DET_RANGE_114_Rx : 136|15@1+ (0.015625,0) [0|500] "m"  RDR05
 SG_ DET_RANGE_ERR_114_Rx : 152|7@1+ (0.0075,0) [0|0.9525] "m"  RDR05
 SG_ DET_RANGE_VELOCITY_114_Rx : 160|15@1+ (0.0078125,-128) [-128|127.9921875] "m/s"  RDR05
 SG_ DET_RANGE_VELOCITY_ERR_114_Rx : 176|8@1+ (0.003,0) [0|0.765] "m/s"  RDR05
 SG_ DET_AZIMUTH_114_Rx : 200|13@1+ (0.0004,-1.5708) [-1.5708|1.5708] "rad"  RDR05
 SG_ DET_AZIMUTH_ERR_114_Rx : 217|7@1+ (0.00087267,0) [0|0.11082909] "rad"  RDR05
 SG_ DET_ELEVATION_114_Rx : 184|8@1+ (0.00275,-0.34925) [-0.34925|0.34925] "rad"  RDR05
 SG_ DET_ELEVATION_ERR_114_Rx : 192|6@1+ (0.00174533,0) [0|0.10995579] "rad"  RDR05
 SG_ DET_RCS_114_Rx : 240|8@1+ (0.5,-64) [-64|63.5] "dBsm"  RDR05
 SG_ DET_BI_STATIC_FLAG_114_Rx : 216|1@1+ (1,0) [0|1] ""  RDR05
 SG_ DET_SUPER_RES_TARGET_114_Rx : 199|1@1+ (1,0) [0|1] ""  RDR05
 SG_ DET_SNR_114_Rx : 232|8@1+ (0.35156,0) [0|89.6478] "dB"  RDR05
 SG_ DET_EXISTENCE_PROB_114_Rx : 224|6@1+ (1.588,0) [0|100] "%"  RDR05
 SG_ DET_HVC_FLAG_114_Rx : 198|1@1+ (1,0) [0|1] ""  RDR05
 SG_ DET_CONFD_AZIMUTH_114_Rx : 230|2@1+ (1,0) [0|3] ""  RDR05
 SG_ DET_CONFD_ELEVATION_114_Rx : 213|2@1+ (1,0) [0|3] ""  RDR05
 SG_ DET_PROB_1STAZHYPO_114_Rx : 215|1@1+ (1,0) [0|1] ""  RDR05
 SG_ DET_IDM_114_Rx : 175|1@1+ (1,0) [0|1] ""  RDR05
 SG_ DET_MTD_114_Rx : 159|1@1+ (1,0) [0|1] ""  RDR05
 SG_ DET_BELOW_RAIN_THOLD_114_Rx : 151|1@1+ (1,0) [0|1] ""  RDR05
 SG_ DET_RANGE_115_Rx : 248|15@1+ (0.015625,0) [0|500] "m"  RDR05
 SG_ DET_RANGE_ERR_115_Rx : 264|7@1+ (0.0075,0) [0|0.9525] "m"  RDR05
 SG_ DET_RANGE_VELOCITY_115_Rx : 272|15@1+ (0.0078125,-128) [-128|127.9921875] "m/s"  RDR05
 SG_ DET_RANGE_VELOCITY_ERR_115_Rx : 288|8@1+ (0.003,0) [0|0.765] "m/s"  RDR05
 SG_ DET_AZIMUTH_115_Rx : 312|13@1+ (0.0004,-1.5708) [-1.5708|1.5708] "rad"  RDR05
 SG_ DET_AZIMUTH_ERR_115_Rx : 329|7@1+ (0.00087267,0) [0|0.11082909] "rad"  RDR05
 SG_ DET_ELEVATION_115_Rx : 296|8@1+ (0.00275,-0.34925) [-0.34925|0.34925] "rad"  RDR05
 SG_ DET_ELEVATION_ERR_115_Rx : 304|6@1+ (0.00174533,0) [0|0.10995579] "rad"  RDR05
 SG_ DET_RCS_115_Rx : 352|8@1+ (0.5,-64) [-64|63.5] "dBsm"  RDR05
 SG_ DET_BI_STATIC_FLAG_115_Rx : 328|1@1+ (1,0) [0|1] ""  RDR05
 SG_ DET_SUPER_RES_TARGET_115_Rx : 311|1@1+ (1,0) [0|1] ""  RDR05
 SG_ DET_SNR_115_Rx : 344|8@1+ (0.35156,0) [0|89.6478] "dB"  RDR05
 SG_ DET_EXISTENCE_PROB_115_Rx : 336|6@1+ (1.588,0) [0|100] "%"  RDR05
 SG_ DET_HVC_FLAG_115_Rx : 310|1@1+ (1,0) [0|1] ""  RDR05
 SG_ DET_CONFD_AZIMUTH_115_Rx : 342|2@1+ (1,0) [0|3] ""  RDR05
 SG_ DET_CONFD_ELEVATION_115_Rx : 325|2@1+ (1,0) [0|3] ""  RDR05
 SG_ DET_PROB_1STAZHYPO_115_Rx : 327|1@1+ (1,0) [0|1] ""  RDR05
 SG_ DET_IDM_115_Rx : 287|1@1+ (1,0) [0|1] ""  RDR05
 SG_ DET_MTD_115_Rx : 271|1@1+ (1,0) [0|1] ""  RDR05
 SG_ DET_BELOW_RAIN_THOLD_115_Rx : 263|1@1+ (1,0) [0|1] ""  RDR05
 SG_ DET_RANGE_116_Rx : 360|15@1+ (0.015625,0) [0|500] "m"  RDR05
 SG_ DET_RANGE_ERR_116_Rx : 376|7@1+ (0.0075,0) [0|0.9525] "m"  RDR05
 SG_ DET_RANGE_VELOCITY_116_Rx : 384|15@1+ (0.0078125,-128) [-128|127.9921875] "m/s"  RDR05
 SG_ DET_RANGE_VELOCITY_ERR_116_Rx : 400|8@1+ (0.003,0) [0|0.765] "m/s"  RDR05
 SG_ DET_AZIMUTH_116_Rx : 424|13@1+ (0.0004,-1.5708) [-1.5708|1.5708] "rad"  RDR05
 SG_ DET_AZIMUTH_ERR_116_Rx : 441|7@1+ (0.00087267,0) [0|0.11082909] "rad"  RDR05
 SG_ DET_ELEVATION_116_Rx : 408|8@1+ (0.00275,-0.34925) [-0.34925|0.34925] "rad"  RDR05
 SG_ DET_ELEVATION_ERR_116_Rx : 416|6@1+ (0.00174533,0) [0|0.10995579] "rad"  RDR05
 SG_ DET_RCS_116_Rx : 464|8@1+ (0.5,-64) [-64|63.5] "dBsm"  RDR05
 SG_ DET_BI_STATIC_FLAG_116_Rx : 440|1@1+ (1,0) [0|1] ""  RDR05
 SG_ DET_SUPER_RES_TARGET_116_Rx : 423|1@1+ (1,0) [0|1] ""  RDR05
 SG_ DET_SNR_116_Rx : 456|8@1+ (0.35156,0) [0|89.6478] "dB"  RDR05
 SG_ DET_EXISTENCE_PROB_116_Rx : 448|6@1+ (1.588,0) [0|100] "%"  RDR05
 SG_ DET_HVC_FLAG_116_Rx : 422|1@1+ (1,0) [0|1] ""  RDR05
 SG_ DET_CONFD_AZIMUTH_116_Rx : 454|2@1+ (1,0) [0|3] ""  RDR05
 SG_ DET_CONFD_ELEVATION_116_Rx : 437|2@1+ (1,0) [0|3] ""  RDR05
 SG_ DET_MH_SCAN_INDEX_4LSB_113_116_R : 476|4@1+ (1,0) [0|15] ""  RDR05
 SG_ DET_MH_CYCLE_COUNTER_113_116_Rx : 16|8@1+ (1,0) [0|255] ""  RDR05
 SG_ DET_MH_CRC16_113_116_Rx : 0|16@1+ (1,0) [0|65535] ""  RDR05
 SG_ DET_PROB_1STAZHYPO_116_Rx : 439|1@1+ (1,0) [0|1] ""  RDR05
 SG_ DET_IDM_116_Rx : 399|1@1+ (1,0) [0|1] ""  RDR05
 SG_ DET_MTD_116_Rx : 383|1@1+ (1,0) [0|1] ""  RDR05
 SG_ DET_BELOW_RAIN_THOLD_116_Rx : 375|1@1+ (1,0) [0|1] ""  RDR05

BO_ 285 RDR_FUSION_DET_117_120: 64 RDR_Fusion_Partner
 SG_ DET_RANGE_117_Rx : 24|15@1+ (0.015625,0) [0|500] "m"  RDR05
 SG_ DET_RANGE_ERR_117_Rx : 40|7@1+ (0.0075,0) [0|0.9525] "m"  RDR05
 SG_ DET_RANGE_VELOCITY_117_Rx : 48|15@1+ (0.0078125,-128) [-128|127.9921875] "m/s"  RDR05
 SG_ DET_RANGE_VELOCITY_ERR_117_Rx : 64|8@1+ (0.003,0) [0|0.765] "m/s"  RDR05
 SG_ DET_AZIMUTH_117_Rx : 88|13@1+ (0.0004,-1.5708) [-1.5708|1.5708] "rad"  RDR05
 SG_ DET_AZIMUTH_ERR_117_Rx : 105|7@1+ (0.00087267,0) [0|0.11082909] "rad"  RDR05
 SG_ DET_ELEVATION_117_Rx : 72|8@1+ (0.00275,-0.34925) [-0.34925|0.34925] "rad"  RDR05
 SG_ DET_ELEVATION_ERR_117_Rx : 80|6@1+ (0.00174533,0) [0|0.10995579] "rad"  RDR05
 SG_ DET_RCS_117_Rx : 128|8@1+ (0.5,-64) [-64|63.5] "dBsm"  RDR05
 SG_ DET_BI_STATIC_FLAG_117_Rx : 104|1@1+ (1,0) [0|1] ""  RDR05
 SG_ DET_SUPER_RES_TARGET_117_Rx : 87|1@1+ (1,0) [0|1] ""  RDR05
 SG_ DET_SNR_117_Rx : 120|8@1+ (0.35156,0) [0|89.6478] "dB"  RDR05
 SG_ DET_EXISTENCE_PROB_117_Rx : 112|6@1+ (1.588,0) [0|100] "%"  RDR05
 SG_ DET_HVC_FLAG_117_Rx : 86|1@1+ (1,0) [0|1] ""  RDR05
 SG_ DET_CONFD_AZIMUTH_117_Rx : 118|2@1+ (1,0) [0|3] ""  RDR05
 SG_ DET_CONFD_ELEVATION_117_Rx : 101|2@1+ (1,0) [0|3] ""  RDR05
 SG_ DET_PROB_1STAZHYPO_117_Rx : 103|1@1+ (1,0) [0|1] ""  RDR05
 SG_ DET_IDM_117_Rx : 63|1@1+ (1,0) [0|1] ""  RDR05
 SG_ DET_MTD_117_Rx : 47|1@1+ (1,0) [0|1] ""  RDR05
 SG_ DET_BELOW_RAIN_THOLD_117_Rx : 39|1@1+ (1,0) [0|1] ""  RDR05
 SG_ DET_RANGE_118_Rx : 136|15@1+ (0.015625,0) [0|500] "m"  RDR05
 SG_ DET_RANGE_ERR_118_Rx : 152|7@1+ (0.0075,0) [0|0.9525] "m"  RDR05
 SG_ DET_RANGE_VELOCITY_118_Rx : 160|15@1+ (0.0078125,-128) [-128|127.9921875] "m/s"  RDR05
 SG_ DET_RANGE_VELOCITY_ERR_118_Rx : 176|8@1+ (0.003,0) [0|0.765] "m/s"  RDR05
 SG_ DET_AZIMUTH_118_Rx : 200|13@1+ (0.0004,-1.5708) [-1.5708|1.5708] "rad"  RDR05
 SG_ DET_AZIMUTH_ERR_118_Rx : 217|7@1+ (0.00087267,0) [0|0.11082909] "rad"  RDR05
 SG_ DET_ELEVATION_118_Rx : 184|8@1+ (0.00275,-0.34925) [-0.34925|0.34925] "rad"  RDR05
 SG_ DET_ELEVATION_ERR_118_Rx : 192|6@1+ (0.00174533,0) [0|0.10995579] "rad"  RDR05
 SG_ DET_RCS_118_Rx : 240|8@1+ (0.5,-64) [-64|63.5] "dBsm"  RDR05
 SG_ DET_BI_STATIC_FLAG_118_Rx : 216|1@1+ (1,0) [0|1] ""  RDR05
 SG_ DET_SUPER_RES_TARGET_118_Rx : 199|1@1+ (1,0) [0|1] ""  RDR05
 SG_ DET_SNR_118_Rx : 232|8@1+ (0.35156,0) [0|89.6478] "dB"  RDR05
 SG_ DET_EXISTENCE_PROB_118_Rx : 224|6@1+ (1.588,0) [0|100] "%"  RDR05
 SG_ DET_HVC_FLAG_118_Rx : 198|1@1+ (1,0) [0|1] ""  RDR05
 SG_ DET_CONFD_AZIMUTH_118_Rx : 230|2@1+ (1,0) [0|3] ""  RDR05
 SG_ DET_CONFD_ELEVATION_118_Rx : 213|2@1+ (1,0) [0|3] ""  RDR05
 SG_ DET_PROB_1STAZHYPO_118_Rx : 215|1@1+ (1,0) [0|1] ""  RDR05
 SG_ DET_IDM_118_Rx : 175|1@1+ (1,0) [0|1] ""  RDR05
 SG_ DET_MTD_118_Rx : 159|1@1+ (1,0) [0|1] ""  RDR05
 SG_ DET_BELOW_RAIN_THOLD_118_Rx : 151|1@1+ (1,0) [0|1] ""  RDR05
 SG_ DET_RANGE_119_Rx : 248|15@1+ (0.015625,0) [0|500] "m"  RDR05
 SG_ DET_RANGE_ERR_119_Rx : 264|7@1+ (0.0075,0) [0|0.9525] "m"  RDR05
 SG_ DET_RANGE_VELOCITY_119_Rx : 272|15@1+ (0.0078125,-128) [-128|127.9921875] "m/s"  RDR05
 SG_ DET_RANGE_VELOCITY_ERR_119_Rx : 288|8@1+ (0.003,0) [0|0.765] "m/s"  RDR05
 SG_ DET_AZIMUTH_119_Rx : 312|13@1+ (0.0004,-1.5708) [-1.5708|1.5708] "rad"  RDR05
 SG_ DET_AZIMUTH_ERR_119_Rx : 329|7@1+ (0.00087267,0) [0|0.11082909] "rad"  RDR05
 SG_ DET_ELEVATION_119_Rx : 296|8@1+ (0.00275,-0.34925) [-0.34925|0.34925] "rad"  RDR05
 SG_ DET_ELEVATION_ERR_119_Rx : 304|6@1+ (0.00174533,0) [0|0.10995579] "rad"  RDR05
 SG_ DET_RCS_119_Rx : 352|8@1+ (0.5,-64) [-64|63.5] "dBsm"  RDR05
 SG_ DET_BI_STATIC_FLAG_119_Rx : 328|1@1+ (1,0) [0|1] ""  RDR05
 SG_ DET_SUPER_RES_TARGET_119_Rx : 311|1@1+ (1,0) [0|1] ""  RDR05
 SG_ DET_SNR_119_Rx : 344|8@1+ (0.35156,0) [0|89.6478] "dB"  RDR05
 SG_ DET_EXISTENCE_PROB_119_Rx : 336|6@1+ (1.588,0) [0|100] "%"  RDR05
 SG_ DET_HVC_FLAG_119_Rx : 310|1@1+ (1,0) [0|1] ""  RDR05
 SG_ DET_CONFD_AZIMUTH_119_Rx : 342|2@1+ (1,0) [0|3] ""  RDR05
 SG_ DET_CONFD_ELEVATION_119_Rx : 325|2@1+ (1,0) [0|3] ""  RDR05
 SG_ DET_PROB_1STAZHYPO_119_Rx : 327|1@1+ (1,0) [0|1] ""  RDR05
 SG_ DET_IDM_119_Rx : 287|1@1+ (1,0) [0|1] ""  RDR05
 SG_ DET_MTD_119_Rx : 271|1@1+ (1,0) [0|1] ""  RDR05
 SG_ DET_BELOW_RAIN_THOLD_119_Rx : 263|1@1+ (1,0) [0|1] ""  RDR05
 SG_ DET_RANGE_120_Rx : 360|15@1+ (0.015625,0) [0|500] "m"  RDR05
 SG_ DET_RANGE_ERR_120_Rx : 376|7@1+ (0.0075,0) [0|0.9525] "m"  RDR05
 SG_ DET_RANGE_VELOCITY_120_Rx : 384|15@1+ (0.0078125,-128) [-128|127.9921875] "m/s"  RDR05
 SG_ DET_RANGE_VELOCITY_ERR_120_Rx : 400|8@1+ (0.003,0) [0|0.765] "m/s"  RDR05
 SG_ DET_AZIMUTH_120_Rx : 424|13@1+ (0.0004,-1.5708) [-1.5708|1.5708] "rad"  RDR05
 SG_ DET_AZIMUTH_ERR_120_Rx : 441|7@1+ (0.00087267,0) [0|0.11082909] "rad"  RDR05
 SG_ DET_ELEVATION_120_Rx : 408|8@1+ (0.00275,-0.34925) [-0.34925|0.34925] "rad"  RDR05
 SG_ DET_ELEVATION_ERR_120_Rx : 416|6@1+ (0.00174533,0) [0|0.10995579] "rad"  RDR05
 SG_ DET_RCS_120_Rx : 464|8@1+ (0.5,-64) [-64|63.5] "dBsm"  RDR05
 SG_ DET_BI_STATIC_FLAG_120_Rx : 440|1@1+ (1,0) [0|1] ""  RDR05
 SG_ DET_SUPER_RES_TARGET_120_Rx : 423|1@1+ (1,0) [0|1] ""  RDR05
 SG_ DET_SNR_120_Rx : 456|8@1+ (0.35156,0) [0|89.6478] "dB"  RDR05
 SG_ DET_EXISTENCE_PROB_120_Rx : 448|6@1+ (1.588,0) [0|100] "%"  RDR05
 SG_ DET_HVC_FLAG_120_Rx : 422|1@1+ (1,0) [0|1] ""  RDR05
 SG_ DET_CONFD_AZIMUTH_120_Rx : 454|2@1+ (1,0) [0|3] ""  RDR05
 SG_ DET_CONFD_ELEVATION_120_Rx : 437|2@1+ (1,0) [0|3] ""  RDR05
 SG_ DET_MH_SCAN_INDEX_4LSB_117_120_R : 476|4@1+ (1,0) [0|15] ""  RDR05
 SG_ DET_MH_CYCLE_COUNTER_117_120_Rx : 16|8@1+ (1,0) [0|255] ""  RDR05
 SG_ DET_MH_CRC16_117_120_Rx : 0|16@1+ (1,0) [0|65535] ""  RDR05
 SG_ DET_PROB_1STAZHYPO_120_Rx : 439|1@1+ (1,0) [0|1] ""  RDR05
 SG_ DET_IDM_120_Rx : 399|1@1+ (1,0) [0|1] ""  RDR05
 SG_ DET_MTD_120_Rx : 383|1@1+ (1,0) [0|1] ""  RDR05
 SG_ DET_BELOW_RAIN_THOLD_120_Rx : 375|1@1+ (1,0) [0|1] ""  RDR05

BO_ 286 RDR_FUSION_DET_121_124: 64 RDR_Fusion_Partner
 SG_ DET_RANGE_121_Rx : 24|15@1+ (0.015625,0) [0|500] "m"  RDR05
 SG_ DET_RANGE_ERR_121_Rx : 40|7@1+ (0.0075,0) [0|0.9525] "m"  RDR05
 SG_ DET_RANGE_VELOCITY_121_Rx : 48|15@1+ (0.0078125,-128) [-128|127.9921875] "m/s"  RDR05
 SG_ DET_RANGE_VELOCITY_ERR_121_Rx : 64|8@1+ (0.003,0) [0|0.765] "m/s"  RDR05
 SG_ DET_AZIMUTH_121_Rx : 88|13@1+ (0.0004,-1.5708) [-1.5708|1.5708] "rad"  RDR05
 SG_ DET_AZIMUTH_ERR_121_Rx : 105|7@1+ (0.00087267,0) [0|0.11082909] "rad"  RDR05
 SG_ DET_ELEVATION_121_Rx : 72|8@1+ (0.00275,-0.34925) [-0.34925|0.34925] "rad"  RDR05
 SG_ DET_ELEVATION_ERR_121_Rx : 80|6@1+ (0.00174533,0) [0|0.10995579] "rad"  RDR05
 SG_ DET_RCS_121_Rx : 128|8@1+ (0.5,-64) [-64|63.5] "dBsm"  RDR05
 SG_ DET_BI_STATIC_FLAG_121_Rx : 104|1@1+ (1,0) [0|1] ""  RDR05
 SG_ DET_SUPER_RES_TARGET_121_Rx : 87|1@1+ (1,0) [0|1] ""  RDR05
 SG_ DET_SNR_121_Rx : 120|8@1+ (0.35156,0) [0|89.6478] "dB"  RDR05
 SG_ DET_EXISTENCE_PROB_121_Rx : 112|6@1+ (1.588,0) [0|100] "%"  RDR05
 SG_ DET_HVC_FLAG_121_Rx : 86|1@1+ (1,0) [0|1] ""  RDR05
 SG_ DET_CONFD_AZIMUTH_121_Rx : 118|2@1+ (1,0) [0|3] ""  RDR05
 SG_ DET_CONFD_ELEVATION_121_Rx : 101|2@1+ (1,0) [0|3] ""  RDR05
 SG_ DET_PROB_1STAZHYPO_121_Rx : 103|1@1+ (1,0) [0|1] ""  RDR05
 SG_ DET_IDM_121_Rx : 63|1@1+ (1,0) [0|1] ""  RDR05
 SG_ DET_MTD_121_Rx : 47|1@1+ (1,0) [0|1] ""  RDR05
 SG_ DET_BELOW_RAIN_THOLD_121_Rx : 39|1@1+ (1,0) [0|1] ""  RDR05
 SG_ DET_RANGE_122_Rx : 136|15@1+ (0.015625,0) [0|500] "m"  RDR05
 SG_ DET_RANGE_ERR_122_Rx : 152|7@1+ (0.0075,0) [0|0.9525] "m"  RDR05
 SG_ DET_RANGE_VELOCITY_122_Rx : 160|15@1+ (0.0078125,-128) [-128|127.9921875] "m/s"  RDR05
 SG_ DET_RANGE_VELOCITY_ERR_122_Rx : 176|8@1+ (0.003,0) [0|0.765] "m/s"  RDR05
 SG_ DET_AZIMUTH_122_Rx : 200|13@1+ (0.0004,-1.5708) [-1.5708|1.5708] "rad"  RDR05
 SG_ DET_AZIMUTH_ERR_122_Rx : 217|7@1+ (0.00087267,0) [0|0.11082909] "rad"  RDR05
 SG_ DET_ELEVATION_122_Rx : 184|8@1+ (0.00275,-0.34925) [-0.34925|0.34925] "rad"  RDR05
 SG_ DET_ELEVATION_ERR_122_Rx : 192|6@1+ (0.00174533,0) [0|0.10995579] "rad"  RDR05
 SG_ DET_RCS_122_Rx : 240|8@1+ (0.5,-64) [-64|63.5] "dBsm"  RDR05
 SG_ DET_BI_STATIC_FLAG_122_Rx : 216|1@1+ (1,0) [0|1] ""  RDR05
 SG_ DET_SUPER_RES_TARGET_122_Rx : 199|1@1+ (1,0) [0|1] ""  RDR05
 SG_ DET_SNR_122_Rx : 232|8@1+ (0.35156,0) [0|89.6478] "dB"  RDR05
 SG_ DET_EXISTENCE_PROB_122_Rx : 224|6@1+ (1.588,0) [0|100] "%"  RDR05
 SG_ DET_HVC_FLAG_122_Rx : 198|1@1+ (1,0) [0|1] ""  RDR05
 SG_ DET_CONFD_AZIMUTH_122_Rx : 230|2@1+ (1,0) [0|3] ""  RDR05
 SG_ DET_CONFD_ELEVATION_122_Rx : 213|2@1+ (1,0) [0|3] ""  RDR05
 SG_ DET_PROB_1STAZHYPO_122_Rx : 215|1@1+ (1,0) [0|1] ""  RDR05
 SG_ DET_IDM_122_Rx : 175|1@1+ (1,0) [0|1] ""  RDR05
 SG_ DET_MTD_122_Rx : 159|1@1+ (1,0) [0|1] ""  RDR05
 SG_ DET_BELOW_RAIN_THOLD_122_Rx : 151|1@1+ (1,0) [0|1] ""  RDR05
 SG_ DET_RANGE_123_Rx : 248|15@1+ (0.015625,0) [0|500] "m"  RDR05
 SG_ DET_RANGE_ERR_123_Rx : 264|7@1+ (0.0075,0) [0|0.9525] "m"  RDR05
 SG_ DET_RANGE_VELOCITY_123_Rx : 272|15@1+ (0.0078125,-128) [-128|127.9921875] "m/s"  RDR05
 SG_ DET_RANGE_VELOCITY_ERR_123_Rx : 288|8@1+ (0.003,0) [0|0.765] "m/s"  RDR05
 SG_ DET_AZIMUTH_123_Rx : 312|13@1+ (0.0004,-1.5708) [-1.5708|1.5708] "rad"  RDR05
 SG_ DET_AZIMUTH_ERR_123_Rx : 329|7@1+ (0.00087267,0) [0|0.11082909] "rad"  RDR05
 SG_ DET_ELEVATION_123_Rx : 296|8@1+ (0.00275,-0.34925) [-0.34925|0.34925] "rad"  RDR05
 SG_ DET_ELEVATION_ERR_123_Rx : 304|6@1+ (0.00174533,0) [0|0.10995579] "rad"  RDR05
 SG_ DET_RCS_123_Rx : 352|8@1+ (0.5,-64) [-64|63.5] "dBsm"  RDR05
 SG_ DET_BI_STATIC_FLAG_123_Rx : 328|1@1+ (1,0) [0|1] ""  RDR05
 SG_ DET_SUPER_RES_TARGET_123_Rx : 311|1@1+ (1,0) [0|1] ""  RDR05
 SG_ DET_SNR_123_Rx : 344|8@1+ (0.35156,0) [0|89.6478] "dB"  RDR05
 SG_ DET_EXISTENCE_PROB_123_Rx : 336|6@1+ (1.588,0) [0|100] "%"  RDR05
 SG_ DET_HVC_FLAG_123_Rx : 310|1@1+ (1,0) [0|1] ""  RDR05
 SG_ DET_CONFD_AZIMUTH_123_Rx : 342|2@1+ (1,0) [0|3] ""  RDR05
 SG_ DET_CONFD_ELEVATION_123_Rx : 325|2@1+ (1,0) [0|3] ""  RDR05
 SG_ DET_PROB_1STAZHYPO_123_Rx : 327|1@1+ (1,0) [0|1] ""  RDR05
 SG_ DET_IDM_123_Rx : 287|1@1+ (1,0) [0|1] ""  RDR05
 SG_ DET_MTD_123_Rx : 271|1@1+ (1,0) [0|1] ""  RDR05
 SG_ DET_BELOW_RAIN_THOLD_123_Rx : 263|1@1+ (1,0) [0|1] ""  RDR05
 SG_ DET_RANGE_124_Rx : 360|15@1+ (0.015625,0) [0|500] "m"  RDR05
 SG_ DET_RANGE_ERR_124_Rx : 376|7@1+ (0.0075,0) [0|0.9525] "m"  RDR05
 SG_ DET_RANGE_VELOCITY_124_Rx : 384|15@1+ (0.0078125,-128) [-128|127.9921875] "m/s"  RDR05
 SG_ DET_RANGE_VELOCITY_ERR_124_Rx : 400|8@1+ (0.003,0) [0|0.765] "m/s"  RDR05
 SG_ DET_AZIMUTH_124_Rx : 424|13@1+ (0.0004,-1.5708) [-1.5708|1.5708] "rad"  RDR05
 SG_ DET_AZIMUTH_ERR_124_Rx : 441|7@1+ (0.00087267,0) [0|0.11082909] "rad"  RDR05
 SG_ DET_ELEVATION_124_Rx : 408|8@1+ (0.00275,-0.34925) [-0.34925|0.34925] "rad"  RDR05
 SG_ DET_ELEVATION_ERR_124_Rx : 416|6@1+ (0.00174533,0) [0|0.10995579] "rad"  RDR05
 SG_ DET_RCS_124_Rx : 464|8@1+ (0.5,-64) [-64|63.5] "dBsm"  RDR05
 SG_ DET_BI_STATIC_FLAG_124_Rx : 440|1@1+ (1,0) [0|1] ""  RDR05
 SG_ DET_SUPER_RES_TARGET_124_Rx : 423|1@1+ (1,0) [0|1] ""  RDR05
 SG_ DET_SNR_124_Rx : 456|8@1+ (0.35156,0) [0|89.6478] "dB"  RDR05
 SG_ DET_EXISTENCE_PROB_124_Rx : 448|6@1+ (1.588,0) [0|100] "%"  RDR05
 SG_ DET_HVC_FLAG_124_Rx : 422|1@1+ (1,0) [0|1] ""  RDR05
 SG_ DET_CONFD_AZIMUTH_124_Rx : 454|2@1+ (1,0) [0|3] ""  RDR05
 SG_ DET_CONFD_ELEVATION_124_Rx : 437|2@1+ (1,0) [0|3] ""  RDR05
 SG_ DET_MH_SCAN_INDEX_4LSB_121_124_R : 476|4@1+ (1,0) [0|15] ""  RDR05
 SG_ DET_MH_CYCLE_COUNTER_121_124_Rx : 16|8@1+ (1,0) [0|255] ""  RDR05
 SG_ DET_MH_CRC16_121_124_Rx : 0|16@1+ (1,0) [0|65535] ""  RDR05
 SG_ DET_PROB_1STAZHYPO_124_Rx : 439|1@1+ (1,0) [0|1] ""  RDR05
 SG_ DET_IDM_124_Rx : 399|1@1+ (1,0) [0|1] ""  RDR05
 SG_ DET_MTD_124_Rx : 383|1@1+ (1,0) [0|1] ""  RDR05
 SG_ DET_BELOW_RAIN_THOLD_124_Rx : 375|1@1+ (1,0) [0|1] ""  RDR05

BO_ 287 RDR_FUSION_DET_125_128: 64 RDR_Fusion_Partner
 SG_ DET_RANGE_125_Rx : 24|15@1+ (0.015625,0) [0|500] "m"  RDR05
 SG_ DET_RANGE_ERR_125_Rx : 40|7@1+ (0.0075,0) [0|0.9525] "m"  RDR05
 SG_ DET_RANGE_VELOCITY_125_Rx : 48|15@1+ (0.0078125,-128) [-128|127.9921875] "m/s"  RDR05
 SG_ DET_RANGE_VELOCITY_ERR_125_Rx : 64|8@1+ (0.003,0) [0|0.765] "m/s"  RDR05
 SG_ DET_AZIMUTH_125_Rx : 88|13@1+ (0.0004,-1.5708) [-1.5708|1.5708] "rad"  RDR05
 SG_ DET_AZIMUTH_ERR_125_Rx : 105|7@1+ (0.00087267,0) [0|0.11082909] "rad"  RDR05
 SG_ DET_ELEVATION_125_Rx : 72|8@1+ (0.00275,-0.34925) [-0.34925|0.34925] "rad"  RDR05
 SG_ DET_ELEVATION_ERR_125_Rx : 80|6@1+ (0.00174533,0) [0|0.10995579] "rad"  RDR05
 SG_ DET_RCS_125_Rx : 128|8@1+ (0.5,-64) [-64|63.5] "dBsm"  RDR05
 SG_ DET_BI_STATIC_FLAG_125_Rx : 104|1@1+ (1,0) [0|1] ""  RDR05
 SG_ DET_SUPER_RES_TARGET_125_Rx : 87|1@1+ (1,0) [0|1] ""  RDR05
 SG_ DET_SNR_125_Rx : 120|8@1+ (0.35156,0) [0|89.6478] "dB"  RDR05
 SG_ DET_EXISTENCE_PROB_125_Rx : 112|6@1+ (1.588,0) [0|100] "%"  RDR05
 SG_ DET_HVC_FLAG_125_Rx : 86|1@1+ (1,0) [0|1] ""  RDR05
 SG_ DET_CONFD_AZIMUTH_125_Rx : 118|2@1+ (1,0) [0|3] ""  RDR05
 SG_ DET_CONFD_ELEVATION_125_Rx : 101|2@1+ (1,0) [0|3] ""  RDR05
 SG_ DET_PROB_1STAZHYPO_125_Rx : 103|1@1+ (1,0) [0|1] ""  RDR05
 SG_ DET_IDM_125_Rx : 63|1@1+ (1,0) [0|1] ""  RDR05
 SG_ DET_MTD_125_Rx : 47|1@1+ (1,0) [0|1] ""  RDR05
 SG_ DET_BELOW_RAIN_THOLD_125_Rx : 39|1@1+ (1,0) [0|1] ""  RDR05
 SG_ DET_RANGE_126_Rx : 136|15@1+ (0.015625,0) [0|500] "m"  RDR05
 SG_ DET_RANGE_ERR_126_Rx : 152|7@1+ (0.0075,0) [0|0.9525] "m"  RDR05
 SG_ DET_RANGE_VELOCITY_126_Rx : 160|15@1+ (0.0078125,-128) [-128|127.9921875] "m/s"  RDR05
 SG_ DET_RANGE_VELOCITY_ERR_126_Rx : 176|8@1+ (0.003,0) [0|0.765] "m/s"  RDR05
 SG_ DET_AZIMUTH_126_Rx : 200|13@1+ (0.0004,-1.5708) [-1.5708|1.5708] "rad"  RDR05
 SG_ DET_AZIMUTH_ERR_126_Rx : 217|7@1+ (0.00087267,0) [0|0.11082909] "rad"  RDR05
 SG_ DET_ELEVATION_126_Rx : 184|8@1+ (0.00275,-0.34925) [-0.34925|0.34925] "rad"  RDR05
 SG_ DET_ELEVATION_ERR_126_Rx : 192|6@1+ (0.00174533,0) [0|0.10995579] "rad"  RDR05
 SG_ DET_RCS_126_Rx : 240|8@1+ (0.5,-64) [-64|63.5] "dBsm"  RDR05
 SG_ DET_BI_STATIC_FLAG_126_Rx : 216|1@1+ (1,0) [0|1] ""  RDR05
 SG_ DET_SUPER_RES_TARGET_126_Rx : 199|1@1+ (1,0) [0|1] ""  RDR05
 SG_ DET_SNR_126_Rx : 232|8@1+ (0.35156,0) [0|89.6478] "dB"  RDR05
 SG_ DET_EXISTENCE_PROB_126_Rx : 224|6@1+ (1.588,0) [0|100] "%"  RDR05
 SG_ DET_HVC_FLAG_126_Rx : 198|1@1+ (1,0) [0|1] ""  RDR05
 SG_ DET_CONFD_AZIMUTH_126_Rx : 230|2@1+ (1,0) [0|3] ""  RDR05
 SG_ DET_CONFD_ELEVATION_126_Rx : 213|2@1+ (1,0) [0|3] ""  RDR05
 SG_ DET_PROB_1STAZHYPO_126_Rx : 215|1@1+ (1,0) [0|1] ""  RDR05
 SG_ DET_IDM_126_Rx : 175|1@1+ (1,0) [0|1] ""  RDR05
 SG_ DET_MTD_126_Rx : 159|1@1+ (1,0) [0|1] ""  RDR05
 SG_ DET_BELOW_RAIN_THOLD_126_Rx : 151|1@1+ (1,0) [0|1] ""  RDR05
 SG_ DET_RANGE_127_Rx : 248|15@1+ (0.015625,0) [0|500] "m"  RDR05
 SG_ DET_RANGE_ERR_127_Rx : 264|7@1+ (0.0075,0) [0|0.9525] "m"  RDR05
 SG_ DET_RANGE_VELOCITY_127_Rx : 272|15@1+ (0.0078125,-128) [-128|127.9921875] "m/s"  RDR05
 SG_ DET_RANGE_VELOCITY_ERR_127_Rx : 288|8@1+ (0.003,0) [0|0.765] "m/s"  RDR05
 SG_ DET_AZIMUTH_127_Rx : 312|13@1+ (0.0004,-1.5708) [-1.5708|1.5708] "rad"  RDR05
 SG_ DET_AZIMUTH_ERR_127_Rx : 329|7@1+ (0.00087267,0) [0|0.11082909] "rad"  RDR05
 SG_ DET_ELEVATION_127_Rx : 296|8@1+ (0.00275,-0.34925) [-0.34925|0.34925] "rad"  RDR05
 SG_ DET_ELEVATION_ERR_127_Rx : 304|6@1+ (0.00174533,0) [0|0.10995579] "rad"  RDR05
 SG_ DET_RCS_127_Rx : 352|8@1+ (0.5,-64) [-64|63.5] "dBsm"  RDR05
 SG_ DET_BI_STATIC_FLAG_127_Rx : 328|1@1+ (1,0) [0|1] ""  RDR05
 SG_ DET_SUPER_RES_TARGET_127_Rx : 311|1@1+ (1,0) [0|1] ""  RDR05
 SG_ DET_SNR_127_Rx : 344|8@1+ (0.35156,0) [0|89.6478] "dB"  RDR05
 SG_ DET_EXISTENCE_PROB_127_Rx : 336|6@1+ (1.588,0) [0|100] "%"  RDR05
 SG_ DET_HVC_FLAG_127_Rx : 310|1@1+ (1,0) [0|1] ""  RDR05
 SG_ DET_CONFD_AZIMUTH_127_Rx : 342|2@1+ (1,0) [0|3] ""  RDR05
 SG_ DET_CONFD_ELEVATION_127_Rx : 325|2@1+ (1,0) [0|3] ""  RDR05
 SG_ DET_PROB_1STAZHYPO_127_Rx : 327|1@1+ (1,0) [0|1] ""  RDR05
 SG_ DET_IDM_127_Rx : 287|1@1+ (1,0) [0|1] ""  RDR05
 SG_ DET_MTD_127_Rx : 271|1@1+ (1,0) [0|1] ""  RDR05
 SG_ DET_BELOW_RAIN_THOLD_127_Rx : 263|1@1+ (1,0) [0|1] ""  RDR05
 SG_ DET_RANGE_128_Rx : 360|15@1+ (0.015625,0) [0|500] "m"  RDR05
 SG_ DET_RANGE_ERR_128_Rx : 376|7@1+ (0.0075,0) [0|0.9525] "m"  RDR05
 SG_ DET_RANGE_VELOCITY_128_Rx : 384|15@1+ (0.0078125,-128) [-128|127.9921875] "m/s"  RDR05
 SG_ DET_RANGE_VELOCITY_ERR_128_Rx : 400|8@1+ (0.003,0) [0|0.765] "m/s"  RDR05
 SG_ DET_AZIMUTH_128_Rx : 424|13@1+ (0.0004,-1.5708) [-1.5708|1.5708] "rad"  RDR05
 SG_ DET_AZIMUTH_ERR_128_Rx : 441|7@1+ (0.00087267,0) [0|0.11082909] "rad"  RDR05
 SG_ DET_ELEVATION_128_Rx : 408|8@1+ (0.00275,-0.34925) [-0.34925|0.34925] "rad"  RDR05
 SG_ DET_ELEVATION_ERR_128_Rx : 416|6@1+ (0.00174533,0) [0|0.10995579] "rad"  RDR05
 SG_ DET_RCS_128_Rx : 464|8@1+ (0.5,-64) [-64|63.5] "dBsm"  RDR05
 SG_ DET_BI_STATIC_FLAG_128_Rx : 440|1@1+ (1,0) [0|1] ""  RDR05
 SG_ DET_SUPER_RES_TARGET_128_Rx : 423|1@1+ (1,0) [0|1] ""  RDR05
 SG_ DET_SNR_128_Rx : 456|8@1+ (0.35156,0) [0|89.6478] "dB"  RDR05
 SG_ DET_EXISTENCE_PROB_128_Rx : 448|6@1+ (1.588,0) [0|100] "%"  RDR05
 SG_ DET_HVC_FLAG_128_Rx : 422|1@1+ (1,0) [0|1] ""  RDR05
 SG_ DET_CONFD_AZIMUTH_128_Rx : 454|2@1+ (1,0) [0|3] ""  RDR05
 SG_ DET_CONFD_ELEVATION_128_Rx : 437|2@1+ (1,0) [0|3] ""  RDR05
 SG_ DET_MH_SCAN_INDEX_4LSB_125_128_R : 476|4@1+ (1,0) [0|15] ""  RDR05
 SG_ DET_MH_CYCLE_COUNTER_125_128_Rx : 16|8@1+ (1,0) [0|255] ""  RDR05
 SG_ DET_MH_CRC16_125_128_Rx : 0|16@1+ (1,0) [0|65535] ""  RDR05
 SG_ DET_PROB_1STAZHYPO_128_Rx : 439|1@1+ (1,0) [0|1] ""  RDR05
 SG_ DET_IDM_128_Rx : 399|1@1+ (1,0) [0|1] ""  RDR05
 SG_ DET_MTD_128_Rx : 383|1@1+ (1,0) [0|1] ""  RDR05
 SG_ DET_BELOW_RAIN_THOLD_128_Rx : 375|1@1+ (1,0) [0|1] ""  RDR05

BO_ 419224576 GW_CCVS3: 8 RDR_Gateway
 SG_ AEBSReadinessState : 24|2@1+ (1,0) [0|3] "" Vector__XXX

BO_ 419224577 GW_CCVS3_Tx: 8 Vector__XXX
 SG_ AEBSReadinessState_Tx : 24|2@1+ (1,0) [0|3] ""  RDR_Gateway

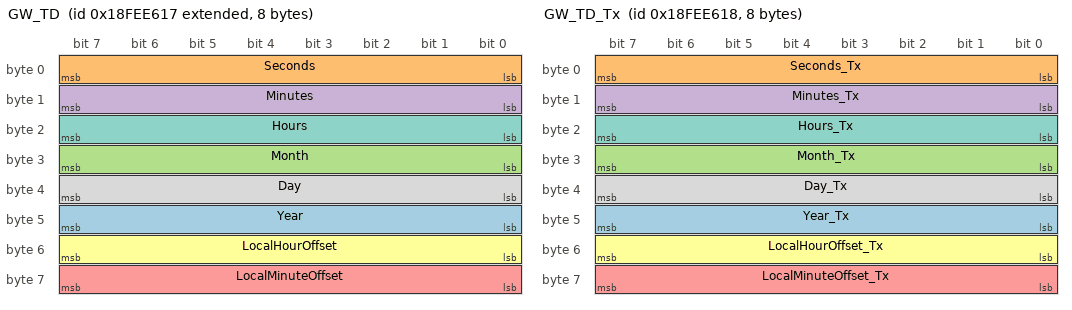
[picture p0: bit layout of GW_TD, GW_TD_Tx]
BO_ 2566841879 GW_TD: 8 RDR_Gateway
 SG_ Year : 40|8@1+ (1,0) [0|255] "year"  RDR05
 SG_ Seconds : 0|8@1+ (0.25,0) [0|59] "s"  RDR05
 SG_ Month : 24|8@1+ (1,0) [0|12] "month"  RDR05
 SG_ Minutes : 8|8@1+ (1,0) [0|59] "min"  RDR05
 SG_ LocalMinuteOffset : 56|8@1+ (1,-125) [-125|130] "h"  RDR05
 SG_ LocalHourOffset : 48|8@1+ (1,-125) [-125|130] "min"  RDR05
 SG_ Hours : 16|8@1+ (1,0) [0|255] "h"  RDR05
 SG_ Day : 32|8@1+ (0.25,0) [0|31] "day"  RDR05

BO_ 419358232 GW_TD_Tx: 8 RDR05
 SG_ Year_Tx : 40|8@1+ (1,0) [0|255] "year"  RDR_Gateway
 SG_ Seconds_Tx : 0|8@1+ (0.25,0) [0|59] "s"  RDR_Gateway
 SG_ Month_Tx : 24|8@1+ (1,0) [0|12] "month"  RDR_Gateway
 SG_ Minutes_Tx : 8|8@1+ (1,0) [0|59] "min"  RDR_Gateway
 SG_ LocalMinuteOffset_Tx : 56|8@1+ (1,-125) [-125|130] "h"  RDR_Gateway
 SG_ LocalHourOffset_Tx : 48|8@1+ (1,-125) [-125|130] "min"  RDR_Gateway
 SG_ Hours_Tx : 16|8@1+ (1,0) [0|255] "h"  RDR_Gateway
 SG_ Day_Tx : 32|8@1+ (0.25,0) [0|31] "day"  RDR_Gateway

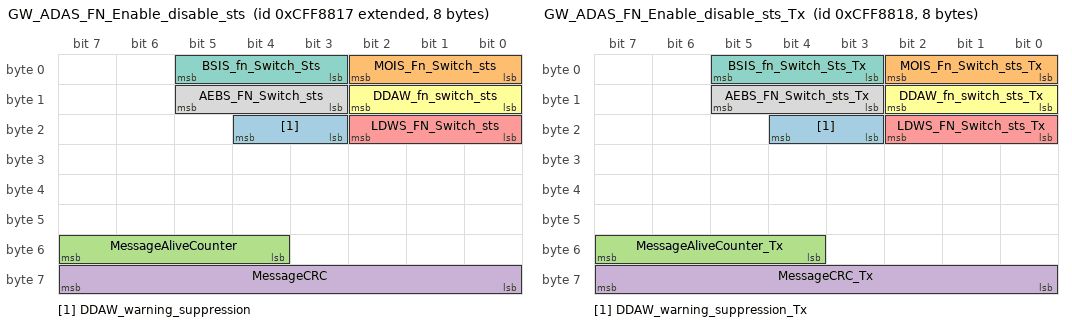
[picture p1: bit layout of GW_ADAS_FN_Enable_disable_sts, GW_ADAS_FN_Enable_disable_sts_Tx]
BO_ 2365556759 GW_ADAS_FN_Enable_disable_sts: 8 RDR_Gateway
 SG_ DDAW_warning_suppression : 19|2@1+ (1,0) [0|3] ""  RDR05
 SG_ MOIS_Fn_Switch_sts : 0|3@1+ (1,0) [0|7] ""  RDR05
 SG_ MessageAliveCounter : 52|4@1+ (1,0) [0|15] "count"  RDR05
 SG_ MessageCRC : 56|8@1+ (1,0) [0|255] "count"  RDR05
 SG_ LDWS_FN_Switch_sts : 16|3@1+ (1,0) [0|7] ""  RDR05
 SG_ DDAW_fn_switch_sts : 8|3@1+ (1,0) [0|7] ""  RDR05
 SG_ BSIS_fn_Switch_Sts : 3|3@1+ (1,0) [0|7] ""  RDR05
 SG_ AEBS_FN_Switch_sts : 11|3@1+ (1,0) [0|7] ""  RDR05

BO_ 218073112 GW_ADAS_FN_Enable_disable_sts_Tx: 8 RDR05
 SG_ DDAW_warning_suppression_Tx : 19|2@1+ (1,0) [0|3] ""  RDR_Gateway
 SG_ MOIS_Fn_Switch_sts_Tx : 0|3@1+ (1,0) [0|7] ""  RDR_Gateway
 SG_ MessageAliveCounter_Tx : 52|4@1+ (1,0) [0|15] "count"  RDR_Gateway
 SG_ MessageCRC_Tx : 56|8@1+ (1,0) [0|255] "count"  RDR_Gateway
 SG_ LDWS_FN_Switch_sts_Tx : 16|3@1+ (1,0) [0|7] ""  RDR_Gateway
 SG_ DDAW_fn_switch_sts_Tx : 8|3@1+ (1,0) [0|7] ""  RDR_Gateway
 SG_ BSIS_fn_Switch_Sts_Tx : 3|3@1+ (1,0) [0|7] ""  RDR_Gateway
 SG_ AEBS_FN_Switch_sts_Tx : 11|3@1+ (1,0) [0|7] ""  RDR_Gateway

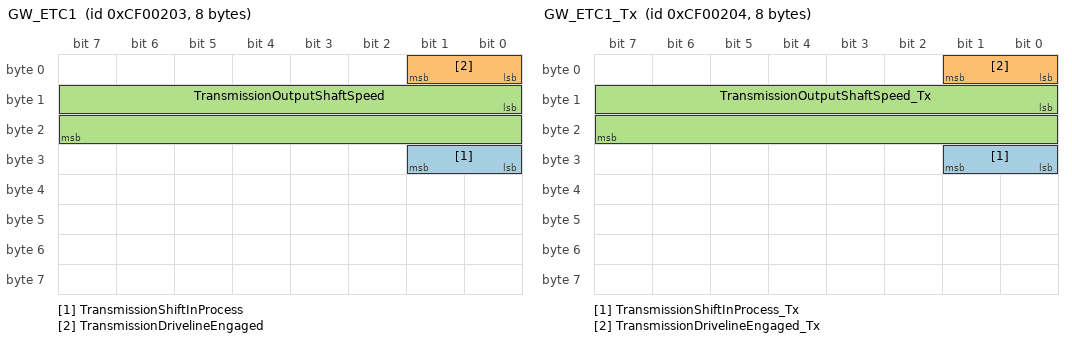
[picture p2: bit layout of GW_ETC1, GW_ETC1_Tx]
BO_ 217055747 GW_ETC1: 8 RDR_Gateway
 SG_ TransmissionShiftInProcess : 24|2@1+ (1,0) [0|3] "" Vector__XXX
 SG_ TransmissionDrivelineEngaged : 0|2@1+ (1,0) [0|3] "" Vector__XXX
 SG_ TransmissionOutputShaftSpeed : 8|16@1+ (0.125,0) [0|8031.875] "rpm" Vector__XXX

BO_ 217055748 GW_ETC1_Tx: 8 Vector__XXX
 SG_ TransmissionShiftInProcess_Tx : 24|2@1+ (1,0) [0|3] ""  RDR_Gateway
 SG_ TransmissionDrivelineEngaged_Tx : 0|2@1+ (1,0) [0|3] ""  RDR_Gateway
 SG_ TransmissionOutputShaftSpeed_Tx : 8|16@1+ (0.125,0) [0|8031.875] "rpm"  RDR_Gateway

BO_ 419318275 GW_ETC7: 8 RDR_Gateway
 SG_ TransmissionMode1Indicator : 22|2@1+ (1,0) [0|3] "" Vector__XXX

BO_ 419318276 GW_ETC7_Tx: 8 Vector__XXX
 SG_ TransmissionMode1Indicator_Tx : 22|2@1+ (1,0) [0|3] ""  RDR_Gateway

BO_ 2566848791 GW_CLS_Tx_16: 8 RDR_Gateway
 SG_ Transmission_type_info : 41|3@1+ (1,0) [0|7] ""  RDR05
 SG_ Crawler_confi_status_info : 40|1@1+ (1,0) [0|1] ""  RDR05

BO_ 419365144 GW_CLS_Tx_16_Tx: 8 RDR05
 SG_ Transmission_type_info_Tx : 41|3@1+ (1,0) [0|7] ""  RDR_Gateway
 SG_ Crawler_confi_status_info_Tx : 40|1@1+ (1,0) [0|1] ""  RDR_Gateway

BO_ 2566869015 GW_CLS_Tx_4: 8 RDR_Gateway
 SG_ Ignition : 32|2@1+ (1,0) [0|3] ""  RDR05
 SG_ ReverseSwitchInfo : 28|2@1+ (1,0) [0|3] ""  RDR05

BO_ 419385368 GW_CLS_Tx_4_Tx: 8 RDR05
 SG_ Ignition_Tx : 32|2@1+ (1,0) [0|3] ""  RDR_Gateway
 SG_ ReverseSwitchInfo_Tx : 28|2@1+ (1,0) [0|3] ""  RDR_Gateway

BO_ 417898533 GW_ACKM_A0: 8 RDR_Gateway
 SG_ ParameterGroupNumber : 40|24@1+ (1,0) [0|16777215] "" Vector__XXX
 SG_ AddressBusy m3 : 32|8@1+ (1,0) [0|255] "" Vector__XXX
 SG_ AddressAccessDenied m2 : 32|8@1+ (1,0) [0|255] "" Vector__XXX
 SG_ AddressNegativeAcknowledgement m1 : 32|8@1+ (1,0) [0|255] "" Vector__XXX
 SG_ AddressAcknowledged m0 : 32|8@1+ (1,0) [0|255] "" Vector__XXX
 SG_ GroupFunctionValue : 8|8@1+ (1,0) [0|255] "" Vector__XXX
 SG_ ControlByte M : 0|8@1+ (1,0) [0|255] "" Vector__XXX

BO_ 417910821 RDR_GW_ACKM_D0: 8 Vector__XXX
 SG_ ParameterGroupNumber : 40|24@1+ (1,0) [0|16777215] ""  RDR_Gateway
 SG_ AddressBusy m3 : 32|8@1+ (1,0) [0|255] ""  RDR_Gateway
 SG_ AddressAccessDenied m2 : 32|8@1+ (1,0) [0|255] ""  RDR_Gateway
 SG_ AddressNegativeAcknowledgement m1 : 32|8@1+ (1,0) [0|255] ""  RDR_Gateway
 SG_ AddressAcknowledged m0 : 32|8@1+ (1,0) [0|255] ""  RDR_Gateway
 SG_ GroupFunctionValue : 8|8@1+ (1,0) [0|255] ""  RDR_Gateway
 SG_ ControlByte M : 0|8@1+ (1,0) [0|255] ""  RDR_Gateway

BO_ 2566843429 GW_VI: 8 RDR_Gateway
 SG_ VehicleIdentification : 0|8@1+ (1,0) [0|255] ""  RDR05

BO_ 419359782 GW_VI_Tx: 8 RDR05
 SG_ VehicleIdentification_Tx : 0|8@1+ (1,0) [0|255] ""  RDR_Gateway

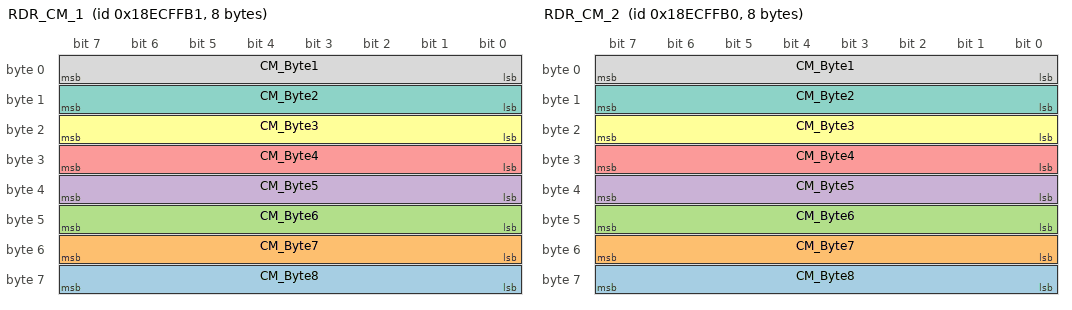
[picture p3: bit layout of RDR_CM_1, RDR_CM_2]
BO_ 418185137 RDR_CM_1: 8 RDR_Gateway
 SG_ CM_Byte8 : 56|8@1+ (1,0) [0|255] "" Vector__XXX
 SG_ CM_Byte7 : 48|8@1+ (1,0) [0|255] "" Vector__XXX
 SG_ CM_Byte6 : 40|8@1+ (1,0) [0|255] "" Vector__XXX
 SG_ CM_Byte5 : 32|8@1+ (1,0) [0|255] "" Vector__XXX
 SG_ CM_Byte4 : 24|8@1+ (1,0) [0|255] "" Vector__XXX
 SG_ CM_Byte3 : 16|8@1+ (1,0) [0|255] "" Vector__XXX
 SG_ CM_Byte2 : 8|8@1+ (1,0) [0|255] "" Vector__XXX
 SG_ CM_Byte1 : 0|8@1+ (1,0) [0|255] "" Vector__XXX

BO_ 418185136 RDR_CM_2: 8 RDR_Gateway
 SG_ CM_Byte8 : 56|8@1+ (1,0) [0|255] "" Vector__XXX
 SG_ CM_Byte7 : 48|8@1+ (1,0) [0|255] "" Vector__XXX
 SG_ CM_Byte6 : 40|8@1+ (1,0) [0|255] "" Vector__XXX
 SG_ CM_Byte5 : 32|8@1+ (1,0) [0|255] "" Vector__XXX
 SG_ CM_Byte4 : 24|8@1+ (1,0) [0|255] "" Vector__XXX
 SG_ CM_Byte3 : 16|8@1+ (1,0) [0|255] "" Vector__XXX
 SG_ CM_Byte2 : 8|8@1+ (1,0) [0|255] "" Vector__XXX
 SG_ CM_Byte1 : 0|8@1+ (1,0) [0|255] "" Vector__XXX

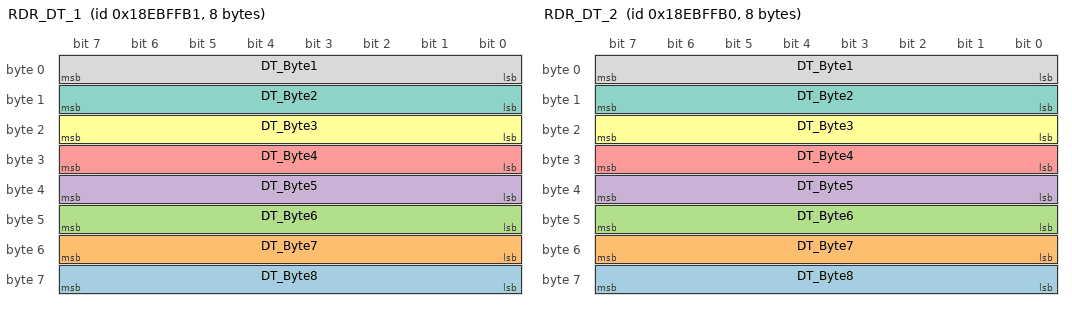
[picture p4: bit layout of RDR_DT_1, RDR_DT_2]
BO_ 418119601 RDR_DT_1: 8 RDR_Gateway
 SG_ DT_Byte8 : 56|8@1+ (1,0) [0|255] "" Vector__XXX
 SG_ DT_Byte7 : 48|8@1+ (1,0) [0|255] "" Vector__XXX
 SG_ DT_Byte6 : 40|8@1+ (1,0) [0|255] "" Vector__XXX
 SG_ DT_Byte5 : 32|8@1+ (1,0) [0|255] "" Vector__XXX
 SG_ DT_Byte4 : 24|8@1+ (1,0) [0|255] "" Vector__XXX
 SG_ DT_Byte3 : 16|8@1+ (1,0) [0|255] "" Vector__XXX
 SG_ DT_Byte2 : 8|8@1+ (1,0) [0|255] "" Vector__XXX
 SG_ DT_Byte1 : 0|8@1+ (1,0) [0|255] "" Vector__XXX

BO_ 418119600 RDR_DT_2: 8 RDR_Gateway
 SG_ DT_Byte8 : 56|8@1+ (1,0) [0|255] "" Vector__XXX
 SG_ DT_Byte7 : 48|8@1+ (1,0) [0|255] "" Vector__XXX
 SG_ DT_Byte6 : 40|8@1+ (1,0) [0|255] "" Vector__XXX
 SG_ DT_Byte5 : 32|8@1+ (1,0) [0|255] "" Vector__XXX
 SG_ DT_Byte4 : 24|8@1+ (1,0) [0|255] "" Vector__XXX
 SG_ DT_Byte3 : 16|8@1+ (1,0) [0|255] "" Vector__XXX
 SG_ DT_Byte2 : 8|8@1+ (1,0) [0|255] "" Vector__XXX
 SG_ DT_Byte1 : 0|8@1+ (1,0) [0|255] "" Vector__XXX

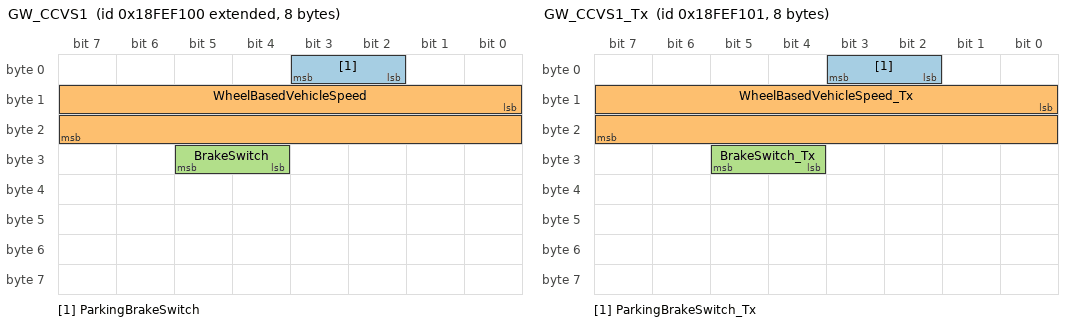
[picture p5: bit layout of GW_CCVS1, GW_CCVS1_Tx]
BO_ 2566844672 GW_CCVS1: 8 RDR_Gateway
 SG_ ParkingBrakeSwitch : 2|2@1+ (1,0) [0|3] ""  RDR05
 SG_ WheelBasedVehicleSpeed : 8|16@1+ (0.00390625,0) [0|255.99609375] "km/h"  RDR05
 SG_ BrakeSwitch : 28|2@1+ (1,0) [0|3] ""  RDR05

BO_ 419361025 GW_CCVS1_Tx: 8 RDR05
 SG_ ParkingBrakeSwitch_Tx : 2|2@1+ (1,0) [0|3] ""  RDR_Gateway
 SG_ WheelBasedVehicleSpeed_Tx : 8|16@1+ (0.00390625,0) [0|255.99609375] "km/h"  RDR_Gateway
 SG_ BrakeSwitch_Tx : 28|2@1+ (1,0) [0|3] ""  RDR_Gateway

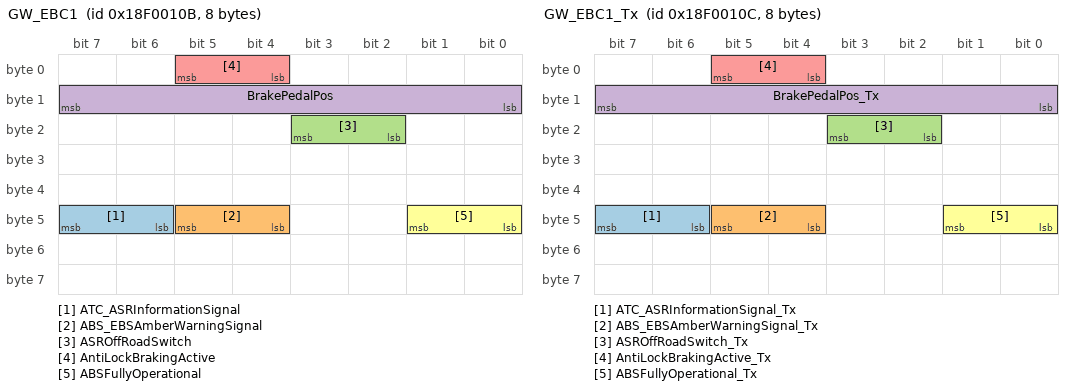
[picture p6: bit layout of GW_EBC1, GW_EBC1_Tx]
BO_ 418382091 GW_EBC1: 8 RDR_Gateway
 SG_ ATC_ASRInformationSignal : 46|2@1+ (1,0) [0|3] "" Vector__XXX
 SG_ ABS_EBSAmberWarningSignal : 44|2@1+ (1,0) [0|3] "" Vector__XXX
 SG_ ASROffRoadSwitch : 18|2@1+ (1,0) [0|3] "" Vector__XXX
 SG_ BrakePedalPos : 8|8@1+ (0.4,0) [0|100] "%" Vector__XXX
 SG_ AntiLockBrakingActive : 4|2@1+ (1,0) [0|3] "" Vector__XXX
 SG_ ABSFullyOperational : 40|2@1+ (1,0) [0|3] "" Vector__XXX

BO_ 418382092 GW_EBC1_Tx: 8 Vector__XXX
 SG_ ATC_ASRInformationSignal_Tx : 46|2@1+ (1,0) [0|3] ""  RDR_Gateway
 SG_ ABS_EBSAmberWarningSignal_Tx : 44|2@1+ (1,0) [0|3] ""  RDR_Gateway
 SG_ ASROffRoadSwitch_Tx : 18|2@1+ (1,0) [0|3] ""  RDR_Gateway
 SG_ BrakePedalPos_Tx : 8|8@1+ (0.4,0) [0|100] "%"  RDR_Gateway
 SG_ AntiLockBrakingActive_Tx : 4|2@1+ (1,0) [0|3] ""  RDR_Gateway
 SG_ ABSFullyOperational_Tx : 40|2@1+ (1,0) [0|3] ""  RDR_Gateway

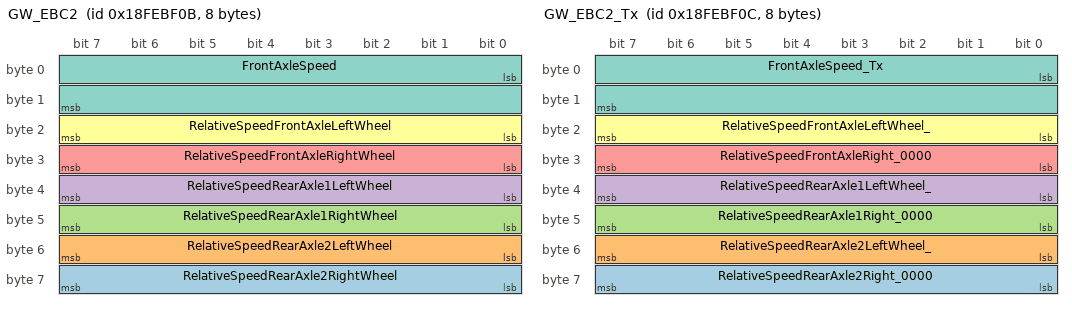
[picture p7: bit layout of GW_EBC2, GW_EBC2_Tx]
BO_ 419348235 GW_EBC2: 8 RDR_Gateway
 SG_ RelativeSpeedRearAxle2RightWheel : 56|8@1+ (0.0625,-7.8125) [-7.8125|7.8125] "km/h" Vector__XXX
 SG_ RelativeSpeedRearAxle2LeftWheel : 48|8@1+ (0.0625,-7.8125) [-7.8125|7.8125] "km/h" Vector__XXX
 SG_ RelativeSpeedRearAxle1RightWheel : 40|8@1+ (0.0625,-7.8125) [-7.8125|7.8125] "kmph" Vector__XXX
 SG_ RelativeSpeedRearAxle1LeftWheel : 32|8@1+ (0.0625,-7.8125) [-7.8125|7.8125] "kmph" Vector__XXX
 SG_ RelativeSpeedFrontAxleRightWheel : 24|8@1+ (0.0625,-7.8125) [-7.8125|7.8125] "kmph" Vector__XXX
 SG_ RelativeSpeedFrontAxleLeftWheel : 16|8@1+ (0.0625,-7.8125) [-7.8125|7.8125] "kmph" Vector__XXX
 SG_ FrontAxleSpeed : 0|16@1+ (0.0039,0) [0|250.996] "kmph" Vector__XXX

BO_ 419348236 GW_EBC2_Tx: 8 Vector__XXX
 SG_ RelativeSpeedRearAxle2Right_0000 : 56|8@1+ (0.0625,-7.8125) [-7.8125|7.8125] "km/h"  RDR_Gateway
 SG_ RelativeSpeedRearAxle2LeftWheel_ : 48|8@1+ (0.0625,-7.8125) [-7.8125|7.8125] "km/h"  RDR_Gateway
 SG_ RelativeSpeedRearAxle1Right_0000 : 40|8@1+ (0.0625,-7.8125) [-7.8125|7.8125] "kmph"  RDR_Gateway
 SG_ RelativeSpeedRearAxle1LeftWheel_ : 32|8@1+ (0.0625,-7.8125) [-7.8125|7.8125] "kmph"  RDR_Gateway
 SG_ RelativeSpeedFrontAxleRight_0000 : 24|8@1+ (0.0625,-7.8125) [-7.8125|7.8125] "kmph"  RDR_Gateway
 SG_ RelativeSpeedFrontAxleLeftWheel_ : 16|8@1+ (0.0625,-7.8125) [-7.8125|7.8125] "kmph"  RDR_Gateway
 SG_ FrontAxleSpeed_Tx : 0|16@1+ (0.0039,0) [0|250.996] "kmph"  RDR_Gateway

BO_ 217944576 GW_EOI: 8 RDR_Gateway
 SG_ Engine_Operating_Mode : 0|4@1+ (1,0) [0|15] "state" Vector__XXX

BO_ 217944577 GW_EOI_Tx: 8 Vector__XXX
 SG_ Engine_Operating_Mode_Tx : 0|4@1+ (1,0) [0|15] "state"  RDR_Gateway

BO_ 2565866752 GW_ETC2: 8 RDR_Gateway
 SG_ TransCurrentGear_00 : 24|8@1+ (1,-125) [-125|130] "gear value"  RDR05

BO_ 418383105 GW_ETC2_Tx: 8 RDR05
 SG_ TransCurrentGear_Tx : 24|8@1+ (1,-125) [-125|130] "gear value"  RDR_Gateway

BO_ 2565866755 GW_ETC2_03: 8 RDR_Gateway
 SG_ TransCurrentGear_03 : 24|8@1+ (1,-125) [-125|130] "gear value"  RDR05

BO_ 418383106 GW_ETC2_03_Tx: 8 RDR05
 SG_ TransCurrentGear_03_Tx : 24|8@1+ (1,-125) [-125|130] "gear value"  RDR_Gateway

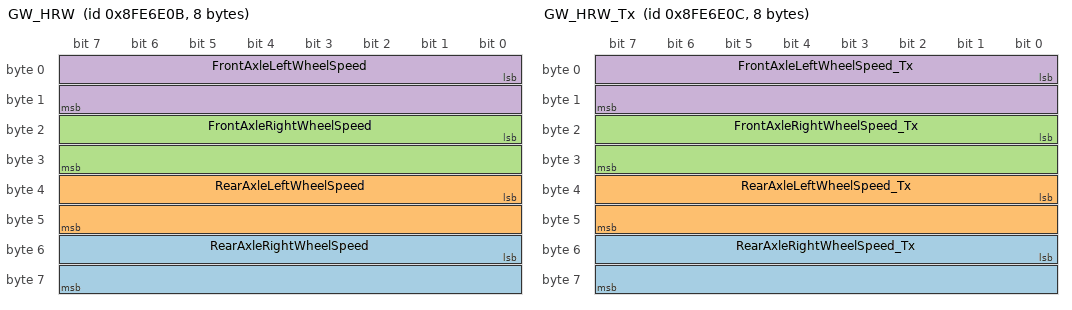
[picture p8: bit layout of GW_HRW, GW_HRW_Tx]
BO_ 150892043 GW_HRW: 8 RDR_Gateway
 SG_ RearAxleRightWheelSpeed : 48|16@1+ (0.00390625,0) [0|250.996] "kmph" Vector__XXX
 SG_ RearAxleLeftWheelSpeed : 32|16@1+ (0.00390625,0) [0|250.996] "kmph" Vector__XXX
 SG_ FrontAxleRightWheelSpeed : 16|16@1+ (0.00390625,0) [0|250.996] "kmph" Vector__XXX
 SG_ FrontAxleLeftWheelSpeed : 0|16@1+ (0.00390625,0) [0|250.996] "kmph" Vector__XXX

BO_ 150892044 GW_HRW_Tx: 8 Vector__XXX
 SG_ RearAxleRightWheelSpeed_Tx : 48|16@1+ (0.00390625,0) [0|250.996] "kmph"  RDR_Gateway
 SG_ RearAxleLeftWheelSpeed_Tx : 32|16@1+ (0.00390625,0) [0|250.996] "kmph"  RDR_Gateway
 SG_ FrontAxleRightWheelSpeed_Tx : 16|16@1+ (0.00390625,0) [0|250.996] "kmph"  RDR_Gateway
 SG_ FrontAxleLeftWheelSpeed_Tx : 0|16@1+ (0.00390625,0) [0|250.996] "kmph"  RDR_Gateway

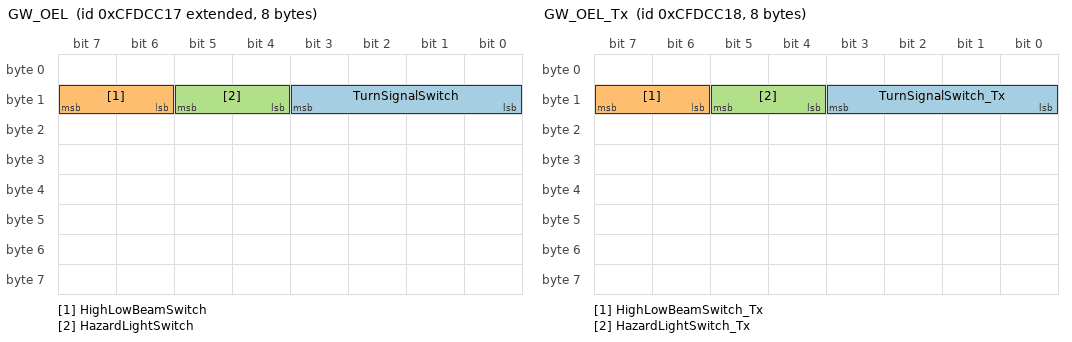
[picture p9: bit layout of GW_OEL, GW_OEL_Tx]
BO_ 2365443095 GW_OEL: 8 RDR_Gateway
 SG_ TurnSignalSwitch : 8|4@1+ (1,0) [0|15] ""  RDR05
 SG_ HighLowBeamSwitch : 14|2@1+ (1,0) [0|3] ""  RDR05
 SG_ HazardLightSwitch : 12|2@1+ (1,0) [0|3] ""  RDR05

BO_ 217959448 GW_OEL_Tx: 8 RDR05
 SG_ TurnSignalSwitch_Tx : 8|4@1+ (1,0) [0|15] ""  RDR_Gateway
 SG_ HighLowBeamSwitch_Tx : 14|2@1+ (1,0) [0|3] ""  RDR_Gateway
 SG_ HazardLightSwitch_Tx : 12|2@1+ (1,0) [0|3] ""  RDR_Gateway

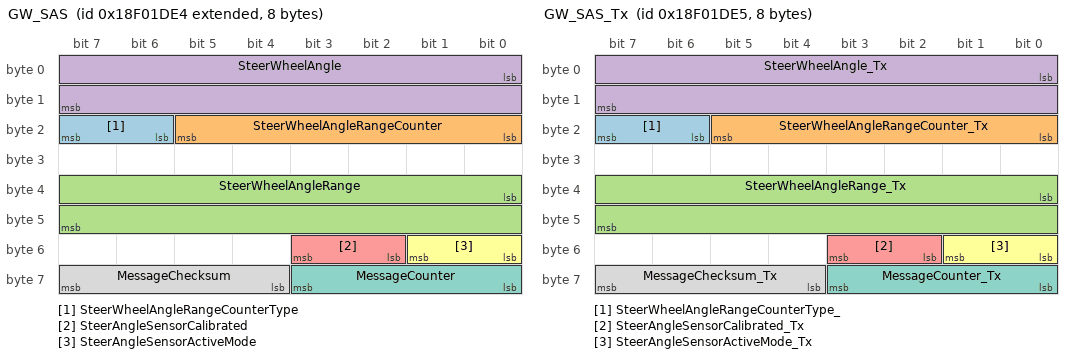
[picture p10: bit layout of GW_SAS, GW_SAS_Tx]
BO_ 2565873124 GW_SAS: 8 RDR_Gateway
 SG_ SteerWheelAngleRangeCounterType : 22|2@1+ (1,0) [0|3] ""  RDR05
 SG_ SteerWheelAngleRangeCounter : 16|6@1+ (1,-32) [-32|29] "ranges"  RDR05
 SG_ SteerWheelAngleRange : 32|16@1+ (0.0009765625,-26.878) [-26.878|37.1210234375] "rad"  RDR05
 SG_ SteerWheelAngle : 0|16@1+ (0.0009765625,-26.878) [-26.878|37.1210234375] "rad"  RDR05
 SG_ SteerAngleSensorCalibrated : 50|2@1+ (1,0) [0|3] ""  RDR05
 SG_ SteerAngleSensorActiveMode : 48|2@1+ (1,0) [0|3] ""  RDR05
 SG_ MessageCounter : 56|4@1+ (1,0) [0|15] "count"  RDR05
 SG_ MessageChecksum : 60|4@1+ (1,0) [0|15] "count"  RDR05

BO_ 418389477 GW_SAS_Tx: 8 RDR05
 SG_ SteerWheelAngleRangeCounterType_ : 22|2@1+ (1,0) [0|3] ""  RDR_Gateway
 SG_ SteerWheelAngleRangeCounter_Tx : 16|6@1+ (1,-32) [-32|29] "ranges"  RDR_Gateway
 SG_ SteerWheelAngleRange_Tx : 32|16@1+ (0.0009765625,-26.878) [-26.878|37.1210234375] "rad"  RDR_Gateway
 SG_ SteerWheelAngle_Tx : 0|16@1+ (0.0009765625,-26.878) [-26.878|37.1210234375] "rad"  RDR_Gateway
 SG_ SteerAngleSensorCalibrated_Tx : 50|2@1+ (1,0) [0|3] ""  RDR_Gateway
 SG_ SteerAngleSensorActiveMode_Tx : 48|2@1+ (1,0) [0|3] ""  RDR_Gateway
 SG_ MessageCounter_Tx : 56|4@1+ (1,0) [0|15] "count"  RDR_Gateway
 SG_ MessageChecksum_Tx : 60|4@1+ (1,0) [0|15] "count"  RDR_Gateway

BO_ 2566840320 GW_VD: 8 RDR_Gateway
 SG_ TotalVehicleDistance : 32|32@1+ (0.125,0) [0|536870911.875] "km"  RDR05

BO_ 419356673 GW_VD_Tx: 8 RDR05
 SG_ TotalVehicleDistance_Tx : 32|32@1+ (0.125,0) [0|536870911.875] "km"  RDR_Gateway

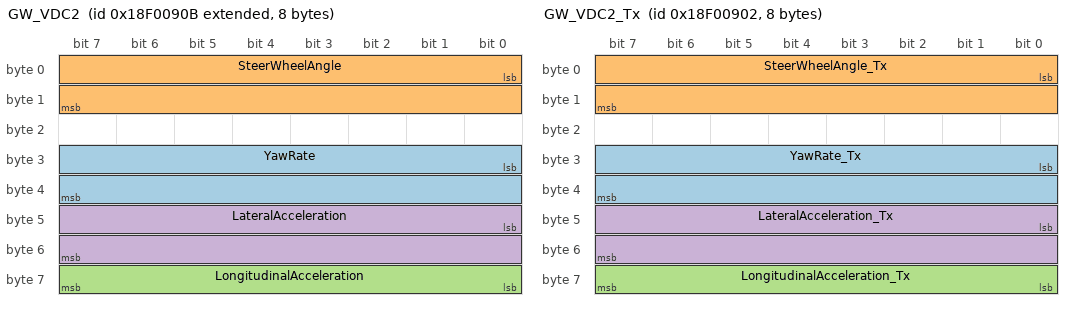
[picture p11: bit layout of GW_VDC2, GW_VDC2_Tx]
BO_ 2565867787 GW_VDC2: 8 RDR_Gateway
 SG_ YawRate : 24|16@1+ (0.00012207,-3.92) [-3.92|4.07985745] "rad/s"  RDR05
 SG_ SteerWheelAngle : 0|16@1+ (0.00097656,-31.374) [-31.374|32.6248596] "rad"  RDR05
 SG_ LongitudinalAcceleration : 56|8@1+ (0.1,-12.5) [-12.5|13] "m/s*s"  RDR05
 SG_ LateralAcceleration : 40|16@1+ (0.00048828,-15.687) [-15.687|16.3124298] "m/s*s"  RDR05

BO_ 418384130 GW_VDC2_Tx: 8 RDR05
 SG_ YawRate_Tx : 24|16@1+ (0.00012207,-3.92) [-3.92|4.07985745] "rad/s"  RDR_Gateway
 SG_ SteerWheelAngle_Tx : 0|16@1+ (0.00097656,-31.374) [-31.374|32.6248596] "rad"  RDR_Gateway
 SG_ LongitudinalAcceleration_Tx : 56|8@1+ (0.1,-12.5) [-12.5|13] "m/s*s"  RDR_Gateway
 SG_ LateralAcceleration_Tx : 40|16@1+ (0.00048828,-15.687) [-15.687|16.3124298] "m/s*s"  RDR_Gateway

BO_ 417002960 RDR_DIAG_RESP_PHYS_PLANT: 64 Vector__XXX
 SG_ Diag_Resp_Phys : 7|64@0+ (1,0) [0|0] ""  External_Tool

BO_ 417002704 RDR_DIAG_RESP_PHYS_OTA: 64 Vector__XXX
 SG_ Diag_Resp_Phys : 7|64@0+ (1,0) [0|0] ""  External_Tool

BO_ 417001936 RDR_DIAG_RESP_PHYS_OBD: 64 Vector__XXX
 SG_ Diag_Resp_Phys : 7|64@0+ (1,0) [0|0] ""  External_Tool

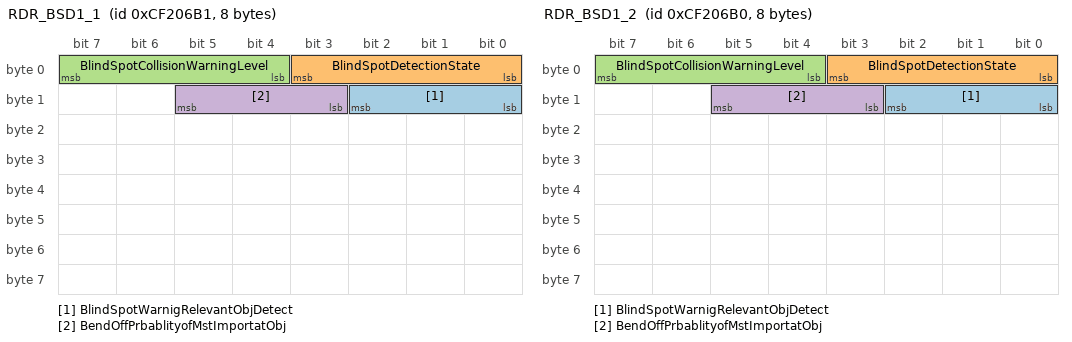
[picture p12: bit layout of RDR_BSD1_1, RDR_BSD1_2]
BO_ 217188017 RDR_BSD1_1: 8 RDR_Gateway
 SG_ BlindSpotWarnigRelevantObjDetect : 8|3@1+ (1,0) [0|7] "" Vector__XXX
 SG_ BlindSpotDetectionState : 0|4@1+ (1,0) [0|15] "" Vector__XXX
 SG_ BlindSpotCollisionWarningLevel : 4|4@1+ (1,0) [0|15] "" Vector__XXX
 SG_ BendOffPrbablityofMstImportatObj : 11|3@1+ (1,0) [0|7] "" Vector__XXX

BO_ 217188016 RDR_BSD1_2: 8 RDR_Gateway
 SG_ BlindSpotWarnigRelevantObjDetect : 8|3@1+ (1,0) [0|7] "" Vector__XXX
 SG_ BlindSpotDetectionState : 0|4@1+ (1,0) [0|15] "" Vector__XXX
 SG_ BlindSpotCollisionWarningLevel : 4|4@1+ (1,0) [0|15] "" Vector__XXX
 SG_ BendOffPrbablityofMstImportatObj : 11|3@1+ (1,0) [0|7] "" Vector__XXX

BA_DEF_ BO_  "VFrameFormat" ENUM  "StandardCAN","ExtendedCAN","reserved","reserved","reserved","reserved","reserved","reserved","reserved","reserved","reserved","reserved","reserved","reserved","StandardCAN_FD","ExtendedCAN_FD";
BA_DEF_ BO_  "CanTpBs" INT 0 255;
BA_DEF_ BO_  "DiagConnection" INT 0 65535;
BA_DEF_ BO_  "DiagRequest" ENUM  "No","Yes";
BA_DEF_ BO_  "DiagResponse" ENUM  "No","Yes";
BA_DEF_ BO_  "DiagState" ENUM  "No","Yes";
BA_DEF_ BO_  "E2EDataId" INT 0 65535;
BA_DEF_ BO_  "E2EDataLength" INT 0 65535;
BA_DEF_ BO_  "E2EProfile" STRING ;
BA_DEF_ BO_  "EventRateOfChange" INT 10 10000;
BA_DEF_ BO_  "GenMsgCycleTime" INT 0 100000;
BA_DEF_ BO_  "GenMsgILSupport" ENUM  "No","Yes";
BA_DEF_ BO_  "GenMsgNrOfRepetition" INT 0 100;
BA_DEF_ BO_  "GenMsgSendType" ENUM  "FixedPeriodic","Event","EnabledPeriodic","NotUsed","NotUsed","EventPeriodic","NotUsed","NotUsed","NoMsgSendType";
BA_DEF_ BO_  "NetworkInitialization" ENUM  "No","Yes";
BA_DEF_ BO_  "NmAsrMessage" ENUM  "No","Yes";
BA_DEF_ BO_  "NmMessage" ENUM  "No","Yes";
BA_DEF_ BO_  "SCP_AuthInfoTxLength" INT 0 512;
BA_DEF_ BO_  "SCP_FreshnessValueLength" INT 0 512;
BA_DEF_ BO_  "SCP_FreshnessValueTxLength" INT 0 512;
BA_DEF_ BO_  "TpTxIndex" INT 0 255;
BA_DEF_ SG_  "GenSigCmt" STRING ;
BA_DEF_ SG_  "GenSigCycleTime" INT 0 0;
BA_DEF_ SG_  "GenSigSendType" ENUM  "Cyclic","OnWrite","vector_leerstring","OnChange","vector_leerstring","IfActive","vector_leerstring","NoSigSendType";
BA_DEF_ SG_  "GenSigStartValue" INT 0 1000000000;
BA_DEF_ SG_  "GenSigTimeoutTime" INT 0 0;
BA_DEF_ SG_  "GenSigVtEn" STRING ;
BA_DEF_ SG_  "GenSigVtName" STRING ;
BA_DEF_ SG_  "InvalidValue" STRING ;
BA_DEF_ SG_  "SystemSignalLongSymbol" STRING ;
BA_DEF_DEF_  "VFrameFormat" "StandardCAN_FD";
BA_DEF_DEF_  "CanTpBs" 255;
BA_DEF_DEF_  "DiagConnection" 0;
BA_DEF_DEF_  "DiagRequest" "No";
BA_DEF_DEF_  "DiagResponse" "No";
BA_DEF_DEF_  "DiagState" "No";
BA_DEF_DEF_  "E2EDataId" 0;
BA_DEF_DEF_  "E2EDataLength" 0;
BA_DEF_DEF_  "E2EProfile" "";
BA_DEF_DEF_  "EventRateOfChange" 10000;
BA_DEF_DEF_  "GenMsgCycleTime" 0;
BA_DEF_DEF_  "GenMsgILSupport" "Yes";
BA_DEF_DEF_  "GenMsgNrOfRepetition" 0;
BA_DEF_DEF_  "GenMsgSendType" "NoMsgSendType";
BA_DEF_DEF_  "NetworkInitialization" "Yes";
BA_DEF_DEF_  "NmAsrMessage" "No";
BA_DEF_DEF_  "NmMessage" "No";
BA_DEF_DEF_  "SCP_AuthInfoTxLength" 28;
BA_DEF_DEF_  "SCP_FreshnessValueLength" 48;
BA_DEF_DEF_  "SCP_FreshnessValueTxLength" 4;
BA_DEF_DEF_  "TpTxIndex" 0;
BA_DEF_DEF_  "GenSigCmt" "";
BA_DEF_DEF_  "GenSigCycleTime" 0;
BA_DEF_DEF_  "GenSigSendType" "NoSigSendType";
BA_DEF_DEF_  "GenSigStartValue" 0;
BA_DEF_DEF_  "GenSigTimeoutTime" 0;
BA_DEF_DEF_  "GenSigVtEn" "";
BA_DEF_DEF_  "GenSigVtName" "";
BA_DEF_DEF_  "InvalidValue" "";
BA_DEF_DEF_  "SystemSignalLongSymbol" "";
BA_ "GenMsgILSupport" BO_ 419358232 0;
BA_ "GenMsgILSupport" BO_ 218073112 0;
BA_ "GenMsgILSupport" BO_ 419365144 0;
BA_ "GenMsgILSupport" BO_ 419385368 0;
BA_ "GenMsgILSupport" BO_ 419359782 0;
BA_ "GenMsgILSupport" BO_ 419361025 0;
BA_ "GenMsgILSupport" BO_ 418383105 0;
BA_ "GenMsgILSupport" BO_ 418383106 0;
BA_ "GenMsgILSupport" BO_ 217959448 0;
BA_ "GenMsgILSupport" BO_ 418389477 0;
BA_ "GenMsgILSupport" BO_ 419356673 0;
BA_ "GenMsgILSupport" BO_ 418384130 0;
BA_ "SystemSignalLongSymbol" SG_ 267 DET_MH_SCAN_INDEX_4LSB_045_048_R "DET_MH_SCAN_INDEX_4LSB_045_048_Rx";
BA_ "SystemSignalLongSymbol" SG_ 268 DET_MH_SCAN_INDEX_4LSB_049_052_R "DET_MH_SCAN_INDEX_4LSB_049_052_Rx";
BA_ "SystemSignalLongSymbol" SG_ 269 DET_MH_SCAN_INDEX_4LSB_053_056_R "DET_MH_SCAN_INDEX_4LSB_053_056_Rx";
BA_ "SystemSignalLongSymbol" SG_ 270 DET_MH_SCAN_INDEX_4LSB_057_060_R "DET_MH_SCAN_INDEX_4LSB_057_060_Rx";
BA_ "SystemSignalLongSymbol" SG_ 271 DET_MH_SCAN_INDEX_4LSB_061_064_R "DET_MH_SCAN_INDEX_4LSB_061_064_Rx";
BA_ "SystemSignalLongSymbol" SG_ 272 DET_MH_SCAN_INDEX_4LSB_065_068_R "DET_MH_SCAN_INDEX_4LSB_065_068_Rx";
BA_ "SystemSignalLongSymbol" SG_ 273 DET_MH_SCAN_INDEX_4LSB_069_072_R "DET_MH_SCAN_INDEX_4LSB_069_072_Rx";
BA_ "SystemSignalLongSymbol" SG_ 274 DET_MH_SCAN_INDEX_4LSB_073_076_R "DET_MH_SCAN_INDEX_4LSB_073_076_Rx";
BA_ "SystemSignalLongSymbol" SG_ 275 DET_MH_SCAN_INDEX_4LSB_077_080_R "DET_MH_SCAN_INDEX_4LSB_077_080_Rx";
BA_ "SystemSignalLongSymbol" SG_ 276 DET_MH_SCAN_INDEX_4LSB_081_084_R "DET_MH_SCAN_INDEX_4LSB_081_084_Rx";
BA_ "SystemSignalLongSymbol" SG_ 277 DET_MH_SCAN_INDEX_4LSB_085_088_R "DET_MH_SCAN_INDEX_4LSB_085_088_Rx";
BA_ "SystemSignalLongSymbol" SG_ 278 DET_MH_SCAN_INDEX_4LSB_089_092_R "DET_MH_SCAN_INDEX_4LSB_089_092_Rx";
BA_ "SystemSignalLongSymbol" SG_ 279 DET_MH_SCAN_INDEX_4LSB_093_096_R "DET_MH_SCAN_INDEX_4LSB_093_096_Rx";
BA_ "SystemSignalLongSymbol" SG_ 280 DET_MH_SCAN_INDEX_4LSB_097_100_R "DET_MH_SCAN_INDEX_4LSB_097_100_Rx";
BA_ "SystemSignalLongSymbol" SG_ 281 DET_MH_SCAN_INDEX_4LSB_101_104_R "DET_MH_SCAN_INDEX_4LSB_101_104_Rx";
BA_ "SystemSignalLongSymbol" SG_ 282 DET_MH_SCAN_INDEX_4LSB_105_108_R "DET_MH_SCAN_INDEX_4LSB_105_108_Rx";
BA_ "SystemSignalLongSymbol" SG_ 283 DET_MH_SCAN_INDEX_4LSB_109_112_R "DET_MH_SCAN_INDEX_4LSB_109_112_Rx";
BA_ "SystemSignalLongSymbol" SG_ 284 DET_MH_SCAN_INDEX_4LSB_113_116_R "DET_MH_SCAN_INDEX_4LSB_113_116_Rx";
BA_ "SystemSignalLongSymbol" SG_ 285 DET_MH_SCAN_INDEX_4LSB_117_120_R "DET_MH_SCAN_INDEX_4LSB_117_120_Rx";
BA_ "SystemSignalLongSymbol" SG_ 286 DET_MH_SCAN_INDEX_4LSB_121_124_R "DET_MH_SCAN_INDEX_4LSB_121_124_Rx";
BA_ "SystemSignalLongSymbol" SG_ 287 DET_MH_SCAN_INDEX_4LSB_125_128_R "DET_MH_SCAN_INDEX_4LSB_125_128_Rx";
BA_ "SystemSignalLongSymbol" SG_ 419348236 RelativeSpeedRearAxle2Right_0000 "RelativeSpeedRearAxle2RightWheel_Tx";
BA_ "SystemSignalLongSymbol" SG_ 419348236 RelativeSpeedRearAxle2LeftWheel_ "RelativeSpeedRearAxle2LeftWheel_Tx";
BA_ "SystemSignalLongSymbol" SG_ 419348236 RelativeSpeedRearAxle1Right_0000 "RelativeSpeedRearAxle1RightWheel_Tx";
BA_ "SystemSignalLongSymbol" SG_ 419348236 RelativeSpeedRearAxle1LeftWheel_ "RelativeSpeedRearAxle1LeftWheel_Tx";
BA_ "SystemSignalLongSymbol" SG_ 419348236 RelativeSpeedFrontAxleRight_0000 "RelativeSpeedFrontAxleRightWheel_Tx";
BA_ "SystemSignalLongSymbol" SG_ 419348236 RelativeSpeedFrontAxleLeftWheel_ "RelativeSpeedFrontAxleLeftWheel_Tx";
BA_ "SystemSignalLongSymbol" SG_ 418389477 SteerWheelAngleRangeCounterType_ "SteerWheelAngleRangeCounterType_Tx";
SIG_GROUP_ 2566841879 GW_TD 1 : Year Seconds Month Minutes LocalMinuteOffset LocalHourOffset Hours Day;
SIG_GROUP_ 2365556759 GW_ADAS_FN_Enable_disable_sts 1 : DDAW_warning_suppression MOIS_Fn_Switch_sts MessageAliveCounter MessageCRC LDWS_FN_Switch_sts DDAW_fn_switch_sts BSIS_fn_Switch_Sts AEBS_FN_Switch_sts;
SIG_GROUP_ 2566848791 GW_CLS_Tx_16 1 : Transmission_type_info Crawler_confi_status_info;
SIG_GROUP_ 2566869015 GW_CLS_Tx_4 1 : Ignition ReverseSwitchInfo;
SIG_GROUP_ 2566843429 GW_VI 1 : VehicleIdentification;
SIG_GROUP_ 2566844672 GW_CCVS1 1 : ParkingBrakeSwitch WheelBasedVehicleSpeed BrakeSwitch;
SIG_GROUP_ 2565866752 GW_ETC2 1 : TransCurrentGear_00;
SIG_GROUP_ 2565866755 GW_ETC2_03 1 : TransCurrentGear_03;
SIG_GROUP_ 2365443095 GW_OEL 1 : TurnSignalSwitch HighLowBeamSwitch HazardLightSwitch;
SIG_GROUP_ 2565873124 GW_SAS 1 : SteerWheelAngleRangeCounterType SteerWheelAngleRangeCounter SteerWheelAngleRange SteerWheelAngle SteerAngleSensorCalibrated SteerAngleSensorActiveMode MessageCounter MessageChecksum;
SIG_GROUP_ 2566840320 GW_VD 1 : TotalVehicleDistance;
SIG_GROUP_ 2565867787 GW_VDC2 1 : YawRate SteerWheelAngle LongitudinalAcceleration LateralAcceleration;
SIG_GROUP_ 267 Fusion_Detections_045_048 1 : DET_PROB_1STAZHYPO_045_Rx DET_PROB_1STAZHYPO_046_Rx DET_PROB_1STAZHYPO_047_Rx DET_PROB_1STAZHYPO_048_Rx DET_IDM_045_Rx DET_IDM_046_Rx DET_IDM_047_Rx DET_IDM_048_Rx DET_MTD_048_Rx DET_MTD_047_Rx DET_MTD_046_Rx DET_MTD_045_Rx DET_BELOW_RAIN_THOLD_048_Rx DET_BELOW_RAIN_THOLD_047_Rx DET_BELOW_RAIN_THOLD_046_Rx DET_BELOW_RAIN_THOLD_045_Rx DET_MH_CRC16_045_048_Rx DET_MH_CYCLE_COUNTER_045_048_Rx DET_MH_SCAN_INDEX_4LSB_045_048_R DET_CONFD_ELEVATION_045_Rx DET_CONFD_AZIMUTH_045_Rx DET_HVC_FLAG_045_Rx DET_EXISTENCE_PROB_045_Rx DET_SNR_045_Rx DET_SUPER_RES_TARGET_045_Rx DET_BI_STATIC_FLAG_045_Rx DET_RCS_045_Rx DET_ELEVATION_ERR_045_Rx DET_ELEVATION_045_Rx DET_AZIMUTH_ERR_045_Rx DET_AZIMUTH_045_Rx DET_RANGE_VELOCITY_ERR_045_Rx DET_RANGE_VELOCITY_045_Rx DET_RANGE_ERR_045_Rx DET_RANGE_045_Rx DET_CONFD_ELEVATION_046_Rx DET_CONFD_AZIMUTH_046_Rx DET_HVC_FLAG_046_Rx DET_EXISTENCE_PROB_046_Rx DET_SNR_046_Rx DET_SUPER_RES_TARGET_046_Rx DET_BI_STATIC_FLAG_046_Rx DET_RCS_046_Rx DET_ELEVATION_ERR_046_Rx DET_ELEVATION_046_Rx DET_AZIMUTH_ERR_046_Rx DET_AZIMUTH_046_Rx DET_RANGE_VELOCITY_ERR_046_Rx DET_RANGE_VELOCITY_046_Rx DET_RANGE_ERR_046_Rx DET_RANGE_046_Rx DET_CONFD_ELEVATION_047_Rx DET_CONFD_AZIMUTH_047_Rx DET_HVC_FLAG_047_Rx DET_EXISTENCE_PROB_047_Rx DET_SNR_047_Rx DET_SUPER_RES_TARGET_047_Rx DET_BI_STATIC_FLAG_047_Rx DET_RCS_047_Rx DET_ELEVATION_ERR_047_Rx DET_ELEVATION_047_Rx DET_AZIMUTH_ERR_047_Rx DET_AZIMUTH_047_Rx DET_RANGE_VELOCITY_ERR_047_Rx DET_RANGE_VELOCITY_047_Rx DET_RANGE_ERR_047_Rx DET_RANGE_047_Rx DET_CONFD_ELEVATION_048_Rx DET_CONFD_AZIMUTH_048_Rx DET_HVC_FLAG_048_Rx DET_EXISTENCE_PROB_048_Rx DET_SNR_048_Rx DET_SUPER_RES_TARGET_048_Rx DET_BI_STATIC_FLAG_048_Rx DET_RCS_048_Rx DET_ELEVATION_ERR_048_Rx DET_ELEVATION_048_Rx DET_AZIMUTH_ERR_048_Rx DET_AZIMUTH_048_Rx DET_RANGE_VELOCITY_ERR_048_Rx DET_RANGE_VELOCITY_048_Rx DET_RANGE_ERR_048_Rx DET_RANGE_048_Rx;
SIG_GROUP_ 268 Fusion_Detections_049_052 1 : DET_PROB_1STAZHYPO_049_Rx DET_PROB_1STAZHYPO_050_Rx DET_PROB_1STAZHYPO_051_Rx DET_PROB_1STAZHYPO_052_Rx DET_IDM_049_Rx DET_IDM_050_Rx DET_IDM_051_Rx DET_IDM_052_Rx DET_MTD_052_Rx DET_MTD_051_Rx DET_MTD_050_Rx DET_MTD_049_Rx DET_BELOW_RAIN_THOLD_052_Rx DET_BELOW_RAIN_THOLD_051_Rx DET_BELOW_RAIN_THOLD_050_Rx DET_BELOW_RAIN_THOLD_049_Rx DET_MH_CRC16_049_052_Rx DET_MH_CYCLE_COUNTER_049_052_Rx DET_MH_SCAN_INDEX_4LSB_049_052_R DET_CONFD_ELEVATION_049_Rx DET_CONFD_AZIMUTH_049_Rx DET_HVC_FLAG_049_Rx DET_EXISTENCE_PROB_049_Rx DET_SNR_049_Rx DET_SUPER_RES_TARGET_049_Rx DET_BI_STATIC_FLAG_049_Rx DET_RCS_049_Rx DET_ELEVATION_ERR_049_Rx DET_ELEVATION_049_Rx DET_AZIMUTH_ERR_049_Rx DET_AZIMUTH_049_Rx DET_RANGE_VELOCITY_ERR_049_Rx DET_RANGE_VELOCITY_049_Rx DET_RANGE_ERR_049_Rx DET_RANGE_049_Rx DET_CONFD_ELEVATION_050_Rx DET_CONFD_AZIMUTH_050_Rx DET_HVC_FLAG_050_Rx DET_EXISTENCE_PROB_050_Rx DET_SNR_050_Rx DET_SUPER_RES_TARGET_050_Rx DET_BI_STATIC_FLAG_050_Rx DET_RCS_050_Rx DET_ELEVATION_ERR_050_Rx DET_ELEVATION_050_Rx DET_AZIMUTH_ERR_050_Rx DET_AZIMUTH_050_Rx DET_RANGE_VELOCITY_ERR_050_Rx DET_RANGE_VELOCITY_050_Rx DET_RANGE_ERR_050_Rx DET_RANGE_050_Rx DET_CONFD_ELEVATION_051_Rx DET_CONFD_AZIMUTH_051_Rx DET_HVC_FLAG_051_Rx DET_EXISTENCE_PROB_051_Rx DET_SNR_051_Rx DET_SUPER_RES_TARGET_051_Rx DET_BI_STATIC_FLAG_051_Rx DET_RCS_051_Rx DET_ELEVATION_ERR_051_Rx DET_ELEVATION_051_Rx DET_AZIMUTH_ERR_051_Rx DET_AZIMUTH_051_Rx DET_RANGE_VELOCITY_ERR_051_Rx DET_RANGE_VELOCITY_051_Rx DET_RANGE_ERR_051_Rx DET_RANGE_051_Rx DET_CONFD_ELEVATION_052_Rx DET_CONFD_AZIMUTH_052_Rx DET_HVC_FLAG_052_Rx DET_EXISTENCE_PROB_052_Rx DET_SNR_052_Rx DET_SUPER_RES_TARGET_052_Rx DET_BI_STATIC_FLAG_052_Rx DET_RCS_052_Rx DET_ELEVATION_ERR_052_Rx DET_ELEVATION_052_Rx DET_AZIMUTH_ERR_052_Rx DET_AZIMUTH_052_Rx DET_RANGE_VELOCITY_ERR_052_Rx DET_RANGE_VELOCITY_052_Rx DET_RANGE_ERR_052_Rx DET_RANGE_052_Rx;
SIG_GROUP_ 269 Fusion_Detections_053_056 1 : DET_PROB_1STAZHYPO_053_Rx DET_PROB_1STAZHYPO_054_Rx DET_PROB_1STAZHYPO_055_Rx DET_PROB_1STAZHYPO_056_Rx DET_IDM_053_Rx DET_IDM_054_Rx DET_IDM_055_Rx DET_IDM_056_Rx DET_MTD_056_Rx DET_MTD_055_Rx DET_MTD_054_Rx DET_MTD_053_Rx DET_BELOW_RAIN_THOLD_056_Rx DET_BELOW_RAIN_THOLD_055_Rx DET_BELOW_RAIN_THOLD_054_Rx DET_BELOW_RAIN_THOLD_053_Rx DET_MH_CRC16_053_056_Rx DET_MH_CYCLE_COUNTER_053_056_Rx DET_MH_SCAN_INDEX_4LSB_053_056_R DET_CONFD_ELEVATION_053_Rx DET_CONFD_AZIMUTH_053_Rx DET_HVC_FLAG_053_Rx DET_EXISTENCE_PROB_053_Rx DET_SNR_053_Rx DET_SUPER_RES_TARGET_053_Rx DET_BI_STATIC_FLAG_053_Rx DET_RCS_053_Rx DET_ELEVATION_ERR_053_Rx DET_ELEVATION_053_Rx DET_AZIMUTH_ERR_053_Rx DET_AZIMUTH_053_Rx DET_RANGE_VELOCITY_ERR_053_Rx DET_RANGE_VELOCITY_053_Rx DET_RANGE_ERR_053_Rx DET_RANGE_053_Rx DET_CONFD_ELEVATION_054_Rx DET_CONFD_AZIMUTH_054_Rx DET_HVC_FLAG_054_Rx DET_EXISTENCE_PROB_054_Rx DET_SNR_054_Rx DET_SUPER_RES_TARGET_054_Rx DET_BI_STATIC_FLAG_054_Rx DET_RCS_054_Rx DET_ELEVATION_ERR_054_Rx DET_ELEVATION_054_Rx DET_AZIMUTH_ERR_054_Rx DET_AZIMUTH_054_Rx DET_RANGE_VELOCITY_ERR_054_Rx DET_RANGE_VELOCITY_054_Rx DET_RANGE_ERR_054_Rx DET_RANGE_054_Rx DET_CONFD_ELEVATION_055_Rx DET_CONFD_AZIMUTH_055_Rx DET_HVC_FLAG_055_Rx DET_EXISTENCE_PROB_055_Rx DET_SNR_055_Rx DET_SUPER_RES_TARGET_055_Rx DET_BI_STATIC_FLAG_055_Rx DET_RCS_055_Rx DET_ELEVATION_ERR_055_Rx DET_ELEVATION_055_Rx DET_AZIMUTH_ERR_055_Rx DET_AZIMUTH_055_Rx DET_RANGE_VELOCITY_ERR_055_Rx DET_RANGE_VELOCITY_055_Rx DET_RANGE_ERR_055_Rx DET_RANGE_055_Rx DET_CONFD_ELEVATION_056_Rx DET_CONFD_AZIMUTH_056_Rx DET_HVC_FLAG_056_Rx DET_EXISTENCE_PROB_056_Rx DET_SNR_056_Rx DET_SUPER_RES_TARGET_056_Rx DET_BI_STATIC_FLAG_056_Rx DET_RCS_056_Rx DET_ELEVATION_ERR_056_Rx DET_ELEVATION_056_Rx DET_AZIMUTH_ERR_056_Rx DET_AZIMUTH_056_Rx DET_RANGE_VELOCITY_ERR_056_Rx DET_RANGE_VELOCITY_056_Rx DET_RANGE_ERR_056_Rx DET_RANGE_056_Rx;
SIG_GROUP_ 270 Fusion_Detections_057_060 1 : DET_PROB_1STAZHYPO_057_Rx DET_PROB_1STAZHYPO_058_Rx DET_PROB_1STAZHYPO_059_Rx DET_PROB_1STAZHYPO_060_Rx DET_IDM_057_Rx DET_IDM_058_Rx DET_IDM_059_Rx DET_IDM_060_Rx DET_MTD_060_Rx DET_MTD_059_Rx DET_MTD_058_Rx DET_MTD_057_Rx DET_BELOW_RAIN_THOLD_060_Rx DET_BELOW_RAIN_THOLD_059_Rx DET_BELOW_RAIN_THOLD_058_Rx DET_BELOW_RAIN_THOLD_057_Rx DET_MH_CRC16_057_060_Rx DET_MH_CYCLE_COUNTER_057_060_Rx DET_MH_SCAN_INDEX_4LSB_057_060_R DET_CONFD_ELEVATION_057_Rx DET_CONFD_AZIMUTH_057_Rx DET_HVC_FLAG_057_Rx DET_EXISTENCE_PROB_057_Rx DET_SNR_057_Rx DET_SUPER_RES_TARGET_057_Rx DET_BI_STATIC_FLAG_057_Rx DET_RCS_057_Rx DET_ELEVATION_ERR_057_Rx DET_ELEVATION_057_Rx DET_AZIMUTH_ERR_057_Rx DET_AZIMUTH_057_Rx DET_RANGE_VELOCITY_ERR_057_Rx DET_RANGE_VELOCITY_057_Rx DET_RANGE_ERR_057_Rx DET_RANGE_057_Rx DET_CONFD_ELEVATION_058_Rx DET_CONFD_AZIMUTH_058_Rx DET_HVC_FLAG_058_Rx DET_EXISTENCE_PROB_058_Rx DET_SNR_058_Rx DET_SUPER_RES_TARGET_058_Rx DET_BI_STATIC_FLAG_058_Rx DET_RCS_058_Rx DET_ELEVATION_ERR_058_Rx DET_ELEVATION_058_Rx DET_AZIMUTH_ERR_058_Rx DET_AZIMUTH_058_Rx DET_RANGE_VELOCITY_ERR_058_Rx DET_RANGE_VELOCITY_058_Rx DET_RANGE_ERR_058_Rx DET_RANGE_058_Rx DET_CONFD_ELEVATION_059_Rx DET_CONFD_AZIMUTH_059_Rx DET_HVC_FLAG_059_Rx DET_EXISTENCE_PROB_059_Rx DET_SNR_059_Rx DET_SUPER_RES_TARGET_059_Rx DET_BI_STATIC_FLAG_059_Rx DET_RCS_059_Rx DET_ELEVATION_ERR_059_Rx DET_ELEVATION_059_Rx DET_AZIMUTH_ERR_059_Rx DET_AZIMUTH_059_Rx DET_RANGE_VELOCITY_ERR_059_Rx DET_RANGE_VELOCITY_059_Rx DET_RANGE_ERR_059_Rx DET_RANGE_059_Rx DET_CONFD_ELEVATION_060_Rx DET_CONFD_AZIMUTH_060_Rx DET_HVC_FLAG_060_Rx DET_EXISTENCE_PROB_060_Rx DET_SNR_060_Rx DET_SUPER_RES_TARGET_060_Rx DET_BI_STATIC_FLAG_060_Rx DET_RCS_060_Rx DET_ELEVATION_ERR_060_Rx DET_ELEVATION_060_Rx DET_AZIMUTH_ERR_060_Rx DET_AZIMUTH_060_Rx DET_RANGE_VELOCITY_ERR_060_Rx DET_RANGE_VELOCITY_060_Rx DET_RANGE_ERR_060_Rx DET_RANGE_060_Rx;
SIG_GROUP_ 271 Fusion_Detections_061_064 1 : DET_PROB_1STAZHYPO_061_Rx DET_PROB_1STAZHYPO_062_Rx DET_PROB_1STAZHYPO_063_Rx DET_PROB_1STAZHYPO_064_Rx DET_IDM_061_Rx DET_IDM_062_Rx DET_IDM_063_Rx DET_IDM_064_Rx DET_MTD_064_Rx DET_MTD_063_Rx DET_MTD_062_Rx DET_MTD_061_Rx DET_BELOW_RAIN_THOLD_064_Rx DET_BELOW_RAIN_THOLD_063_Rx DET_BELOW_RAIN_THOLD_062_Rx DET_BELOW_RAIN_THOLD_061_Rx DET_MH_CRC16_061_064_Rx DET_MH_CYCLE_COUNTER_061_064_Rx DET_MH_SCAN_INDEX_4LSB_061_064_R DET_CONFD_ELEVATION_061_Rx DET_CONFD_AZIMUTH_061_Rx DET_HVC_FLAG_061_Rx DET_EXISTENCE_PROB_061_Rx DET_SNR_061_Rx DET_SUPER_RES_TARGET_061_Rx DET_BI_STATIC_FLAG_061_Rx DET_RCS_061_Rx DET_ELEVATION_ERR_061_Rx DET_ELEVATION_061_Rx DET_AZIMUTH_ERR_061_Rx DET_AZIMUTH_061_Rx DET_RANGE_VELOCITY_ERR_061_Rx DET_RANGE_VELOCITY_061_Rx DET_RANGE_ERR_061_Rx DET_RANGE_061_Rx DET_CONFD_ELEVATION_062_Rx DET_CONFD_AZIMUTH_062_Rx DET_HVC_FLAG_062_Rx DET_EXISTENCE_PROB_062_Rx DET_SNR_062_Rx DET_SUPER_RES_TARGET_062_Rx DET_BI_STATIC_FLAG_062_Rx DET_RCS_062_Rx DET_ELEVATION_ERR_062_Rx DET_ELEVATION_062_Rx DET_AZIMUTH_ERR_062_Rx DET_AZIMUTH_062_Rx DET_RANGE_VELOCITY_ERR_062_Rx DET_RANGE_VELOCITY_062_Rx DET_RANGE_ERR_062_Rx DET_RANGE_062_Rx DET_CONFD_ELEVATION_063_Rx DET_CONFD_AZIMUTH_063_Rx DET_HVC_FLAG_063_Rx DET_EXISTENCE_PROB_063_Rx DET_SNR_063_Rx DET_SUPER_RES_TARGET_063_Rx DET_BI_STATIC_FLAG_063_Rx DET_RCS_063_Rx DET_ELEVATION_ERR_063_Rx DET_ELEVATION_063_Rx DET_AZIMUTH_ERR_063_Rx DET_AZIMUTH_063_Rx DET_RANGE_VELOCITY_ERR_063_Rx DET_RANGE_VELOCITY_063_Rx DET_RANGE_ERR_063_Rx DET_RANGE_063_Rx DET_CONFD_ELEVATION_064_Rx DET_CONFD_AZIMUTH_064_Rx DET_HVC_FLAG_064_Rx DET_EXISTENCE_PROB_064_Rx DET_SNR_064_Rx DET_SUPER_RES_TARGET_064_Rx DET_BI_STATIC_FLAG_064_Rx DET_RCS_064_Rx DET_ELEVATION_ERR_064_Rx DET_ELEVATION_064_Rx DET_AZIMUTH_ERR_064_Rx DET_AZIMUTH_064_Rx DET_RANGE_VELOCITY_ERR_064_Rx DET_RANGE_VELOCITY_064_Rx DET_RANGE_ERR_064_Rx DET_RANGE_064_Rx;
SIG_GROUP_ 272 Fusion_Detections_065_068 1 : DET_PROB_1STAZHYPO_065_Rx DET_PROB_1STAZHYPO_066_Rx DET_PROB_1STAZHYPO_067_Rx DET_PROB_1STAZHYPO_068_Rx DET_IDM_065_Rx DET_IDM_066_Rx DET_IDM_067_Rx DET_IDM_068_Rx DET_MTD_068_Rx DET_MTD_067_Rx DET_MTD_066_Rx DET_MTD_065_Rx DET_BELOW_RAIN_THOLD_068_Rx DET_BELOW_RAIN_THOLD_067_Rx DET_BELOW_RAIN_THOLD_066_Rx DET_BELOW_RAIN_THOLD_065_Rx DET_MH_CRC16_065_068_Rx DET_MH_CYCLE_COUNTER_065_068_Rx DET_MH_SCAN_INDEX_4LSB_065_068_R DET_CONFD_ELEVATION_065_Rx DET_CONFD_AZIMUTH_065_Rx DET_HVC_FLAG_065_Rx DET_EXISTENCE_PROB_065_Rx DET_SNR_065_Rx DET_SUPER_RES_TARGET_065_Rx DET_BI_STATIC_FLAG_065_Rx DET_RCS_065_Rx DET_ELEVATION_ERR_065_Rx DET_ELEVATION_065_Rx DET_AZIMUTH_ERR_065_Rx DET_AZIMUTH_065_Rx DET_RANGE_VELOCITY_ERR_065_Rx DET_RANGE_VELOCITY_065_Rx DET_RANGE_ERR_065_Rx DET_RANGE_065_Rx DET_CONFD_ELEVATION_066_Rx DET_CONFD_AZIMUTH_066_Rx DET_HVC_FLAG_066_Rx DET_EXISTENCE_PROB_066_Rx DET_SNR_066_Rx DET_SUPER_RES_TARGET_066_Rx DET_BI_STATIC_FLAG_066_Rx DET_RCS_066_Rx DET_ELEVATION_ERR_066_Rx DET_ELEVATION_066_Rx DET_AZIMUTH_ERR_066_Rx DET_AZIMUTH_066_Rx DET_RANGE_VELOCITY_ERR_066_Rx DET_RANGE_VELOCITY_066_Rx DET_RANGE_ERR_066_Rx DET_RANGE_066_Rx DET_CONFD_ELEVATION_067_Rx DET_CONFD_AZIMUTH_067_Rx DET_HVC_FLAG_067_Rx DET_EXISTENCE_PROB_067_Rx DET_SNR_067_Rx DET_SUPER_RES_TARGET_067_Rx DET_BI_STATIC_FLAG_067_Rx DET_RCS_067_Rx DET_ELEVATION_ERR_067_Rx DET_ELEVATION_067_Rx DET_AZIMUTH_ERR_067_Rx DET_AZIMUTH_067_Rx DET_RANGE_VELOCITY_ERR_067_Rx DET_RANGE_VELOCITY_067_Rx DET_RANGE_ERR_067_Rx DET_RANGE_067_Rx DET_CONFD_ELEVATION_068_Rx DET_CONFD_AZIMUTH_068_Rx DET_HVC_FLAG_068_Rx DET_EXISTENCE_PROB_068_Rx DET_SNR_068_Rx DET_SUPER_RES_TARGET_068_Rx DET_BI_STATIC_FLAG_068_Rx DET_RCS_068_Rx DET_ELEVATION_ERR_068_Rx DET_ELEVATION_068_Rx DET_AZIMUTH_ERR_068_Rx DET_AZIMUTH_068_Rx DET_RANGE_VELOCITY_ERR_068_Rx DET_RANGE_VELOCITY_068_Rx DET_RANGE_ERR_068_Rx DET_RANGE_068_Rx;
SIG_GROUP_ 273 Fusion_Detections_069_072 1 : DET_PROB_1STAZHYPO_069_Rx DET_PROB_1STAZHYPO_070_Rx DET_PROB_1STAZHYPO_071_Rx DET_PROB_1STAZHYPO_072_Rx DET_IDM_069_Rx DET_IDM_070_Rx DET_IDM_071_Rx DET_IDM_072_Rx DET_MTD_072_Rx DET_MTD_071_Rx DET_MTD_070_Rx DET_MTD_069_Rx DET_BELOW_RAIN_THOLD_072_Rx DET_BELOW_RAIN_THOLD_071_Rx DET_BELOW_RAIN_THOLD_070_Rx DET_BELOW_RAIN_THOLD_069_Rx DET_MH_CRC16_069_072_Rx DET_MH_CYCLE_COUNTER_069_072_Rx DET_MH_SCAN_INDEX_4LSB_069_072_R DET_CONFD_ELEVATION_069_Rx DET_CONFD_AZIMUTH_069_Rx DET_HVC_FLAG_069_Rx DET_EXISTENCE_PROB_069_Rx DET_SNR_069_Rx DET_SUPER_RES_TARGET_069_Rx DET_BI_STATIC_FLAG_069_Rx DET_RCS_069_Rx DET_ELEVATION_ERR_069_Rx DET_ELEVATION_069_Rx DET_AZIMUTH_ERR_069_Rx DET_AZIMUTH_069_Rx DET_RANGE_VELOCITY_ERR_069_Rx DET_RANGE_VELOCITY_069_Rx DET_RANGE_ERR_069_Rx DET_RANGE_069_Rx DET_CONFD_ELEVATION_070_Rx DET_CONFD_AZIMUTH_070_Rx DET_HVC_FLAG_070_Rx DET_EXISTENCE_PROB_070_Rx DET_SNR_070_Rx DET_SUPER_RES_TARGET_070_Rx DET_BI_STATIC_FLAG_070_Rx DET_RCS_070_Rx DET_ELEVATION_ERR_070_Rx DET_ELEVATION_070_Rx DET_AZIMUTH_ERR_070_Rx DET_AZIMUTH_070_Rx DET_RANGE_VELOCITY_ERR_070_Rx DET_RANGE_VELOCITY_070_Rx DET_RANGE_ERR_070_Rx DET_RANGE_070_Rx DET_CONFD_ELEVATION_071_Rx DET_CONFD_AZIMUTH_071_Rx DET_HVC_FLAG_071_Rx DET_EXISTENCE_PROB_071_Rx DET_SNR_071_Rx DET_SUPER_RES_TARGET_071_Rx DET_BI_STATIC_FLAG_071_Rx DET_RCS_071_Rx DET_ELEVATION_ERR_071_Rx DET_ELEVATION_071_Rx DET_AZIMUTH_ERR_071_Rx DET_AZIMUTH_071_Rx DET_RANGE_VELOCITY_ERR_071_Rx DET_RANGE_VELOCITY_071_Rx DET_RANGE_ERR_071_Rx DET_RANGE_071_Rx DET_CONFD_ELEVATION_072_Rx DET_CONFD_AZIMUTH_072_Rx DET_HVC_FLAG_072_Rx DET_EXISTENCE_PROB_072_Rx DET_SNR_072_Rx DET_SUPER_RES_TARGET_072_Rx DET_BI_STATIC_FLAG_072_Rx DET_RCS_072_Rx DET_ELEVATION_ERR_072_Rx DET_ELEVATION_072_Rx DET_AZIMUTH_ERR_072_Rx DET_AZIMUTH_072_Rx DET_RANGE_VELOCITY_ERR_072_Rx DET_RANGE_VELOCITY_072_Rx DET_RANGE_ERR_072_Rx DET_RANGE_072_Rx;
SIG_GROUP_ 274 Fusion_Detections_073_076 1 : DET_PROB_1STAZHYPO_073_Rx DET_PROB_1STAZHYPO_074_Rx DET_PROB_1STAZHYPO_075_Rx DET_PROB_1STAZHYPO_076_Rx DET_IDM_073_Rx DET_IDM_074_Rx DET_IDM_075_Rx DET_IDM_076_Rx DET_MTD_076_Rx DET_MTD_075_Rx DET_MTD_074_Rx DET_MTD_073_Rx DET_BELOW_RAIN_THOLD_076_Rx DET_BELOW_RAIN_THOLD_075_Rx DET_BELOW_RAIN_THOLD_074_Rx DET_BELOW_RAIN_THOLD_073_Rx DET_MH_CRC16_073_076_Rx DET_MH_CYCLE_COUNTER_073_076_Rx DET_MH_SCAN_INDEX_4LSB_073_076_R DET_CONFD_ELEVATION_073_Rx DET_CONFD_AZIMUTH_073_Rx DET_HVC_FLAG_073_Rx DET_EXISTENCE_PROB_073_Rx DET_SNR_073_Rx DET_SUPER_RES_TARGET_073_Rx DET_BI_STATIC_FLAG_073_Rx DET_RCS_073_Rx DET_ELEVATION_ERR_073_Rx DET_ELEVATION_073_Rx DET_AZIMUTH_ERR_073_Rx DET_AZIMUTH_073_Rx DET_RANGE_VELOCITY_ERR_073_Rx DET_RANGE_VELOCITY_073_Rx DET_RANGE_ERR_073_Rx DET_RANGE_073_Rx DET_CONFD_ELEVATION_074_Rx DET_CONFD_AZIMUTH_074_Rx DET_HVC_FLAG_074_Rx DET_EXISTENCE_PROB_074_Rx DET_SNR_074_Rx DET_SUPER_RES_TARGET_074_Rx DET_BI_STATIC_FLAG_074_Rx DET_RCS_074_Rx DET_ELEVATION_ERR_074_Rx DET_ELEVATION_074_Rx DET_AZIMUTH_ERR_074_Rx DET_AZIMUTH_074_Rx DET_RANGE_VELOCITY_ERR_074_Rx DET_RANGE_VELOCITY_074_Rx DET_RANGE_ERR_074_Rx DET_RANGE_074_Rx DET_CONFD_ELEVATION_075_Rx DET_CONFD_AZIMUTH_075_Rx DET_HVC_FLAG_075_Rx DET_EXISTENCE_PROB_075_Rx DET_SNR_075_Rx DET_SUPER_RES_TARGET_075_Rx DET_BI_STATIC_FLAG_075_Rx DET_RCS_075_Rx DET_ELEVATION_ERR_075_Rx DET_ELEVATION_075_Rx DET_AZIMUTH_ERR_075_Rx DET_AZIMUTH_075_Rx DET_RANGE_VELOCITY_ERR_075_Rx DET_RANGE_VELOCITY_075_Rx DET_RANGE_ERR_075_Rx DET_RANGE_075_Rx DET_CONFD_ELEVATION_076_Rx DET_CONFD_AZIMUTH_076_Rx DET_HVC_FLAG_076_Rx DET_EXISTENCE_PROB_076_Rx DET_SNR_076_Rx DET_SUPER_RES_TARGET_076_Rx DET_BI_STATIC_FLAG_076_Rx DET_RCS_076_Rx DET_ELEVATION_ERR_076_Rx DET_ELEVATION_076_Rx DET_AZIMUTH_ERR_076_Rx DET_AZIMUTH_076_Rx DET_RANGE_VELOCITY_ERR_076_Rx DET_RANGE_VELOCITY_076_Rx DET_RANGE_ERR_076_Rx DET_RANGE_076_Rx;
SIG_GROUP_ 275 Fusion_Detections_077_080 1 : DET_PROB_1STAZHYPO_077_Rx DET_PROB_1STAZHYPO_078_Rx DET_PROB_1STAZHYPO_079_Rx DET_PROB_1STAZHYPO_080_Rx DET_IDM_077_Rx DET_IDM_078_Rx DET_IDM_079_Rx DET_IDM_080_Rx DET_MTD_080_Rx DET_MTD_079_Rx DET_MTD_078_Rx DET_MTD_077_Rx DET_BELOW_RAIN_THOLD_080_Rx DET_BELOW_RAIN_THOLD_079_Rx DET_BELOW_RAIN_THOLD_078_Rx DET_BELOW_RAIN_THOLD_077_Rx DET_MH_CRC16_077_080_Rx DET_MH_CYCLE_COUNTER_077_080_Rx DET_MH_SCAN_INDEX_4LSB_077_080_R DET_CONFD_ELEVATION_077_Rx DET_CONFD_AZIMUTH_077_Rx DET_HVC_FLAG_077_Rx DET_EXISTENCE_PROB_077_Rx DET_SNR_077_Rx DET_SUPER_RES_TARGET_077_Rx DET_BI_STATIC_FLAG_077_Rx DET_RCS_077_Rx DET_ELEVATION_ERR_077_Rx DET_ELEVATION_077_Rx DET_AZIMUTH_ERR_077_Rx DET_AZIMUTH_077_Rx DET_RANGE_VELOCITY_ERR_077_Rx DET_RANGE_VELOCITY_077_Rx DET_RANGE_ERR_077_Rx DET_RANGE_077_Rx DET_CONFD_ELEVATION_078_Rx DET_CONFD_AZIMUTH_078_Rx DET_HVC_FLAG_078_Rx DET_EXISTENCE_PROB_078_Rx DET_SNR_078_Rx DET_SUPER_RES_TARGET_078_Rx DET_BI_STATIC_FLAG_078_Rx DET_RCS_078_Rx DET_ELEVATION_ERR_078_Rx DET_ELEVATION_078_Rx DET_AZIMUTH_ERR_078_Rx DET_AZIMUTH_078_Rx DET_RANGE_VELOCITY_ERR_078_Rx DET_RANGE_VELOCITY_078_Rx DET_RANGE_ERR_078_Rx DET_RANGE_078_Rx DET_CONFD_ELEVATION_079_Rx DET_CONFD_AZIMUTH_079_Rx DET_HVC_FLAG_079_Rx DET_EXISTENCE_PROB_079_Rx DET_SNR_079_Rx DET_SUPER_RES_TARGET_079_Rx DET_BI_STATIC_FLAG_079_Rx DET_RCS_079_Rx DET_ELEVATION_ERR_079_Rx DET_ELEVATION_079_Rx DET_AZIMUTH_ERR_079_Rx DET_AZIMUTH_079_Rx DET_RANGE_VELOCITY_ERR_079_Rx DET_RANGE_VELOCITY_079_Rx DET_RANGE_ERR_079_Rx DET_RANGE_079_Rx DET_CONFD_ELEVATION_080_Rx DET_CONFD_AZIMUTH_080_Rx DET_HVC_FLAG_080_Rx DET_EXISTENCE_PROB_080_Rx DET_SNR_080_Rx DET_SUPER_RES_TARGET_080_Rx DET_BI_STATIC_FLAG_080_Rx DET_RCS_080_Rx DET_ELEVATION_ERR_080_Rx DET_ELEVATION_080_Rx DET_AZIMUTH_ERR_080_Rx DET_AZIMUTH_080_Rx DET_RANGE_VELOCITY_ERR_080_Rx DET_RANGE_VELOCITY_080_Rx DET_RANGE_ERR_080_Rx DET_RANGE_080_Rx;
SIG_GROUP_ 276 Fusion_Detections_081_084 1 : DET_PROB_1STAZHYPO_081_Rx DET_PROB_1STAZHYPO_082_Rx DET_PROB_1STAZHYPO_083_Rx DET_PROB_1STAZHYPO_084_Rx DET_IDM_081_Rx DET_IDM_082_Rx DET_IDM_083_Rx DET_IDM_084_Rx DET_MTD_084_Rx DET_MTD_083_Rx DET_MTD_082_Rx DET_MTD_081_Rx DET_BELOW_RAIN_THOLD_084_Rx DET_BELOW_RAIN_THOLD_083_Rx DET_BELOW_RAIN_THOLD_082_Rx DET_BELOW_RAIN_THOLD_081_Rx DET_MH_CRC16_081_084_Rx DET_MH_CYCLE_COUNTER_081_084_Rx DET_MH_SCAN_INDEX_4LSB_081_084_R DET_CONFD_ELEVATION_081_Rx DET_CONFD_AZIMUTH_081_Rx DET_HVC_FLAG_081_Rx DET_EXISTENCE_PROB_081_Rx DET_SNR_081_Rx DET_SUPER_RES_TARGET_081_Rx DET_BI_STATIC_FLAG_081_Rx DET_RCS_081_Rx DET_ELEVATION_ERR_081_Rx DET_ELEVATION_081_Rx DET_AZIMUTH_ERR_081_Rx DET_AZIMUTH_081_Rx DET_RANGE_VELOCITY_ERR_081_Rx DET_RANGE_VELOCITY_081_Rx DET_RANGE_ERR_081_Rx DET_RANGE_081_Rx DET_CONFD_ELEVATION_082_Rx DET_CONFD_AZIMUTH_082_Rx DET_HVC_FLAG_082_Rx DET_EXISTENCE_PROB_082_Rx DET_SNR_082_Rx DET_SUPER_RES_TARGET_082_Rx DET_BI_STATIC_FLAG_082_Rx DET_RCS_082_Rx DET_ELEVATION_ERR_082_Rx DET_ELEVATION_082_Rx DET_AZIMUTH_ERR_082_Rx DET_AZIMUTH_082_Rx DET_RANGE_VELOCITY_ERR_082_Rx DET_RANGE_VELOCITY_082_Rx DET_RANGE_ERR_082_Rx DET_RANGE_082_Rx DET_CONFD_ELEVATION_083_Rx DET_CONFD_AZIMUTH_083_Rx DET_HVC_FLAG_083_Rx DET_EXISTENCE_PROB_083_Rx DET_SNR_083_Rx DET_SUPER_RES_TARGET_083_Rx DET_BI_STATIC_FLAG_083_Rx DET_RCS_083_Rx DET_ELEVATION_ERR_083_Rx DET_ELEVATION_083_Rx DET_AZIMUTH_ERR_083_Rx DET_AZIMUTH_083_Rx DET_RANGE_VELOCITY_ERR_083_Rx DET_RANGE_VELOCITY_083_Rx DET_RANGE_ERR_083_Rx DET_RANGE_083_Rx DET_CONFD_ELEVATION_084_Rx DET_CONFD_AZIMUTH_084_Rx DET_HVC_FLAG_084_Rx DET_EXISTENCE_PROB_084_Rx DET_SNR_084_Rx DET_SUPER_RES_TARGET_084_Rx DET_BI_STATIC_FLAG_084_Rx DET_RCS_084_Rx DET_ELEVATION_ERR_084_Rx DET_ELEVATION_084_Rx DET_AZIMUTH_ERR_084_Rx DET_AZIMUTH_084_Rx DET_RANGE_VELOCITY_ERR_084_Rx DET_RANGE_VELOCITY_084_Rx DET_RANGE_ERR_084_Rx DET_RANGE_084_Rx;
SIG_GROUP_ 277 Fusion_Detections_085_088 1 : DET_PROB_1STAZHYPO_085_Rx DET_PROB_1STAZHYPO_086_Rx DET_PROB_1STAZHYPO_087_Rx DET_PROB_1STAZHYPO_088_Rx DET_IDM_085_Rx DET_IDM_086_Rx DET_IDM_087_Rx DET_IDM_088_Rx DET_MTD_088_Rx DET_MTD_087_Rx DET_MTD_086_Rx DET_MTD_085_Rx DET_BELOW_RAIN_THOLD_088_Rx DET_BELOW_RAIN_THOLD_087_Rx DET_BELOW_RAIN_THOLD_086_Rx DET_BELOW_RAIN_THOLD_085_Rx DET_MH_CRC16_085_088_Rx DET_MH_CYCLE_COUNTER_085_088_Rx DET_MH_SCAN_INDEX_4LSB_085_088_R DET_CONFD_ELEVATION_085_Rx DET_CONFD_AZIMUTH_085_Rx DET_HVC_FLAG_085_Rx DET_EXISTENCE_PROB_085_Rx DET_SNR_085_Rx DET_SUPER_RES_TARGET_085_Rx DET_BI_STATIC_FLAG_085_Rx DET_RCS_085_Rx DET_ELEVATION_ERR_085_Rx DET_ELEVATION_085_Rx DET_AZIMUTH_ERR_085_Rx DET_AZIMUTH_085_Rx DET_RANGE_VELOCITY_ERR_085_Rx DET_RANGE_VELOCITY_085_Rx DET_RANGE_ERR_085_Rx DET_RANGE_085_Rx DET_CONFD_ELEVATION_086_Rx DET_CONFD_AZIMUTH_086_Rx DET_HVC_FLAG_086_Rx DET_EXISTENCE_PROB_086_Rx DET_SNR_086_Rx DET_SUPER_RES_TARGET_086_Rx DET_BI_STATIC_FLAG_086_Rx DET_RCS_086_Rx DET_ELEVATION_ERR_086_Rx DET_ELEVATION_086_Rx DET_AZIMUTH_ERR_086_Rx DET_AZIMUTH_086_Rx DET_RANGE_VELOCITY_ERR_086_Rx DET_RANGE_VELOCITY_086_Rx DET_RANGE_ERR_086_Rx DET_RANGE_086_Rx DET_CONFD_ELEVATION_087_Rx DET_CONFD_AZIMUTH_087_Rx DET_HVC_FLAG_087_Rx DET_EXISTENCE_PROB_087_Rx DET_SNR_087_Rx DET_SUPER_RES_TARGET_087_Rx DET_BI_STATIC_FLAG_087_Rx DET_RCS_087_Rx DET_ELEVATION_ERR_087_Rx DET_ELEVATION_087_Rx DET_AZIMUTH_ERR_087_Rx DET_AZIMUTH_087_Rx DET_RANGE_VELOCITY_ERR_087_Rx DET_RANGE_VELOCITY_087_Rx DET_RANGE_ERR_087_Rx DET_RANGE_087_Rx DET_CONFD_ELEVATION_088_Rx DET_CONFD_AZIMUTH_088_Rx DET_HVC_FLAG_088_Rx DET_EXISTENCE_PROB_088_Rx DET_SNR_088_Rx DET_SUPER_RES_TARGET_088_Rx DET_BI_STATIC_FLAG_088_Rx DET_RCS_088_Rx DET_ELEVATION_ERR_088_Rx DET_ELEVATION_088_Rx DET_AZIMUTH_ERR_088_Rx DET_AZIMUTH_088_Rx DET_RANGE_VELOCITY_ERR_088_Rx DET_RANGE_VELOCITY_088_Rx DET_RANGE_ERR_088_Rx DET_RANGE_088_Rx;
SIG_GROUP_ 278 Fusion_Detections_089_092 1 : DET_PROB_1STAZHYPO_089_Rx DET_PROB_1STAZHYPO_090_Rx DET_PROB_1STAZHYPO_091_Rx DET_PROB_1STAZHYPO_092_Rx DET_IDM_089_Rx DET_IDM_090_Rx DET_IDM_091_Rx DET_IDM_092_Rx DET_MTD_092_Rx DET_MTD_091_Rx DET_MTD_090_Rx DET_MTD_089_Rx DET_BELOW_RAIN_THOLD_092_Rx DET_BELOW_RAIN_THOLD_091_Rx DET_BELOW_RAIN_THOLD_090_Rx DET_BELOW_RAIN_THOLD_089_Rx DET_MH_CRC16_089_092_Rx DET_MH_CYCLE_COUNTER_089_092_Rx DET_MH_SCAN_INDEX_4LSB_089_092_R DET_CONFD_ELEVATION_089_Rx DET_CONFD_AZIMUTH_089_Rx DET_HVC_FLAG_089_Rx DET_EXISTENCE_PROB_089_Rx DET_SNR_089_Rx DET_SUPER_RES_TARGET_089_Rx DET_BI_STATIC_FLAG_089_Rx DET_RCS_089_Rx DET_ELEVATION_ERR_089_Rx DET_ELEVATION_089_Rx DET_AZIMUTH_ERR_089_Rx DET_AZIMUTH_089_Rx DET_RANGE_VELOCITY_ERR_089_Rx DET_RANGE_VELOCITY_089_Rx DET_RANGE_ERR_089_Rx DET_RANGE_089_Rx DET_CONFD_ELEVATION_090_Rx DET_CONFD_AZIMUTH_090_Rx DET_HVC_FLAG_090_Rx DET_EXISTENCE_PROB_090_Rx DET_SNR_090_Rx DET_SUPER_RES_TARGET_090_Rx DET_BI_STATIC_FLAG_090_Rx DET_RCS_090_Rx DET_ELEVATION_ERR_090_Rx DET_ELEVATION_090_Rx DET_AZIMUTH_ERR_090_Rx DET_AZIMUTH_090_Rx DET_RANGE_VELOCITY_ERR_090_Rx DET_RANGE_VELOCITY_090_Rx DET_RANGE_ERR_090_Rx DET_RANGE_090_Rx DET_CONFD_ELEVATION_091_Rx DET_CONFD_AZIMUTH_091_Rx DET_HVC_FLAG_091_Rx DET_EXISTENCE_PROB_091_Rx DET_SNR_091_Rx DET_SUPER_RES_TARGET_091_Rx DET_BI_STATIC_FLAG_091_Rx DET_RCS_091_Rx DET_ELEVATION_ERR_091_Rx DET_ELEVATION_091_Rx DET_AZIMUTH_ERR_091_Rx DET_AZIMUTH_091_Rx DET_RANGE_VELOCITY_ERR_091_Rx DET_RANGE_VELOCITY_091_Rx DET_RANGE_ERR_091_Rx DET_RANGE_091_Rx DET_CONFD_ELEVATION_092_Rx DET_CONFD_AZIMUTH_092_Rx DET_HVC_FLAG_092_Rx DET_EXISTENCE_PROB_092_Rx DET_SNR_092_Rx DET_SUPER_RES_TARGET_092_Rx DET_BI_STATIC_FLAG_092_Rx DET_RCS_092_Rx DET_ELEVATION_ERR_092_Rx DET_ELEVATION_092_Rx DET_AZIMUTH_ERR_092_Rx DET_AZIMUTH_092_Rx DET_RANGE_VELOCITY_ERR_092_Rx DET_RANGE_VELOCITY_092_Rx DET_RANGE_ERR_092_Rx DET_RANGE_092_Rx;
SIG_GROUP_ 279 Fusion_Detections_093_096 1 : DET_PROB_1STAZHYPO_093_Rx DET_PROB_1STAZHYPO_094_Rx DET_PROB_1STAZHYPO_095_Rx DET_PROB_1STAZHYPO_096_Rx DET_IDM_093_Rx DET_IDM_094_Rx DET_IDM_095_Rx DET_IDM_096_Rx DET_MTD_096_Rx DET_MTD_095_Rx DET_MTD_094_Rx DET_MTD_093_Rx DET_BELOW_RAIN_THOLD_096_Rx DET_BELOW_RAIN_THOLD_095_Rx DET_BELOW_RAIN_THOLD_094_Rx DET_BELOW_RAIN_THOLD_093_Rx DET_MH_CRC16_093_096_Rx DET_MH_CYCLE_COUNTER_093_096_Rx DET_MH_SCAN_INDEX_4LSB_093_096_R DET_CONFD_ELEVATION_093_Rx DET_CONFD_AZIMUTH_093_Rx DET_HVC_FLAG_093_Rx DET_EXISTENCE_PROB_093_Rx DET_SNR_093_Rx DET_SUPER_RES_TARGET_093_Rx DET_BI_STATIC_FLAG_093_Rx DET_RCS_093_Rx DET_ELEVATION_ERR_093_Rx DET_ELEVATION_093_Rx DET_AZIMUTH_ERR_093_Rx DET_AZIMUTH_093_Rx DET_RANGE_VELOCITY_ERR_093_Rx DET_RANGE_VELOCITY_093_Rx DET_RANGE_ERR_093_Rx DET_RANGE_093_Rx DET_CONFD_ELEVATION_094_Rx DET_CONFD_AZIMUTH_094_Rx DET_HVC_FLAG_094_Rx DET_EXISTENCE_PROB_094_Rx DET_SNR_094_Rx DET_SUPER_RES_TARGET_094_Rx DET_BI_STATIC_FLAG_094_Rx DET_RCS_094_Rx DET_ELEVATION_ERR_094_Rx DET_ELEVATION_094_Rx DET_AZIMUTH_ERR_094_Rx DET_AZIMUTH_094_Rx DET_RANGE_VELOCITY_ERR_094_Rx DET_RANGE_VELOCITY_094_Rx DET_RANGE_ERR_094_Rx DET_RANGE_094_Rx DET_CONFD_ELEVATION_095_Rx DET_CONFD_AZIMUTH_095_Rx DET_HVC_FLAG_095_Rx DET_EXISTENCE_PROB_095_Rx DET_SNR_095_Rx DET_SUPER_RES_TARGET_095_Rx DET_BI_STATIC_FLAG_095_Rx DET_RCS_095_Rx DET_ELEVATION_ERR_095_Rx DET_ELEVATION_095_Rx DET_AZIMUTH_ERR_095_Rx DET_AZIMUTH_095_Rx DET_RANGE_VELOCITY_ERR_095_Rx DET_RANGE_VELOCITY_095_Rx DET_RANGE_ERR_095_Rx DET_RANGE_095_Rx DET_CONFD_ELEVATION_096_Rx DET_CONFD_AZIMUTH_096_Rx DET_HVC_FLAG_096_Rx DET_EXISTENCE_PROB_096_Rx DET_SNR_096_Rx DET_SUPER_RES_TARGET_096_Rx DET_BI_STATIC_FLAG_096_Rx DET_RCS_096_Rx DET_ELEVATION_ERR_096_Rx DET_ELEVATION_096_Rx DET_AZIMUTH_ERR_096_Rx DET_AZIMUTH_096_Rx DET_RANGE_VELOCITY_ERR_096_Rx DET_RANGE_VELOCITY_096_Rx DET_RANGE_ERR_096_Rx DET_RANGE_096_Rx;
SIG_GROUP_ 280 Fusion_Detections_097_100 1 : DET_PROB_1STAZHYPO_097_Rx DET_PROB_1STAZHYPO_098_Rx DET_PROB_1STAZHYPO_099_Rx DET_PROB_1STAZHYPO_100_Rx DET_IDM_097_Rx DET_IDM_098_Rx DET_IDM_099_Rx DET_IDM_100_Rx DET_MTD_100_Rx DET_MTD_099_Rx DET_MTD_098_Rx DET_MTD_097_Rx DET_BELOW_RAIN_THOLD_100_Rx DET_BELOW_RAIN_THOLD_099_Rx DET_BELOW_RAIN_THOLD_098_Rx DET_BELOW_RAIN_THOLD_097_Rx DET_MH_CRC16_097_100_Rx DET_MH_CYCLE_COUNTER_097_100_Rx DET_MH_SCAN_INDEX_4LSB_097_100_R DET_CONFD_ELEVATION_097_Rx DET_CONFD_AZIMUTH_097_Rx DET_HVC_FLAG_097_Rx DET_EXISTENCE_PROB_097_Rx DET_SNR_097_Rx DET_SUPER_RES_TARGET_097_Rx DET_BI_STATIC_FLAG_097_Rx DET_RCS_097_Rx DET_ELEVATION_ERR_097_Rx DET_ELEVATION_097_Rx DET_AZIMUTH_ERR_097_Rx DET_AZIMUTH_097_Rx DET_RANGE_VELOCITY_ERR_097_Rx DET_RANGE_VELOCITY_097_Rx DET_RANGE_ERR_097_Rx DET_RANGE_097_Rx DET_CONFD_ELEVATION_098_Rx DET_CONFD_AZIMUTH_098_Rx DET_HVC_FLAG_098_Rx DET_EXISTENCE_PROB_098_Rx DET_SNR_098_Rx DET_SUPER_RES_TARGET_098_Rx DET_BI_STATIC_FLAG_098_Rx DET_RCS_098_Rx DET_ELEVATION_ERR_098_Rx DET_ELEVATION_098_Rx DET_AZIMUTH_ERR_098_Rx DET_AZIMUTH_098_Rx DET_RANGE_VELOCITY_ERR_098_Rx DET_RANGE_VELOCITY_098_Rx DET_RANGE_ERR_098_Rx DET_RANGE_098_Rx DET_CONFD_ELEVATION_099_Rx DET_CONFD_AZIMUTH_099_Rx DET_HVC_FLAG_099_Rx DET_EXISTENCE_PROB_099_Rx DET_SNR_099_Rx DET_SUPER_RES_TARGET_099_Rx DET_BI_STATIC_FLAG_099_Rx DET_RCS_099_Rx DET_ELEVATION_ERR_099_Rx DET_ELEVATION_099_Rx DET_AZIMUTH_ERR_099_Rx DET_AZIMUTH_099_Rx DET_RANGE_VELOCITY_ERR_099_Rx DET_RANGE_VELOCITY_099_Rx DET_RANGE_ERR_099_Rx DET_RANGE_099_Rx DET_CONFD_ELEVATION_100_Rx DET_CONFD_AZIMUTH_100_Rx DET_HVC_FLAG_100_Rx DET_EXISTENCE_PROB_100_Rx DET_SNR_100_Rx DET_SUPER_RES_TARGET_100_Rx DET_BI_STATIC_FLAG_100_Rx DET_RCS_100_Rx DET_ELEVATION_ERR_100_Rx DET_ELEVATION_100_Rx DET_AZIMUTH_ERR_100_Rx DET_AZIMUTH_100_Rx DET_RANGE_VELOCITY_ERR_100_Rx DET_RANGE_VELOCITY_100_Rx DET_RANGE_ERR_100_Rx DET_RANGE_100_Rx;
SIG_GROUP_ 281 Fusion_Detections_101_104 1 : DET_PROB_1STAZHYPO_101_Rx DET_PROB_1STAZHYPO_102_Rx DET_PROB_1STAZHYPO_103_Rx DET_PROB_1STAZHYPO_104_Rx DET_IDM_101_Rx DET_IDM_102_Rx DET_IDM_103_Rx DET_IDM_104_Rx DET_MTD_104_Rx DET_MTD_103_Rx DET_MTD_102_Rx DET_MTD_101_Rx DET_BELOW_RAIN_THOLD_104_Rx DET_BELOW_RAIN_THOLD_103_Rx DET_BELOW_RAIN_THOLD_102_Rx DET_BELOW_RAIN_THOLD_101_Rx DET_MH_CRC16_101_104_Rx DET_MH_CYCLE_COUNTER_101_104_Rx DET_MH_SCAN_INDEX_4LSB_101_104_R DET_CONFD_ELEVATION_101_Rx DET_CONFD_AZIMUTH_101_Rx DET_HVC_FLAG_101_Rx DET_EXISTENCE_PROB_101_Rx DET_SNR_101_Rx DET_SUPER_RES_TARGET_101_Rx DET_BI_STATIC_FLAG_101_Rx DET_RCS_101_Rx DET_ELEVATION_ERR_101_Rx DET_ELEVATION_101_Rx DET_AZIMUTH_ERR_101_Rx DET_AZIMUTH_101_Rx DET_RANGE_VELOCITY_ERR_101_Rx DET_RANGE_VELOCITY_101_Rx DET_RANGE_ERR_101_Rx DET_RANGE_101_Rx DET_CONFD_ELEVATION_102_Rx DET_CONFD_AZIMUTH_102_Rx DET_HVC_FLAG_102_Rx DET_EXISTENCE_PROB_102_Rx DET_SNR_102_Rx DET_SUPER_RES_TARGET_102_Rx DET_BI_STATIC_FLAG_102_Rx DET_RCS_102_Rx DET_ELEVATION_ERR_102_Rx DET_ELEVATION_102_Rx DET_AZIMUTH_ERR_102_Rx DET_AZIMUTH_102_Rx DET_RANGE_VELOCITY_ERR_102_Rx DET_RANGE_VELOCITY_102_Rx DET_RANGE_ERR_102_Rx DET_RANGE_102_Rx DET_CONFD_ELEVATION_103_Rx DET_CONFD_AZIMUTH_103_Rx DET_HVC_FLAG_103_Rx DET_EXISTENCE_PROB_103_Rx DET_SNR_103_Rx DET_SUPER_RES_TARGET_103_Rx DET_BI_STATIC_FLAG_103_Rx DET_RCS_103_Rx DET_ELEVATION_ERR_103_Rx DET_ELEVATION_103_Rx DET_AZIMUTH_ERR_103_Rx DET_AZIMUTH_103_Rx DET_RANGE_VELOCITY_ERR_103_Rx DET_RANGE_VELOCITY_103_Rx DET_RANGE_ERR_103_Rx DET_RANGE_103_Rx DET_CONFD_ELEVATION_104_Rx DET_CONFD_AZIMUTH_104_Rx DET_HVC_FLAG_104_Rx DET_EXISTENCE_PROB_104_Rx DET_SNR_104_Rx DET_SUPER_RES_TARGET_104_Rx DET_BI_STATIC_FLAG_104_Rx DET_RCS_104_Rx DET_ELEVATION_ERR_104_Rx DET_ELEVATION_104_Rx DET_AZIMUTH_ERR_104_Rx DET_AZIMUTH_104_Rx DET_RANGE_VELOCITY_ERR_104_Rx DET_RANGE_VELOCITY_104_Rx DET_RANGE_ERR_104_Rx DET_RANGE_104_Rx;
SIG_GROUP_ 282 Fusion_Detections_105_108 1 : DET_PROB_1STAZHYPO_105_Rx DET_PROB_1STAZHYPO_106_Rx DET_PROB_1STAZHYPO_107_Rx DET_PROB_1STAZHYPO_108_Rx DET_IDM_105_Rx DET_IDM_106_Rx DET_IDM_107_Rx DET_IDM_108_Rx DET_MTD_108_Rx DET_MTD_107_Rx DET_MTD_106_Rx DET_MTD_105_Rx DET_BELOW_RAIN_THOLD_108_Rx DET_BELOW_RAIN_THOLD_107_Rx DET_BELOW_RAIN_THOLD_106_Rx DET_BELOW_RAIN_THOLD_105_Rx DET_MH_CRC16_105_108_Rx DET_MH_CYCLE_COUNTER_105_108_Rx DET_MH_SCAN_INDEX_4LSB_105_108_R DET_CONFD_ELEVATION_105_Rx DET_CONFD_AZIMUTH_105_Rx DET_HVC_FLAG_105_Rx DET_EXISTENCE_PROB_105_Rx DET_SNR_105_Rx DET_SUPER_RES_TARGET_105_Rx DET_BI_STATIC_FLAG_105_Rx DET_RCS_105_Rx DET_ELEVATION_ERR_105_Rx DET_ELEVATION_105_Rx DET_AZIMUTH_ERR_105_Rx DET_AZIMUTH_105_Rx DET_RANGE_VELOCITY_ERR_105_Rx DET_RANGE_VELOCITY_105_Rx DET_RANGE_ERR_105_Rx DET_RANGE_105_Rx DET_CONFD_ELEVATION_106_Rx DET_CONFD_AZIMUTH_106_Rx DET_HVC_FLAG_106_Rx DET_EXISTENCE_PROB_106_Rx DET_SNR_106_Rx DET_SUPER_RES_TARGET_106_Rx DET_BI_STATIC_FLAG_106_Rx DET_RCS_106_Rx DET_ELEVATION_ERR_106_Rx DET_ELEVATION_106_Rx DET_AZIMUTH_ERR_106_Rx DET_AZIMUTH_106_Rx DET_RANGE_VELOCITY_ERR_106_Rx DET_RANGE_VELOCITY_106_Rx DET_RANGE_ERR_106_Rx DET_RANGE_106_Rx DET_CONFD_ELEVATION_107_Rx DET_CONFD_AZIMUTH_107_Rx DET_HVC_FLAG_107_Rx DET_EXISTENCE_PROB_107_Rx DET_SNR_107_Rx DET_SUPER_RES_TARGET_107_Rx DET_BI_STATIC_FLAG_107_Rx DET_RCS_107_Rx DET_ELEVATION_ERR_107_Rx DET_ELEVATION_107_Rx DET_AZIMUTH_ERR_107_Rx DET_AZIMUTH_107_Rx DET_RANGE_VELOCITY_ERR_107_Rx DET_RANGE_VELOCITY_107_Rx DET_RANGE_ERR_107_Rx DET_RANGE_107_Rx DET_CONFD_ELEVATION_108_Rx DET_CONFD_AZIMUTH_108_Rx DET_HVC_FLAG_108_Rx DET_EXISTENCE_PROB_108_Rx DET_SNR_108_Rx DET_SUPER_RES_TARGET_108_Rx DET_BI_STATIC_FLAG_108_Rx DET_RCS_108_Rx DET_ELEVATION_ERR_108_Rx DET_ELEVATION_108_Rx DET_AZIMUTH_ERR_108_Rx DET_AZIMUTH_108_Rx DET_RANGE_VELOCITY_ERR_108_Rx DET_RANGE_VELOCITY_108_Rx DET_RANGE_ERR_108_Rx DET_RANGE_108_Rx;
SIG_GROUP_ 283 Fusion_Detections_109_112 1 : DET_PROB_1STAZHYPO_109_Rx DET_PROB_1STAZHYPO_110_Rx DET_PROB_1STAZHYPO_111_Rx DET_PROB_1STAZHYPO_112_Rx DET_IDM_109_Rx DET_IDM_110_Rx DET_IDM_111_Rx DET_IDM_112_Rx DET_MTD_112_Rx DET_MTD_111_Rx DET_MTD_110_Rx DET_MTD_109_Rx DET_BELOW_RAIN_THOLD_112_Rx DET_BELOW_RAIN_THOLD_111_Rx DET_BELOW_RAIN_THOLD_110_Rx DET_BELOW_RAIN_THOLD_109_Rx DET_MH_CRC16_109_112_Rx DET_MH_CYCLE_COUNTER_109_112_Rx DET_MH_SCAN_INDEX_4LSB_109_112_R DET_CONFD_ELEVATION_109_Rx DET_CONFD_AZIMUTH_109_Rx DET_HVC_FLAG_109_Rx DET_EXISTENCE_PROB_109_Rx DET_SNR_109_Rx DET_SUPER_RES_TARGET_109_Rx DET_BI_STATIC_FLAG_109_Rx DET_RCS_109_Rx DET_ELEVATION_ERR_109_Rx DET_ELEVATION_109_Rx DET_AZIMUTH_ERR_109_Rx DET_AZIMUTH_109_Rx DET_RANGE_VELOCITY_ERR_109_Rx DET_RANGE_VELOCITY_109_Rx DET_RANGE_ERR_109_Rx DET_RANGE_109_Rx DET_CONFD_ELEVATION_110_Rx DET_CONFD_AZIMUTH_110_Rx DET_HVC_FLAG_110_Rx DET_EXISTENCE_PROB_110_Rx DET_SNR_110_Rx DET_SUPER_RES_TARGET_110_Rx DET_BI_STATIC_FLAG_110_Rx DET_RCS_110_Rx DET_ELEVATION_ERR_110_Rx DET_ELEVATION_110_Rx DET_AZIMUTH_ERR_110_Rx DET_AZIMUTH_110_Rx DET_RANGE_VELOCITY_ERR_110_Rx DET_RANGE_VELOCITY_110_Rx DET_RANGE_ERR_110_Rx DET_RANGE_110_Rx DET_CONFD_ELEVATION_111_Rx DET_CONFD_AZIMUTH_111_Rx DET_HVC_FLAG_111_Rx DET_EXISTENCE_PROB_111_Rx DET_SNR_111_Rx DET_SUPER_RES_TARGET_111_Rx DET_BI_STATIC_FLAG_111_Rx DET_RCS_111_Rx DET_ELEVATION_ERR_111_Rx DET_ELEVATION_111_Rx DET_AZIMUTH_ERR_111_Rx DET_AZIMUTH_111_Rx DET_RANGE_VELOCITY_ERR_111_Rx DET_RANGE_VELOCITY_111_Rx DET_RANGE_ERR_111_Rx DET_RANGE_111_Rx DET_CONFD_ELEVATION_112_Rx DET_CONFD_AZIMUTH_112_Rx DET_HVC_FLAG_112_Rx DET_EXISTENCE_PROB_112_Rx DET_SNR_112_Rx DET_SUPER_RES_TARGET_112_Rx DET_BI_STATIC_FLAG_112_Rx DET_RCS_112_Rx DET_ELEVATION_ERR_112_Rx DET_ELEVATION_112_Rx DET_AZIMUTH_ERR_112_Rx DET_AZIMUTH_112_Rx DET_RANGE_VELOCITY_ERR_112_Rx DET_RANGE_VELOCITY_112_Rx DET_RANGE_ERR_112_Rx DET_RANGE_112_Rx;
SIG_GROUP_ 284 Fusion_Detections_113_116 1 : DET_PROB_1STAZHYPO_113_Rx DET_PROB_1STAZHYPO_114_Rx DET_PROB_1STAZHYPO_115_Rx DET_PROB_1STAZHYPO_116_Rx DET_IDM_113_Rx DET_IDM_114_Rx DET_IDM_115_Rx DET_IDM_116_Rx DET_MTD_116_Rx DET_MTD_115_Rx DET_MTD_114_Rx DET_MTD_113_Rx DET_BELOW_RAIN_THOLD_116_Rx DET_BELOW_RAIN_THOLD_115_Rx DET_BELOW_RAIN_THOLD_114_Rx DET_BELOW_RAIN_THOLD_113_Rx DET_MH_CRC16_113_116_Rx DET_MH_CYCLE_COUNTER_113_116_Rx DET_MH_SCAN_INDEX_4LSB_113_116_R DET_CONFD_ELEVATION_113_Rx DET_CONFD_AZIMUTH_113_Rx DET_HVC_FLAG_113_Rx DET_EXISTENCE_PROB_113_Rx DET_SNR_113_Rx DET_SUPER_RES_TARGET_113_Rx DET_BI_STATIC_FLAG_113_Rx DET_RCS_113_Rx DET_ELEVATION_ERR_113_Rx DET_ELEVATION_113_Rx DET_AZIMUTH_ERR_113_Rx DET_AZIMUTH_113_Rx DET_RANGE_VELOCITY_ERR_113_Rx DET_RANGE_VELOCITY_113_Rx DET_RANGE_ERR_113_Rx DET_RANGE_113_Rx DET_CONFD_ELEVATION_114_Rx DET_CONFD_AZIMUTH_114_Rx DET_HVC_FLAG_114_Rx DET_EXISTENCE_PROB_114_Rx DET_SNR_114_Rx DET_SUPER_RES_TARGET_114_Rx DET_BI_STATIC_FLAG_114_Rx DET_RCS_114_Rx DET_ELEVATION_ERR_114_Rx DET_ELEVATION_114_Rx DET_AZIMUTH_ERR_114_Rx DET_AZIMUTH_114_Rx DET_RANGE_VELOCITY_ERR_114_Rx DET_RANGE_VELOCITY_114_Rx DET_RANGE_ERR_114_Rx DET_RANGE_114_Rx DET_CONFD_ELEVATION_115_Rx DET_CONFD_AZIMUTH_115_Rx DET_HVC_FLAG_115_Rx DET_EXISTENCE_PROB_115_Rx DET_SNR_115_Rx DET_SUPER_RES_TARGET_115_Rx DET_BI_STATIC_FLAG_115_Rx DET_RCS_115_Rx DET_ELEVATION_ERR_115_Rx DET_ELEVATION_115_Rx DET_AZIMUTH_ERR_115_Rx DET_AZIMUTH_115_Rx DET_RANGE_VELOCITY_ERR_115_Rx DET_RANGE_VELOCITY_115_Rx DET_RANGE_ERR_115_Rx DET_RANGE_115_Rx DET_CONFD_ELEVATION_116_Rx DET_CONFD_AZIMUTH_116_Rx DET_HVC_FLAG_116_Rx DET_EXISTENCE_PROB_116_Rx DET_SNR_116_Rx DET_SUPER_RES_TARGET_116_Rx DET_BI_STATIC_FLAG_116_Rx DET_RCS_116_Rx DET_ELEVATION_ERR_116_Rx DET_ELEVATION_116_Rx DET_AZIMUTH_ERR_116_Rx DET_AZIMUTH_116_Rx DET_RANGE_VELOCITY_ERR_116_Rx DET_RANGE_VELOCITY_116_Rx DET_RANGE_ERR_116_Rx DET_RANGE_116_Rx;
SIG_GROUP_ 285 Fusion_Detections_117_120 1 : DET_PROB_1STAZHYPO_117_Rx DET_PROB_1STAZHYPO_118_Rx DET_PROB_1STAZHYPO_119_Rx DET_PROB_1STAZHYPO_120_Rx DET_IDM_117_Rx DET_IDM_118_Rx DET_IDM_119_Rx DET_IDM_120_Rx DET_MTD_120_Rx DET_MTD_119_Rx DET_MTD_118_Rx DET_MTD_117_Rx DET_BELOW_RAIN_THOLD_120_Rx DET_BELOW_RAIN_THOLD_119_Rx DET_BELOW_RAIN_THOLD_118_Rx DET_BELOW_RAIN_THOLD_117_Rx DET_MH_CRC16_117_120_Rx DET_MH_CYCLE_COUNTER_117_120_Rx DET_MH_SCAN_INDEX_4LSB_117_120_R DET_CONFD_ELEVATION_117_Rx DET_CONFD_AZIMUTH_117_Rx DET_HVC_FLAG_117_Rx DET_EXISTENCE_PROB_117_Rx DET_SNR_117_Rx DET_SUPER_RES_TARGET_117_Rx DET_BI_STATIC_FLAG_117_Rx DET_RCS_117_Rx DET_ELEVATION_ERR_117_Rx DET_ELEVATION_117_Rx DET_AZIMUTH_ERR_117_Rx DET_AZIMUTH_117_Rx DET_RANGE_VELOCITY_ERR_117_Rx DET_RANGE_VELOCITY_117_Rx DET_RANGE_ERR_117_Rx DET_RANGE_117_Rx DET_CONFD_ELEVATION_118_Rx DET_CONFD_AZIMUTH_118_Rx DET_HVC_FLAG_118_Rx DET_EXISTENCE_PROB_118_Rx DET_SNR_118_Rx DET_SUPER_RES_TARGET_118_Rx DET_BI_STATIC_FLAG_118_Rx DET_RCS_118_Rx DET_ELEVATION_ERR_118_Rx DET_ELEVATION_118_Rx DET_AZIMUTH_ERR_118_Rx DET_AZIMUTH_118_Rx DET_RANGE_VELOCITY_ERR_118_Rx DET_RANGE_VELOCITY_118_Rx DET_RANGE_ERR_118_Rx DET_RANGE_118_Rx DET_CONFD_ELEVATION_119_Rx DET_CONFD_AZIMUTH_119_Rx DET_HVC_FLAG_119_Rx DET_EXISTENCE_PROB_119_Rx DET_SNR_119_Rx DET_SUPER_RES_TARGET_119_Rx DET_BI_STATIC_FLAG_119_Rx DET_RCS_119_Rx DET_ELEVATION_ERR_119_Rx DET_ELEVATION_119_Rx DET_AZIMUTH_ERR_119_Rx DET_AZIMUTH_119_Rx DET_RANGE_VELOCITY_ERR_119_Rx DET_RANGE_VELOCITY_119_Rx DET_RANGE_ERR_119_Rx DET_RANGE_119_Rx DET_CONFD_ELEVATION_120_Rx DET_CONFD_AZIMUTH_120_Rx DET_HVC_FLAG_120_Rx DET_EXISTENCE_PROB_120_Rx DET_SNR_120_Rx DET_SUPER_RES_TARGET_120_Rx DET_BI_STATIC_FLAG_120_Rx DET_RCS_120_Rx DET_ELEVATION_ERR_120_Rx DET_ELEVATION_120_Rx DET_AZIMUTH_ERR_120_Rx DET_AZIMUTH_120_Rx DET_RANGE_VELOCITY_ERR_120_Rx DET_RANGE_VELOCITY_120_Rx DET_RANGE_ERR_120_Rx DET_RANGE_120_Rx;
SIG_GROUP_ 286 Fusion_Detections_121_124 1 : DET_PROB_1STAZHYPO_121_Rx DET_PROB_1STAZHYPO_122_Rx DET_PROB_1STAZHYPO_123_Rx DET_PROB_1STAZHYPO_124_Rx DET_IDM_121_Rx DET_IDM_122_Rx DET_IDM_123_Rx DET_IDM_124_Rx DET_MTD_124_Rx DET_MTD_123_Rx DET_MTD_122_Rx DET_MTD_121_Rx DET_BELOW_RAIN_THOLD_124_Rx DET_BELOW_RAIN_THOLD_123_Rx DET_BELOW_RAIN_THOLD_122_Rx DET_BELOW_RAIN_THOLD_121_Rx DET_MH_CRC16_121_124_Rx DET_MH_CYCLE_COUNTER_121_124_Rx DET_MH_SCAN_INDEX_4LSB_121_124_R DET_CONFD_ELEVATION_121_Rx DET_CONFD_AZIMUTH_121_Rx DET_HVC_FLAG_121_Rx DET_EXISTENCE_PROB_121_Rx DET_SNR_121_Rx DET_SUPER_RES_TARGET_121_Rx DET_BI_STATIC_FLAG_121_Rx DET_RCS_121_Rx DET_ELEVATION_ERR_121_Rx DET_ELEVATION_121_Rx DET_AZIMUTH_ERR_121_Rx DET_AZIMUTH_121_Rx DET_RANGE_VELOCITY_ERR_121_Rx DET_RANGE_VELOCITY_121_Rx DET_RANGE_ERR_121_Rx DET_RANGE_121_Rx DET_CONFD_ELEVATION_122_Rx DET_CONFD_AZIMUTH_122_Rx DET_HVC_FLAG_122_Rx DET_EXISTENCE_PROB_122_Rx DET_SNR_122_Rx DET_SUPER_RES_TARGET_122_Rx DET_BI_STATIC_FLAG_122_Rx DET_RCS_122_Rx DET_ELEVATION_ERR_122_Rx DET_ELEVATION_122_Rx DET_AZIMUTH_ERR_122_Rx DET_AZIMUTH_122_Rx DET_RANGE_VELOCITY_ERR_122_Rx DET_RANGE_VELOCITY_122_Rx DET_RANGE_ERR_122_Rx DET_RANGE_122_Rx DET_CONFD_ELEVATION_123_Rx DET_CONFD_AZIMUTH_123_Rx DET_HVC_FLAG_123_Rx DET_EXISTENCE_PROB_123_Rx DET_SNR_123_Rx DET_SUPER_RES_TARGET_123_Rx DET_BI_STATIC_FLAG_123_Rx DET_RCS_123_Rx DET_ELEVATION_ERR_123_Rx DET_ELEVATION_123_Rx DET_AZIMUTH_ERR_123_Rx DET_AZIMUTH_123_Rx DET_RANGE_VELOCITY_ERR_123_Rx DET_RANGE_VELOCITY_123_Rx DET_RANGE_ERR_123_Rx DET_RANGE_123_Rx DET_CONFD_ELEVATION_124_Rx DET_CONFD_AZIMUTH_124_Rx DET_HVC_FLAG_124_Rx DET_EXISTENCE_PROB_124_Rx DET_SNR_124_Rx DET_SUPER_RES_TARGET_124_Rx DET_BI_STATIC_FLAG_124_Rx DET_RCS_124_Rx DET_ELEVATION_ERR_124_Rx DET_ELEVATION_124_Rx DET_AZIMUTH_ERR_124_Rx DET_AZIMUTH_124_Rx DET_RANGE_VELOCITY_ERR_124_Rx DET_RANGE_VELOCITY_124_Rx DET_RANGE_ERR_124_Rx DET_RANGE_124_Rx;
SIG_GROUP_ 287 Fusion_Detections_125_128 1 : DET_PROB_1STAZHYPO_125_Rx DET_PROB_1STAZHYPO_126_Rx DET_PROB_1STAZHYPO_127_Rx DET_PROB_1STAZHYPO_128_Rx DET_IDM_125_Rx DET_IDM_126_Rx DET_IDM_127_Rx DET_IDM_128_Rx DET_MTD_128_Rx DET_MTD_127_Rx DET_MTD_126_Rx DET_MTD_125_Rx DET_BELOW_RAIN_THOLD_128_Rx DET_BELOW_RAIN_THOLD_127_Rx DET_BELOW_RAIN_THOLD_126_Rx DET_BELOW_RAIN_THOLD_125_Rx DET_MH_CRC16_125_128_Rx DET_MH_CYCLE_COUNTER_125_128_Rx DET_MH_SCAN_INDEX_4LSB_125_128_R DET_CONFD_ELEVATION_125_Rx DET_CONFD_AZIMUTH_125_Rx DET_HVC_FLAG_125_Rx DET_EXISTENCE_PROB_125_Rx DET_SNR_125_Rx DET_SUPER_RES_TARGET_125_Rx DET_BI_STATIC_FLAG_125_Rx DET_RCS_125_Rx DET_ELEVATION_ERR_125_Rx DET_ELEVATION_125_Rx DET_AZIMUTH_ERR_125_Rx DET_AZIMUTH_125_Rx DET_RANGE_VELOCITY_ERR_125_Rx DET_RANGE_VELOCITY_125_Rx DET_RANGE_ERR_125_Rx DET_RANGE_125_Rx DET_CONFD_ELEVATION_126_Rx DET_CONFD_AZIMUTH_126_Rx DET_HVC_FLAG_126_Rx DET_EXISTENCE_PROB_126_Rx DET_SNR_126_Rx DET_SUPER_RES_TARGET_126_Rx DET_BI_STATIC_FLAG_126_Rx DET_RCS_126_Rx DET_ELEVATION_ERR_126_Rx DET_ELEVATION_126_Rx DET_AZIMUTH_ERR_126_Rx DET_AZIMUTH_126_Rx DET_RANGE_VELOCITY_ERR_126_Rx DET_RANGE_VELOCITY_126_Rx DET_RANGE_ERR_126_Rx DET_RANGE_126_Rx DET_CONFD_ELEVATION_127_Rx DET_CONFD_AZIMUTH_127_Rx DET_HVC_FLAG_127_Rx DET_EXISTENCE_PROB_127_Rx DET_SNR_127_Rx DET_SUPER_RES_TARGET_127_Rx DET_BI_STATIC_FLAG_127_Rx DET_RCS_127_Rx DET_ELEVATION_ERR_127_Rx DET_ELEVATION_127_Rx DET_AZIMUTH_ERR_127_Rx DET_AZIMUTH_127_Rx DET_RANGE_VELOCITY_ERR_127_Rx DET_RANGE_VELOCITY_127_Rx DET_RANGE_ERR_127_Rx DET_RANGE_127_Rx DET_CONFD_ELEVATION_128_Rx DET_CONFD_AZIMUTH_128_Rx DET_HVC_FLAG_128_Rx DET_EXISTENCE_PROB_128_Rx DET_SNR_128_Rx DET_SUPER_RES_TARGET_128_Rx DET_BI_STATIC_FLAG_128_Rx DET_RCS_128_Rx DET_ELEVATION_ERR_128_Rx DET_ELEVATION_128_Rx DET_AZIMUTH_ERR_128_Rx DET_AZIMUTH_128_Rx DET_RANGE_VELOCITY_ERR_128_Rx DET_RANGE_VELOCITY_128_Rx DET_RANGE_ERR_128_Rx DET_RANGE_128_Rx;
